VERSION ""

NS_ :

BS_:

BU_: TBOX Tester WCM MFS HUD CGW IHU

BO_ 3221225472 VECTOR__INDEPENDENT_SIG_MSG: 0 Vector__XXX
 SG_ IPM1_FLTempSwitchReq : 0|6@0+ (0.5,0) [16|30] "" Vector__XXX
 SG_ IHU_EPB_Cmd : 0|2@0+ (1,0) [0|3] "" Vector__XXX
 SG_ ABS_ESP_1_ESPSwitchStatus : 0|1@0+ (1,0) [0|1] "" Vector__XXX
 SG_ SET_Rmirror_UD_Locaton : 0|6@0+ (2,-2) [0|100] "%" Vector__XXX
 SG_ SET_Rmirror_LR_Locaton : 0|6@0+ (2,-2) [0|100] "%" Vector__XXX
 SG_ SET_Lmirror_UD_Locaton : 0|6@0+ (2,-2) [0|100] "%" Vector__XXX
 SG_ SET_Lmirror_LR_Locaton : 0|6@0+ (2,-2) [0|100] "%" Vector__XXX
 SG_ ATCM_AVM : 0|2@0+ (1,0) [0|3] "" Vector__XXX
 SG_ SET_DriverSeat_RearendUD : 0|2@0+ (1,0) [0|3] "" Vector__XXX
 SG_ SET_DriverSeat_FrontendUD : 0|2@0+ (1,0) [0|3] "" Vector__XXX
 SG_ SET_DriverSeat_BackFR : 0|2@0+ (1,0) [0|3] "" Vector__XXX
 SG_ SET_DriverSeat_FR : 0|2@0+ (1,0) [0|3] "" Vector__XXX
 SG_ RBCM_MFS_HeatSts : 0|1@0+ (1,0) [0|1] "Bit" Vector__XXX

BO_ 1360 DSM_1: 8 CGW
 SG_ SeatMemoryNO : 51|4@0+ (1,0) [0|15] ""  IHU
 SG_ DSM_2_MemorySound : 37|2@0+ (1,0) [0|3] ""  IHU
 SG_ BCM_3_Welcome_Seat_Sts : 35|2@0+ (1,0) [0|3] ""  IHU
 SG_ DSM_1_PassengerBlowSeatSts : 33|2@0+ (1,0) [0|3] ""  IHU
 SG_ SET_PassengerSeat_FrontendUD : 31|2@0+ (1,0) [0|3] ""  IHU
 SG_ SET_PassengerSeat_BackFR : 29|2@0+ (1,0) [0|3] ""  IHU
 SG_ SET_PassengerSeat_RearendUD : 27|2@0+ (1,0) [0|3] ""  IHU
 SG_ SET_PassengerSeat_FR : 25|2@0+ (1,0) [0|3] ""  IHU
 SG_ SET_DriverSeat_FrontendUD : 23|2@0+ (1,0) [0|3] ""  IHU
 SG_ SET_DriverSeat_BackFR : 21|2@0+ (1,0) [0|3] ""  IHU
 SG_ SET_DriverSeat_RearendUD : 19|2@0+ (1,0) [0|3] ""  IHU
 SG_ SET_DriverSeat_FR : 17|2@0+ (1,0) [0|3] ""  IHU
 SG_ Reserved : 15|4@0+ (1,0) [0|15] ""  IHU
 SG_ DSM_1_DeletePeronalSet_FB : 11|4@0+ (1,0) [0|15] ""  IHU
 SG_ DSM_1_PersonalSeatEn : 7|2@0+ (1,0) [0|3] ""  IHU
 SG_ DSM_1_PassengerHeatSeatSts : 5|2@0+ (1,0) [0|3] ""  IHU
 SG_ DSM_1_DriverBlowSeatSts : 3|2@0+ (1,0) [0|3] ""  IHU
 SG_ DSM_1_DriverHeatSeatSts : 1|2@0+ (1,0) [0|3] ""  IHU

BO_ 1313 TBOX_3: 3 CGW
 SG_ TBOX_3_RemotePhotograph : 3|2@0+ (1,0) [0|3] ""  IHU

BO_ 936 BCM_13: 8 CGW
 SG_ EBS_SOC : 23|8@0+ (1,0) [0|255] ""  IHU

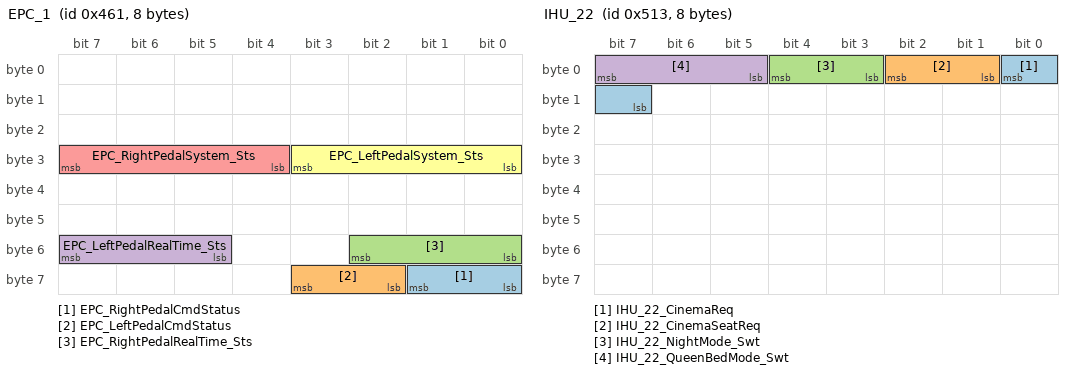
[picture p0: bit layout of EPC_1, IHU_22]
BO_ 1121 EPC_1: 8 CGW
 SG_ EPC_RightPedalCmdStatus : 57|2@0+ (1,0) [0|3] ""  IHU
 SG_ EPC_LeftPedalCmdStatus : 59|2@0+ (1,0) [0|3] ""  IHU
 SG_ EPC_RightPedalRealTime_Sts : 50|3@0+ (1,0) [0|7] ""  IHU
 SG_ EPC_LeftPedalRealTime_Sts : 55|3@0+ (1,0) [0|7] ""  IHU
 SG_ EPC_RightPedalSystem_Sts : 31|4@0+ (1,0) [0|15] ""  IHU
 SG_ EPC_LeftPedalSystem_Sts : 27|4@0+ (1,0) [0|15] ""  IHU

BO_ 916 BCM_1: 8 CGW
 SG_ Wash_Car_Status : 41|2@0+ (1,0) [0|3] ""  IHU

BO_ 1299 IHU_22: 8 IHU
 SG_ IHU_22_CinemaReq : 0|2@0+ (1,0) [0|3] ""  IHU
 SG_ IHU_22_CinemaSeatReq : 2|2@0+ (1,0) [0|3] ""  CGW
 SG_ IHU_22_NightMode_Swt : 4|2@0+ (1,0) [0|3] ""  CGW
 SG_ IHU_22_QueenBedMode_Swt : 7|3@0+ (1,0) [0|7] ""  CGW

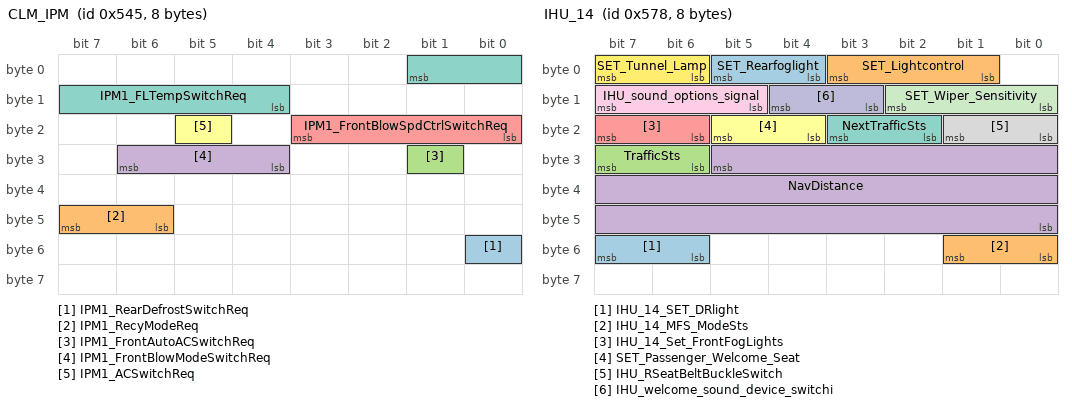
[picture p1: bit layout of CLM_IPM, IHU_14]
BO_ 1349 CLM_IPM: 8 CGW
 SG_ IPM1_RearDefrostSwitchReq : 48|1@0+ (1,0) [0|1] ""  IHU
 SG_ IPM1_RecyModeReq : 47|2@0+ (1,0) [0|3] ""  IHU
 SG_ IPM1_FrontAutoACSwitchReq : 25|1@0+ (1,0) [0|1] ""  IHU
 SG_ IPM1_FrontBlowModeSwitchReq : 30|3@0+ (1,0) [0|7] ""  IHU
 SG_ IPM1_FrontBlowSpdCtrlSwitchReq : 19|4@0+ (1,0) [0|15] ""  IHU
 SG_ IPM1_ACSwitchReq : 21|1@0+ (1,0) [0|1] ""  IHU
 SG_ IPM1_FLTempSwitchReq : 1|6@0+ (0.5,0) [16|30] ""  IHU

BO_ 1217 SCUM_1: 8 CGW
 SG_ ZeroPressureSeat_SportSts : 10|2@0+ (1,0) [0|3] ""  IHU
 SG_ ZeroPressure_SwSts : 12|2@0+ (1,0) [0|3] ""  IHU
 SG_ MRSeat_Antipinch : 13|1@0+ (1,0) [0|1] ""  IHU
 SG_ MRSeat_MemorySts : 57|2@0+ (1,0) [0|3] ""  IHU
 SG_ MLSeat_MemorySts : 59|2@0+ (1,0) [0|3] ""  IHU
 SG_ RestArea2Fb : 61|2@0+ (1,0) [0|3] ""  IHU
 SG_ MLSeat_MassageSts : 62|1@0+ (1,0) [0|1] ""  IHU
 SG_ MRSeat_LegUDSts : 49|3@0+ (1,0) [0|7] ""  IHU
 SG_ MRSeat_SideslipSts : 51|2@0+ (1,0) [0|3] ""  IHU
 SG_ MRSeat_BackSts : 53|2@0+ (1,0) [0|3] ""  IHU
 SG_ MRSeat_Sts : 55|2@0+ (1,0) [0|3] ""  IHU
 SG_ MLSeat_BackSts : 41|2@0+ (1,0) [0|3] ""  IHU
 SG_ MLSeat_Sts : 43|2@0+ (1,0) [0|3] ""  IHU
 SG_ MRSeat_MassageModeSts : 47|4@0+ (1,0) [0|15] ""  IHU
 SG_ MRSeat_MassageVibrationSts : 33|2@0+ (1,0) [0|3] ""  IHU
 SG_ MRSeat_HeatVentSts : 38|5@0+ (1,0) [0|31] ""  IHU
 SG_ MLSeat_MassageModeSts : 26|4@0+ (1,0) [0|15] ""  IHU
 SG_ MLSeat_MassageVibrationSts : 28|2@0+ (1,0) [0|3] ""  IHU
 SG_ MLSeat_HeatVentSts : 17|5@0+ (1,0) [0|31] ""  IHU
 SG_ MRSeat_ZerogravityModeSts : 19|2@0+ (1,0) [0|3] ""  IHU
 SG_ MRSeat_MassageSts : 20|1@0+ (1,0) [0|1] ""  IHU
 SG_ MRSeat_AngleSts : 22|2@0+ (1,0) [0|3] ""  IHU
 SG_ MRSeat_ZerovoltageSts : 8|2@0+ (1,0) [0|3] ""  IHU

BO_ 1400 IHU_14: 8 IHU
 SG_ IHU_14_SET_DRlight : 55|2@0+ (1,0) [0|2] ""  CGW
 SG_ IHU_14_MFS_ModeSts : 49|2@0+ (1,0) [0|2] ""  CGW
 SG_ TrafficSts : 31|2@0+ (1,0) [0|3] ""  CGW
 SG_ NavDistance : 29|22@0+ (20,0) [0|83886060] ""  CGW
 SG_ IHU_14_Set_FrontFogLights : 23|2@0+ (1,0) [0|3] ""  CGW
 SG_ SET_Passenger_Welcome_Seat : 21|2@0+ (1,0) [0|3] ""  CGW
 SG_ NextTrafficSts : 19|2@0+ (1,0) [0|3] ""  CGW
 SG_ IHU_RSeatBeltBuckleSwitch : 17|2@0+ (1,0) [0|3] ""  CGW
 SG_ IHU_sound_options_signal : 15|3@0+ (1,0) [0|5] ""  CGW
 SG_ IHU_welcome_sound_device_switchi : 12|2@0+ (1,0) [0|3] ""  CGW
 SG_ SET_Wiper_Sensitivity : 10|3@0+ (1,0) [0|7] ""  CGW
 SG_ SET_Tunnel_Lamp : 7|2@0+ (1,0) [0|2] ""  CGW
 SG_ SET_Rearfoglight : 5|2@0+ (1,0) [0|2] ""  CGW
 SG_ SET_Lightcontrol : 3|3@0+ (1,0) [0|4] ""  CGW

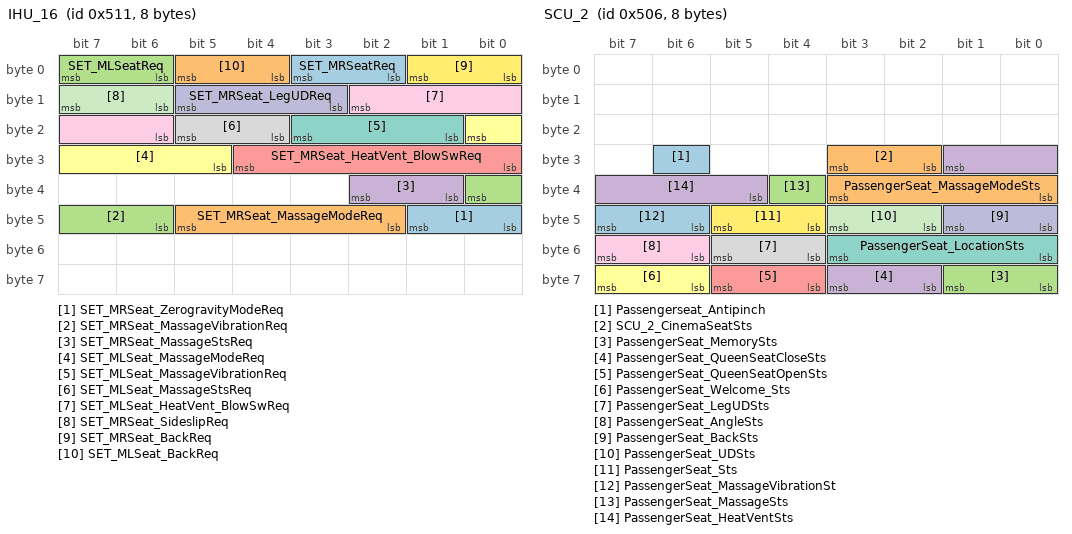
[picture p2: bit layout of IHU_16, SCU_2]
BO_ 1297 IHU_16: 8 IHU
 SG_ SET_MRSeat_ZerogravityModeReq : 41|2@0+ (1,0) [0|3] ""  CGW
 SG_ SET_MRSeat_MassageModeReq : 45|4@0+ (1,0) [0|15] ""  CGW
 SG_ SET_MRSeat_MassageVibrationReq : 32|3@0+ (1,0) [0|3] ""  CGW
 SG_ SET_MRSeat_MassageStsReq : 34|2@0+ (1,0) [0|3] ""  CGW
 SG_ SET_MRSeat_HeatVent_BlowSwReq : 28|5@0+ (1,0) [0|31] ""  CGW
 SG_ SET_MLSeat_MassageModeReq : 16|4@0+ (1,0) [0|15] ""  CGW
 SG_ SET_MLSeat_MassageVibrationReq : 19|3@0+ (1,0) [0|7] ""  CGW
 SG_ SET_MLSeat_MassageStsReq : 21|2@0+ (1,0) [0|3] ""  CGW
 SG_ SET_MLSeat_HeatVent_BlowSwReq : 10|5@0+ (1,0) [0|31] ""  CGW
 SG_ SET_MRSeat_LegUDReq : 13|3@0+ (1,0) [0|7] ""  CGW
 SG_ SET_MRSeat_SideslipReq : 15|2@0+ (1,0) [0|3] ""  CGW
 SG_ SET_MRSeat_BackReq : 1|2@0+ (1,0) [0|3] ""  CGW
 SG_ SET_MRSeatReq : 3|2@0+ (1,0) [0|3] ""  CGW
 SG_ SET_MLSeat_BackReq : 5|2@0+ (1,0) [0|3] ""  CGW
 SG_ SET_MLSeatReq : 7|2@0+ (1,0) [0|3] ""  CGW

BO_ 1286 SCU_2: 8 CGW
 SG_ Passengerseat_Antipinch : 30|1@0+ (1,0) [0|1] ""  IHU
 SG_ SCU_2_CinemaSeatSts : 27|2@0+ (1,0) [0|3] ""  IHU
 SG_ PassengerSeat_MemorySts : 57|2@0+ (1,0) [0|3] ""  IHU
 SG_ PassengerSeat_QueenSeatCloseSts : 59|2@0+ (1,0) [0|3] ""  IHU
 SG_ PassengerSeat_QueenSeatOpenSts : 61|2@0+ (1,0) [0|3] ""  IHU
 SG_ PassengerSeat_Welcome_Sts : 63|2@0+ (1,0) [0|3] ""  IHU
 SG_ PassengerSeat_LocationSts : 51|4@0+ (1,0) [0|15] ""  IHU
 SG_ PassengerSeat_LegUDSts : 53|2@0+ (1,0) [0|3] ""  IHU
 SG_ PassengerSeat_AngleSts : 55|2@0+ (1,0) [0|3] ""  IHU
 SG_ PassengerSeat_BackSts : 41|2@0+ (1,0) [0|3] ""  IHU
 SG_ PassengerSeat_UDSts : 43|2@0+ (1,0) [0|3] ""  IHU
 SG_ PassengerSeat_Sts : 45|2@0+ (1,0) [0|3] ""  IHU
 SG_ PassengerSeat_MassageVibrationSt : 47|2@0+ (1,0) [0|3] ""  IHU
 SG_ PassengerSeat_MassageModeSts : 35|4@0+ (1,0) [0|15] ""  IHU
 SG_ PassengerSeat_MassageSts : 36|1@0+ (1,0) [0|1] ""  IHU
 SG_ PassengerSeat_HeatVentSts : 25|5@0+ (1,0) [0|31] ""  IHU

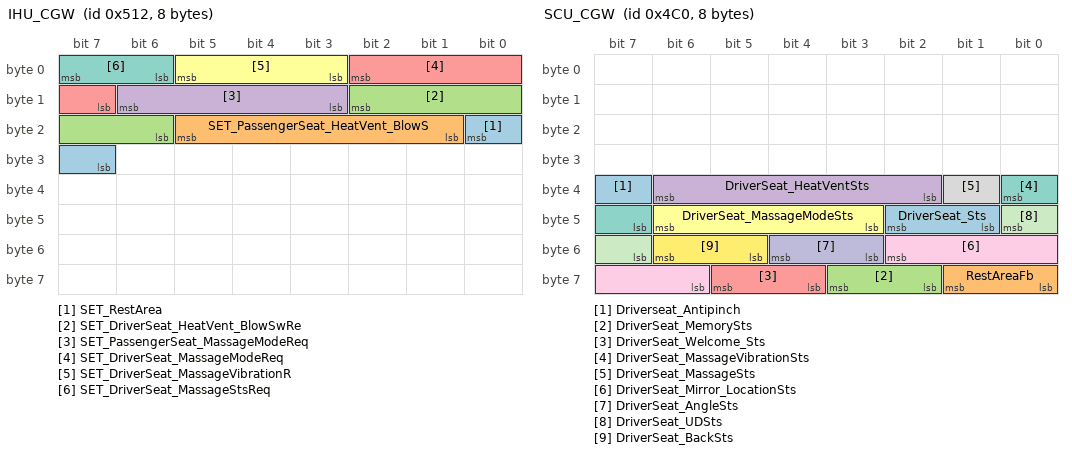
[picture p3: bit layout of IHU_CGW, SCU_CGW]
BO_ 1298 IHU_CGW: 8 IHU
 SG_ SET_RestArea : 16|2@0+ (1,0) [0|3] ""  CGW
 SG_ SET_PassengerSeat_HeatVent_BlowS : 21|5@0+ (1,0) [0|31] ""  CGW
 SG_ SET_DriverSeat_HeatVent_BlowSwRe : 10|5@0+ (1,0) [0|31] ""  CGW
 SG_ SET_PassengerSeat_MassageModeReq : 14|4@0+ (1,0) [0|15] ""  CGW
 SG_ SET_DriverSeat_MassageModeReq : 2|4@0+ (1,0) [0|15] ""  CGW
 SG_ SET_DriverSeat_MassageVibrationR : 5|3@0+ (1,0) [0|7] ""  CGW
 SG_ SET_DriverSeat_MassageStsReq : 7|2@0+ (1,0) [0|3] ""  CGW

BO_ 1216 SCU_CGW: 8 CGW
 SG_ Driverseat_Antipinch : 39|1@0+ (1,0) [0|1] ""  IHU
 SG_ RestAreaFb : 57|2@0+ (1,0) [0|3] ""  IHU
 SG_ DriverSeat_MemorySts : 59|2@0+ (1,0) [0|3] ""  IHU
 SG_ DriverSeat_HeatVentSts : 38|5@0+ (1,0) [0|31] ""  IHU
 SG_ DriverSeat_Welcome_Sts : 61|2@0+ (1,0) [0|3] ""  IHU
 SG_ DriverSeat_MassageModeSts : 46|4@0+ (1,0) [0|15] ""  IHU
 SG_ DriverSeat_MassageVibrationSts : 32|2@0+ (1,0) [0|3] ""  IHU
 SG_ DriverSeat_MassageSts : 33|1@0+ (1,0) [0|1] ""  IHU
 SG_ DriverSeat_Mirror_LocationSts : 50|5@0+ (1,0) [0|31] ""  IHU
 SG_ DriverSeat_AngleSts : 52|2@0+ (1,0) [0|3] ""  IHU
 SG_ DriverSeat_UDSts : 40|2@0+ (1,0) [0|3] ""  IHU
 SG_ DriverSeat_BackSts : 54|2@0+ (1,0) [0|2] ""  IHU
 SG_ DriverSeat_Sts : 42|2@0+ (1,0) [0|3] ""  IHU

BO_ 1444 CLM_11: 8 CGW
 SG_ Parking_air_conditioning_status : 14|2@0+ (1,0) [0|3] ""  IHU
 SG_ EvaporatortemperatureValidData : 15|1@0+ (1,0) [0|1] ""  IHU
 SG_ Evaporatortemperature : 7|8@0+ (1,-40) [-40|85] ""  IHU

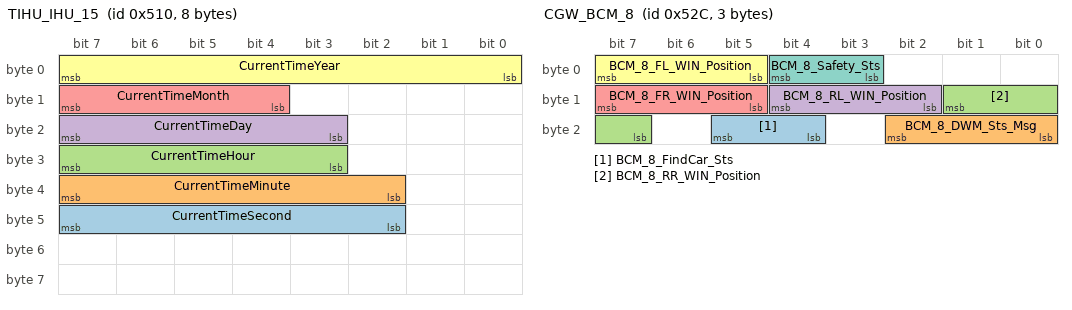
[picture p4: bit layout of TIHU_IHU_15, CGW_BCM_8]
BO_ 1296 TIHU_IHU_15: 8 IHU
 SG_ CurrentTimeSecond : 47|6@0+ (1,0) [0|59] ""  CGW
 SG_ CurrentTimeMinute : 39|6@0+ (1,0) [0|59] ""  CGW
 SG_ CurrentTimeHour : 31|5@0+ (1,0) [0|23] ""  CGW
 SG_ CurrentTimeDay : 23|5@0+ (1,0) [1|31] ""  CGW
 SG_ CurrentTimeMonth : 15|4@0+ (1,0) [1|12] ""  CGW
 SG_ CurrentTimeYear : 7|8@0+ (1,2000) [2000|2255] ""  CGW

BO_ 1480 TIHU_IHU_20: 8 IHU
 SG_ NextTrafficSts : 31|2@0+ (1,0) [0|3] ""  CGW
 SG_ TrafficSts : 17|2@0+ (1,0) [0|3] ""  CGW
 SG_ NavDistance : 7|22@0+ (20,0) [0|83886060] "m"  CGW

BO_ 1324 CGW_BCM_8: 3 CGW
 SG_ BCM_8_FindCar_Sts : 21|2@0+ (1,0) [0|3] ""  IHU
 SG_ BCM_8_DWM_Sts_Msg : 18|3@0+ (1,0) [0|7] ""  IHU
 SG_ BCM_8_RR_WIN_Position : 9|3@0+ (1,0) [0|7] ""  IHU
 SG_ BCM_8_RL_WIN_Position : 12|3@0+ (1,0) [0|7] ""  IHU
 SG_ BCM_8_FR_WIN_Position : 15|3@0+ (1,0) [0|7] ""  IHU
 SG_ BCM_8_FL_WIN_Position : 7|3@0+ (1,0) [0|7] ""  IHU
 SG_ BCM_8_Safety_Sts : 4|2@0+ (1,0) [0|3] ""  IHU

BO_ 1061 OBC_1: 8 CGW
 SG_ OBC_ChgVolt : 23|16@0+ (0.05,0) [0|1000] "V"  IHU
 SG_ OBC_ChgCurr : 7|16@0+ (0.05,0) [0|400] "A"  IHU

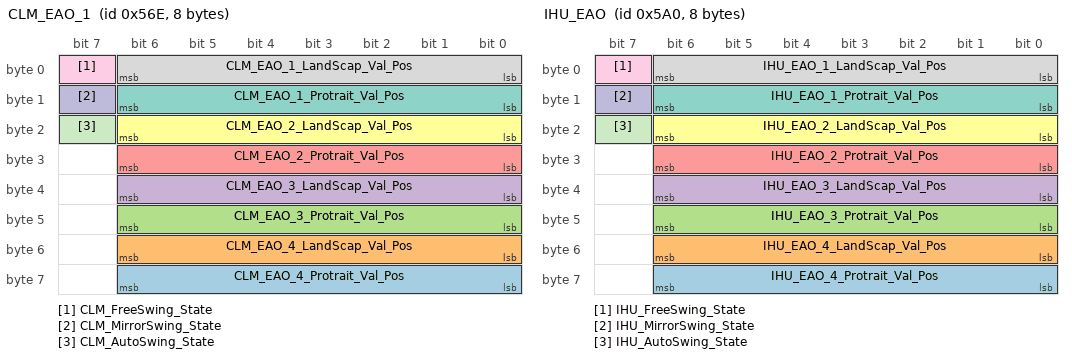
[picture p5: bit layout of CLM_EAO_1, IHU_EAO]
BO_ 1390 CLM_EAO_1: 8 CGW
 SG_ CLM_EAO_4_Protrait_Val_Pos : 62|7@0+ (1,0) [0|100] "%"  IHU
 SG_ CLM_EAO_4_LandScap_Val_Pos : 54|7@0+ (1,0) [0|100] "%"  IHU
 SG_ CLM_EAO_3_Protrait_Val_Pos : 46|7@0+ (1,0) [0|100] "%"  IHU
 SG_ CLM_EAO_3_LandScap_Val_Pos : 38|7@0+ (1,0) [0|100] "%"  IHU
 SG_ CLM_EAO_2_Protrait_Val_Pos : 30|7@0+ (1,0) [0|100] "%"  IHU
 SG_ CLM_EAO_2_LandScap_Val_Pos : 22|7@0+ (1,0) [0|100] "%"  IHU
 SG_ CLM_EAO_1_Protrait_Val_Pos : 14|7@0+ (1,0) [0|100] "%"  IHU
 SG_ CLM_EAO_1_LandScap_Val_Pos : 6|7@0+ (1,0) [0|100] "%"  IHU
 SG_ CLM_FreeSwing_State : 7|1@0+ (1,0) [0|1] "bit"  IHU
 SG_ CLM_MirrorSwing_State : 15|1@0+ (1,0) [0|1] "bit"  IHU
 SG_ CLM_AutoSwing_State : 23|1@0+ (1,0) [0|1] "bit"  IHU

BO_ 1440 IHU_EAO: 8 IHU
 SG_ IHU_EAO_4_Protrait_Val_Pos : 62|7@0+ (1,0) [0|100] ""  CGW
 SG_ IHU_EAO_4_LandScap_Val_Pos : 54|7@0+ (1,0) [0|100] ""  CGW
 SG_ IHU_EAO_3_Protrait_Val_Pos : 46|7@0+ (1,0) [0|100] ""  CGW
 SG_ IHU_EAO_3_LandScap_Val_Pos : 38|7@0+ (1,0) [0|100] ""  CGW
 SG_ IHU_EAO_2_Protrait_Val_Pos : 30|7@0+ (1,0) [0|100] ""  CGW
 SG_ IHU_EAO_2_LandScap_Val_Pos : 22|7@0+ (1,0) [0|100] ""  CGW
 SG_ IHU_EAO_1_Protrait_Val_Pos : 14|7@0+ (1,0) [0|100] ""  CGW
 SG_ IHU_EAO_1_LandScap_Val_Pos : 6|7@0+ (1,0) [0|100] ""  CGW
 SG_ IHU_FreeSwing_State : 7|1@0+ (1,0) [0|1] ""  CGW
 SG_ IHU_MirrorSwing_State : 15|1@0+ (1,0) [0|1] ""  CGW
 SG_ IHU_AutoSwing_State : 23|1@0+ (1,0) [0|1] ""  CGW

BO_ 1534 CGW_CLM_UVC: 8 CGW
 SG_ CEM_3_UVC_LuminanceBf : 47|3@0+ (1,0) [0|7] ""  IHU
 SG_ CEM_3_UVC_WorkingBf : 36|2@0+ (1,0) [0|3] ""  IHU
 SG_ CLM_CoolantFillsts : 0|1@0+ (1,0) [0|1] ""  IHU

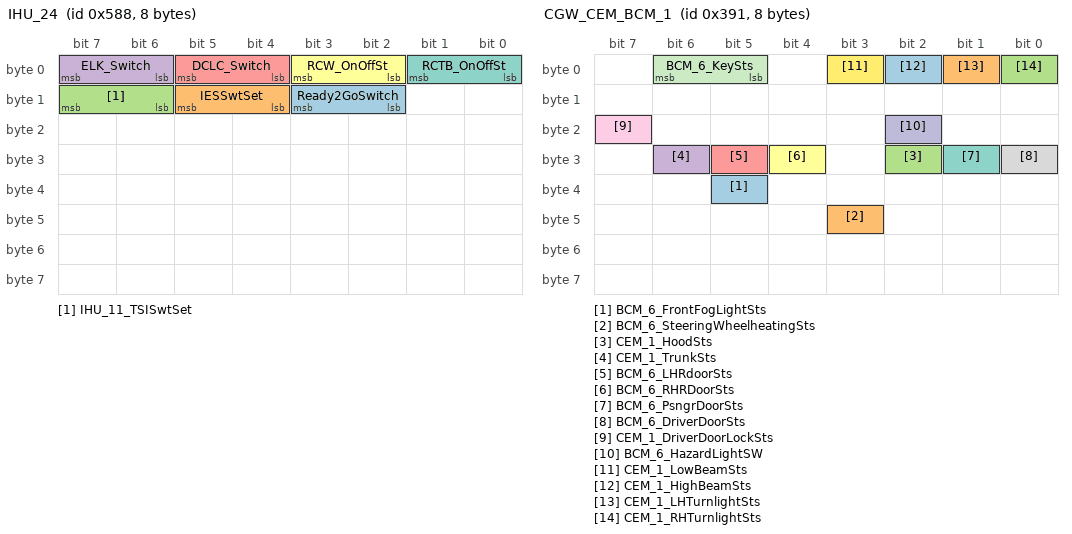
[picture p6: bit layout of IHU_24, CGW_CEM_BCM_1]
BO_ 1416 IHU_24: 8 IHU
 SG_ Ready2GoSwitch : 11|2@0+ (1,0) [0|3] ""  CGW
 SG_ IESSwtSet : 13|2@0+ (1,0) [0|3] ""  CGW
 SG_ IHU_11_TSISwtSet : 15|2@0+ (1,0) [0|3] ""  CGW
 SG_ ELK_Switch : 7|2@0+ (1,0) [0|3] ""  CGW
 SG_ DCLC_Switch : 5|2@0+ (1,0) [0|3] ""  CGW
 SG_ RCW_OnOffSt : 3|2@0+ (1,0) [0|3] ""  CGW
 SG_ RCTB_OnOffSt : 1|2@0+ (1,0) [0|3] ""  CGW

BO_ 1330 IHU_29: 8 IHU
 SG_ IHU_29_DchaSet : 57|2@0+ (1,0) [0|3] ""  CGW

BO_ 805 MFS_4: 6 CGW
 SG_ MFS4_AnswerPhone : 23|2@0+ (1,0) [0|3] ""  IHU
 SG_ MFS4_HangUpPhone : 25|2@0+ (1,0) [0|3] ""  IHU
 SG_ MFS4_AVM : 15|2@0+ (1,0) [0|3] ""  IHU
 SG_ MFS4_IHU_Confirm : 13|2@0+ (1,0) [0|3] ""  IHU
 SG_ MFS4_Heartrate : 47|8@0+ (1,0) [0|255] ""  IHU
 SG_ MFS4_Next : 37|2@0+ (1,0) [0|3] ""  IHU
 SG_ MFS4_Previous : 35|2@0+ (1,0) [0|3] ""  IHU
 SG_ MFS4_Answer_Hang_Up_Phone : 33|2@0+ (1,0) [0|3] ""  IHU
 SG_ MFS4_Voice_Activation : 21|2@0+ (1,0) [0|3] ""  IHU
 SG_ MFS4_Voice_Reduce : 31|3@0+ (1,0) [0|7] ""  IHU
 SG_ MFS4_Voice_Add : 28|3@0+ (1,0) [0|7] ""  IHU
 SG_ MFS4_Mute : 19|2@0+ (1,0) [0|3] ""  IHU
 SG_ MFS4_IHU_Right : 11|2@0+ (1,0) [0|3] ""  IHU
 SG_ MFS4_IHU_Left : 9|2@0+ (1,0) [0|3] ""  IHU
 SG_ MFS4_IHU_Down_Zoom_Out : 7|2@0+ (1,0) [0|3] ""  IHU
 SG_ MFS4_IHU_UP_Zoom_In : 5|2@0+ (1,0) [0|3] ""  IHU
 SG_ MFS4_Menu : 3|2@0+ (1,0) [0|3] ""  IHU

BO_ 896 CGW_EPS_1: 3 TBOX
 SG_ EPS_1_EPSModeSts : 15|2@0+ (1,0) [0|3] ""  IHU
 SG_ EPS_1_EPSModeSts_PHEV : 9|2@0+ (1,0) [0|3] ""  IHU
 SG_ EPS_G_RecoverableFault : 23|5@0+ (1,0) [0|31] ""  IHU
 SG_ EPS_1_AssociWithDriverModeSts : 11|1@0+ (1,0) [0|1] ""  IHU

BO_ 913 CGW_CEM_BCM_1: 8 CGW
 SG_ BCM_6_FrontFogLightSts : 37|1@0+ (1,0) [0|1] ""  IHU
 SG_ BCM_6_SteeringWheelheatingSts : 43|1@0+ (1,0) [0|1] ""  IHU
 SG_ CEM_1_HoodSts : 26|1@0+ (1,0) [0|1] ""  IHU
 SG_ CEM_1_TrunkSts : 30|1@0+ (1,0) [0|1] ""  IHU
 SG_ BCM_6_LHRdoorSts : 29|1@0+ (1,0) [0|1] ""  IHU
 SG_ BCM_6_RHRDoorSts : 28|1@0+ (1,0) [0|1] ""  IHU
 SG_ BCM_6_PsngrDoorSts : 25|1@0+ (1,0) [0|1] ""  IHU
 SG_ BCM_6_DriverDoorSts : 24|1@0+ (1,0) [0|1] ""  IHU
 SG_ CEM_1_DriverDoorLockSts : 23|1@0+ (1,0) [0|1] ""  IHU
 SG_ BCM_6_HazardLightSW : 18|1@0+ (1,0) [0|1] ""  IHU
 SG_ BCM_6_KeySts : 6|2@0+ (1,0) [0|3] ""  IHU
 SG_ CEM_1_LowBeamSts : 3|1@0+ (1,0) [0|1] ""  IHU
 SG_ CEM_1_HighBeamSts : 2|1@0+ (1,0) [0|1] ""  IHU
 SG_ CEM_1_LHTurnlightSts : 1|1@0+ (1,0) [0|1] ""  IHU
 SG_ CEM_1_RHTurnlightSts : 0|1@0+ (1,0) [0|1] ""  IHU

BO_ 554 AVM_APA_1: 8 CGW
 SG_ APA_1_CRC : 63|8@0+ (1,0) [0|255] ""  IHU
 SG_ APA_1_Reserved2 : 29|26@0+ (1,0) [0|33554431] ""  IHU
 SG_ APA_1_AliveCounter : 51|4@0+ (1,0) [0|15] ""  IHU
 SG_ AVM_APA_1_Active : 6|1@0+ (1,0) [0|1] ""  IHU

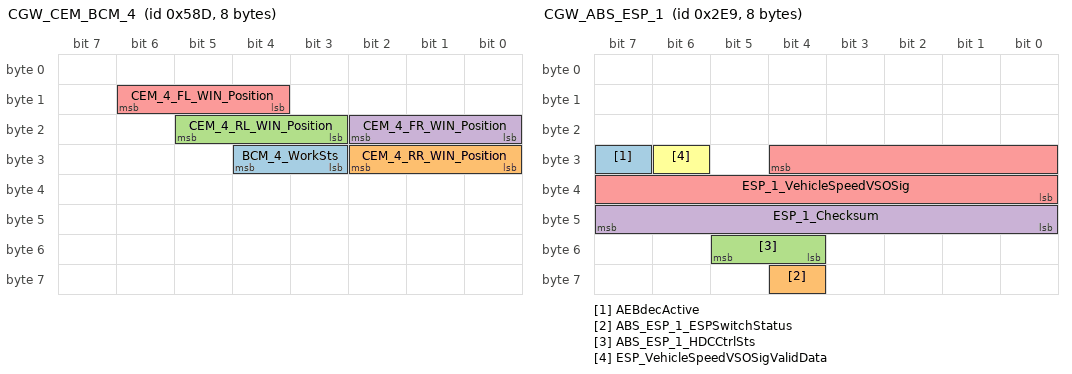
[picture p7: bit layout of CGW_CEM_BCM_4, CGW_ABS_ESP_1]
BO_ 1421 CGW_CEM_BCM_4: 8 CGW
 SG_ BCM_4_WorkSts : 28|2@0+ (1,0) [0|3] ""  IHU
 SG_ CEM_4_RR_WIN_Position : 26|3@0+ (1,0) [0|7] ""  IHU
 SG_ CEM_4_RL_WIN_Position : 21|3@0+ (1,0) [0|7] ""  IHU
 SG_ CEM_4_FR_WIN_Position : 18|3@0+ (1,0) [0|7] ""  IHU
 SG_ CEM_4_FL_WIN_Position : 14|3@0+ (1,0) [0|7] ""  IHU

BO_ 1253 CGW_ABS_ESP_5: 8 TBOX
 SG_ ESP_5_LHFPulseCounter : 44|13@0+ (1,0) [0|8191] ""  IHU
 SG_ ESP_5_RHFPulseCounter : 25|13@0+ (1,0) [0|8191] ""  IHU
 SG_ ESP_5_RHRPulseCounter : 23|13@0+ (1,0) [0|8191] ""  IHU
 SG_ ESP_5_LHRPulseCounter : 7|13@0+ (1,0) [0|8191] ""  IHU

BO_ 745 CGW_ABS_ESP_1: 8 CGW
 SG_ AEBdecActive : 31|1@0+ (1,0) [0|1] ""  IHU
 SG_ ABS_ESP_1_ESPSwitchStatus : 60|1@0+ (1,0) [0|1] ""  IHU
 SG_ ABS_ESP_1_HDCCtrlSts : 53|2@0+ (1,0) [0|3] ""  IHU
 SG_ ESP_1_Checksum : 47|8@0+ (1,0) [0|255] ""  IHU
 SG_ ESP_1_VehicleSpeedVSOSig : 28|13@0+ (0.0625,0) [0|511.9375] "km/h"  IHU
 SG_ ESP_VehicleSpeedVSOSigValidData : 30|1@0+ (1,0) [0|1] ""  IHU

BO_ 250 EMS_1: 8 CGW
 SG_ CruiseControlStatus : 38|2@0+ (1,0) [0|3] ""  IHU
 SG_ GasPedalPositionInvalidData : 39|1@0+ (1,0) [0|1] ""  IHU
 SG_ EMS_1_GasPedalPosition : 31|8@0+ (1,0) [0|255] ""  IHU

BO_ 932 CGW_ABS_ESP_18: 8 CGW
 SG_ CCO_Active : 1|2@0+ (1,0) [0|3] ""  IHU

BO_ 768 TCU_2_7DCT: 8 CGW
 SG_ TCU_2NEWDriverMode_7 : 10|3@0+ (1,0) [0|7] ""  IHU

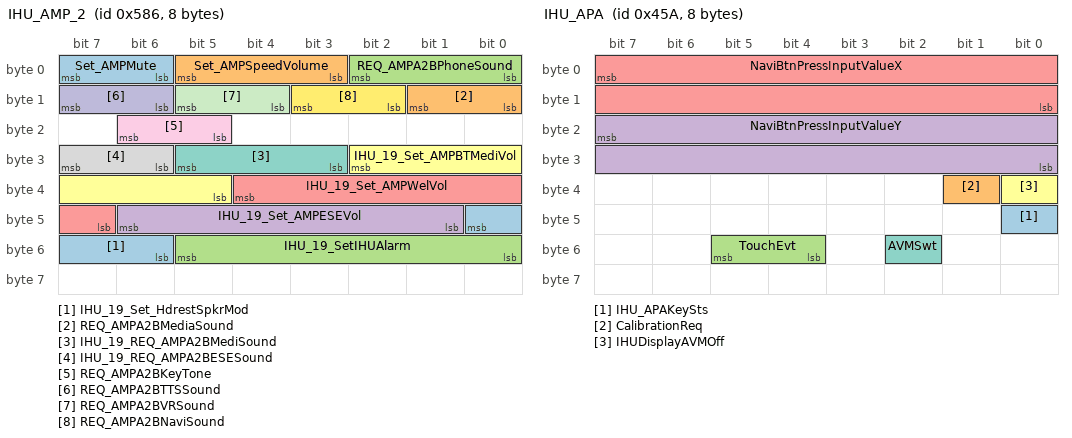
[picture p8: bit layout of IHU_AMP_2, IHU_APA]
BO_ 1414 IHU_AMP_2: 8 IHU
 SG_ IHU_19_Set_HdrestSpkrMod : 40|3@0+ (1,0) [0|7] ""  CGW
 SG_ REQ_AMPA2BMediaSound : 9|2@0+ (1,0) [0|3] ""  CGW
 SG_ IHU_19_SetIHUAlarm : 53|6@0+ (1,0) [0|63] ""  CGW
 SG_ IHU_19_Set_AMPESEVol : 46|6@0+ (1,0) [0|63] ""  CGW
 SG_ IHU_19_Set_AMPWelVol : 36|6@0+ (1,0) [0|63] ""  CGW
 SG_ IHU_19_Set_AMPBTMediVol : 26|6@0+ (1,0) [0|63] ""  CGW
 SG_ IHU_19_REQ_AMPA2BMediSound : 29|3@0+ (1,0) [0|7] ""  CGW
 SG_ IHU_19_REQ_AMPA2BESESound : 31|2@0+ (1,0) [0|3] ""  CGW
 SG_ REQ_AMPA2BKeyTone : 22|2@0+ (1,0) [0|3] ""  CGW
 SG_ REQ_AMPA2BTTSSound : 15|2@0+ (1,0) [0|3] ""  CGW
 SG_ REQ_AMPA2BVRSound : 13|2@0+ (1,0) [0|3] ""  CGW
 SG_ REQ_AMPA2BNaviSound : 11|2@0+ (1,0) [0|3] ""  CGW
 SG_ Set_AMPMute : 7|2@0+ (1,0) [0|3] ""  CGW
 SG_ Set_AMPSpeedVolume : 5|3@0+ (1,0) [0|7] ""  CGW
 SG_ REQ_AMPA2BPhoneSound : 2|3@0+ (1,0) [0|7] ""  CGW

BO_ 1413 IHU_AMP_1: 8 IHU
 SG_ Set_AMPAlarmVolume : 63|4@0+ (1,0) [0|15] ""  CGW
 SG_ Set_AMPLoudness : 59|2@0+ (1,0) [0|3] ""  CGW
 SG_ Set_AMPLiveAcoustics : 57|2@0+ (1,0) [0|3] ""  CGW
 SG_ Set_AMPSoundFieldFader : 55|4@0+ (1,0) [0|15] ""  CGW
 SG_ Set_AMPSoundFieldBalance : 51|4@0+ (1,0) [0|15] ""  CGW
 SG_ Set_AMPSoundEffectTreble : 47|4@0+ (1,0) [0|15] ""  CGW
 SG_ Set_AMPSoundEffectMidrange : 43|4@0+ (1,0) [0|15] ""  CGW
 SG_ Set_AMPSoundEffectBass : 39|4@0+ (1,0) [0|15] ""  CGW
 SG_ Set_AMPSoundEffect : 35|4@0+ (1,0) [0|15] ""  CGW
 SG_ Set_AMPRestoreDefaults : 31|2@0+ (1,0) [0|3] ""  CGW
 SG_ Set_AMPDefaultVolume : 29|6@0+ (1,0) [0|63] ""  CGW
 SG_ Set_AMPSoundFocus : 23|3@0+ (1,0) [0|7] ""  CGW
 SG_ Set_AMPPhoneVolume : 20|5@0+ (1,0) [0|31] ""  CGW
 SG_ Set_AMPMediaVolume : 15|6@0+ (1,0) [0|63] ""  CGW
 SG_ Set_AMPKeyTone : 9|2@0+ (1,0) [0|3] ""  CGW
 SG_ Set_AMPVRVolume : 7|4@0+ (1,0) [0|15] ""  CGW
 SG_ Set_AMPNaviVolume : 3|4@0+ (1,0) [0|15] ""  CGW

BO_ 923 AMP_2: 8 CGW
 SG_ STAT_A2B_MUTE_IN : 63|1@0+ (1,0) [0|1] ""  IHU
 SG_ STAT_AMPSlot7 : 62|1@0+ (1,0) [0|1] ""  IHU
 SG_ STAT_AMPSlot6 : 61|1@0+ (1,0) [0|1] ""  IHU
 SG_ STAT_AMPSlot4_5 : 60|1@0+ (1,0) [0|1] ""  IHU
 SG_ STAT_AMPSlot3 : 59|1@0+ (1,0) [0|1] ""  IHU
 SG_ STAT_AMPSlot2 : 58|1@0+ (1,0) [0|1] ""  IHU
 SG_ STAT_AMPSlot1 : 57|1@0+ (1,0) [0|1] ""  IHU
 SG_ STAT_AMPSlot0 : 56|1@0+ (1,0) [0|1] ""  IHU
 SG_ STAT_AMPA2BESESound : 53|2@0+ (1,0) [0|3] ""  IHU
 SG_ STAT_IHU19_AMPA2BMediSound : 51|3@0+ (1,0) [0|7] ""  IHU
 SG_ STAT_ICMAlarm : 48|1@0+ (1,0) [0|1] ""  IHU
 SG_ STAT_AMPA2BPhoneSound : 47|2@0+ (1,0) [0|3] ""  IHU
 SG_ STAT_AMPA2BTTSSound : 45|2@0+ (1,0) [0|3] ""  IHU
 SG_ STAT_AMPA2BNaviSound : 43|2@0+ (1,0) [0|3] ""  IHU
 SG_ STAT_AMPA2BKeyTone : 41|2@0+ (1,0) [0|3] ""  IHU
 SG_ STAT_AMPTEMP : 15|3@0+ (1,0) [0|7] ""  IHU
 SG_ EAMP_2_HdrestSpkrMod : 2|3@0+ (1,0) [0|7] ""  IHU
 SG_ STAT_AMPESEVol : 16|6@0+ (1,0) [0|63] ""  IHU
 SG_ STAT_AMPWelVol : 22|6@0+ (1,0) [0|63] ""  IHU
 SG_ STAT_AMPBTMediVol : 12|6@0+ (1,0) [0|63] ""  IHU
 SG_ STAT_AMPMute : 7|2@0+ (1,0) [0|3] ""  IHU
 SG_ STAT_AMPSpeedVolume : 5|3@0+ (1,0) [0|7] ""  IHU

BO_ 922 AMP_1: 8 CGW
 SG_ STAT_AMPAlarmVolume : 63|4@0+ (1,0) [0|15] ""  IHU
 SG_ STAT_AMPLoudness : 59|2@0+ (1,0) [0|3] ""  IHU
 SG_ STAT_AMPLiveAcoustics : 57|2@0+ (1,0) [0|3] ""  IHU
 SG_ STAT_AMPSoundFieldFader : 55|4@0+ (1,0) [0|15] ""  IHU
 SG_ STAT_AMPSoundFieldBalance : 51|4@0+ (1,0) [0|15] ""  IHU
 SG_ STAT_AMPSoundEffectTreble : 47|4@0+ (1,0) [0|15] ""  IHU
 SG_ STAT_AMPSoundEffectMidrange : 43|4@0+ (1,0) [0|15] ""  IHU
 SG_ STAT_AMPSoundEffectBass : 39|4@0+ (1,0) [0|15] ""  IHU
 SG_ STAT_AMPSoundEffect : 35|4@0+ (1,0) [0|15] ""  IHU
 SG_ STAT_AMPRestoreDefaults : 31|2@0+ (1,0) [0|3] ""  IHU
 SG_ STAT_AMPDefaultVolume : 29|6@0+ (1,0) [0|63] ""  IHU
 SG_ STAT_AMPSoundFocus : 23|3@0+ (1,0) [0|7] ""  IHU
 SG_ STAT_AMPPhoneVolume : 20|5@0+ (1,0) [0|31] ""  IHU
 SG_ STAT_AMPMediaVolume : 15|6@0+ (1,0) [0|63] ""  IHU
 SG_ STAT_AMPKeyTone : 9|2@0+ (1,0) [0|3] ""  IHU
 SG_ STAT_AMPVRVolume : 7|4@0+ (1,0) [0|15] ""  IHU
 SG_ STAT_AMPNaviVolume : 3|4@0+ (1,0) [0|15] ""  IHU

BO_ 1114 IHU_APA: 8 IHU
 SG_ IHU_APAKeySts : 40|1@0+ (1,0) [0|1] "Bit"  CGW
 SG_ CalibrationReq : 33|1@0+ (1,0) [0|1] "Bit"  CGW
 SG_ TouchEvt : 53|2@0+ (1,0) [0|3] "Bit"  CGW
 SG_ NaviBtnPressInputValueY : 23|16@0+ (1,0) [0|65535] "Bit"  CGW
 SG_ NaviBtnPressInputValueX : 7|16@0+ (1,0) [0|65535] "Bit"  CGW
 SG_ IHUDisplayAVMOff : 32|1@0+ (1,0) [0|1] "Bit"  CGW
 SG_ AVMSwt : 50|1@0+ (1,0) [0|1] "Bit"  CGW

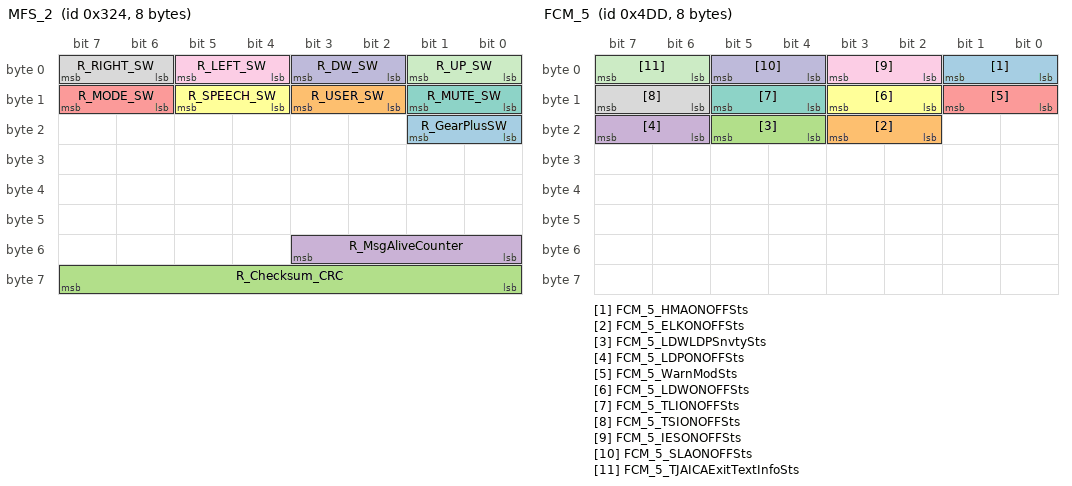
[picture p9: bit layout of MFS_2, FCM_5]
BO_ 804 MFS_2: 8 MFS
 SG_ R_GearPlusSW : 17|2@0+ (1,0) [0|3] ""  IHU
 SG_ R_USER_SW : 11|2@0+ (1,0) [0|3] ""  IHU
 SG_ R_Checksum_CRC : 63|8@0+ (1,0) [0|255] ""  IHU
 SG_ R_MsgAliveCounter : 51|4@0+ (1,0) [0|15] ""  IHU
 SG_ R_MODE_SW : 15|2@0+ (1,0) [0|3] ""  IHU
 SG_ R_SPEECH_SW : 13|2@0+ (1,0) [0|3] ""  IHU
 SG_ R_MUTE_SW : 9|2@0+ (1,0) [0|3] ""  IHU
 SG_ R_RIGHT_SW : 7|2@0+ (1,0) [0|3] ""  IHU
 SG_ R_LEFT_SW : 5|2@0+ (1,0) [0|3] ""  IHU
 SG_ R_DW_SW : 3|2@0+ (1,0) [0|3] ""  IHU
 SG_ R_UP_SW : 1|2@0+ (1,0) [0|3] ""  IHU

BO_ 1240 CGW_EMS_3_G: 8 CGW
 SG_ EMS_3_G_electric_fan_on_feedback : 31|8@0+ (1,0) [0|255] "%"  IHU

BO_ 1245 FCM_5: 8 CGW
 SG_ FCM_5_HMAONOFFSts : 1|2@0+ (1,0) [0|3] "bit"  IHU
 SG_ FCM_5_ELKONOFFSts : 19|2@0+ (1,0) [0|3] ""  IHU
 SG_ FCM_5_LDWLDPSnvtySts : 21|2@0+ (1,0) [0|3] ""  IHU
 SG_ FCM_5_LDPONOFFSts : 23|2@0+ (1,0) [0|3] ""  IHU
 SG_ FCM_5_WarnModSts : 9|2@0+ (1,0) [0|3] ""  IHU
 SG_ FCM_5_LDWONOFFSts : 11|2@0+ (1,0) [0|3] ""  IHU
 SG_ FCM_5_TLIONOFFSts : 13|2@0+ (1,0) [0|3] ""  IHU
 SG_ FCM_5_TSIONOFFSts : 15|2@0+ (1,0) [0|3] ""  IHU
 SG_ FCM_5_IESONOFFSts : 3|2@0+ (1,0) [0|3] ""  IHU
 SG_ FCM_5_SLAONOFFSts : 5|2@0+ (1,0) [0|3] ""  IHU
 SG_ FCM_5_TJAICAExitTextInfoSts : 7|2@0+ (1,0) [0|3] ""  IHU

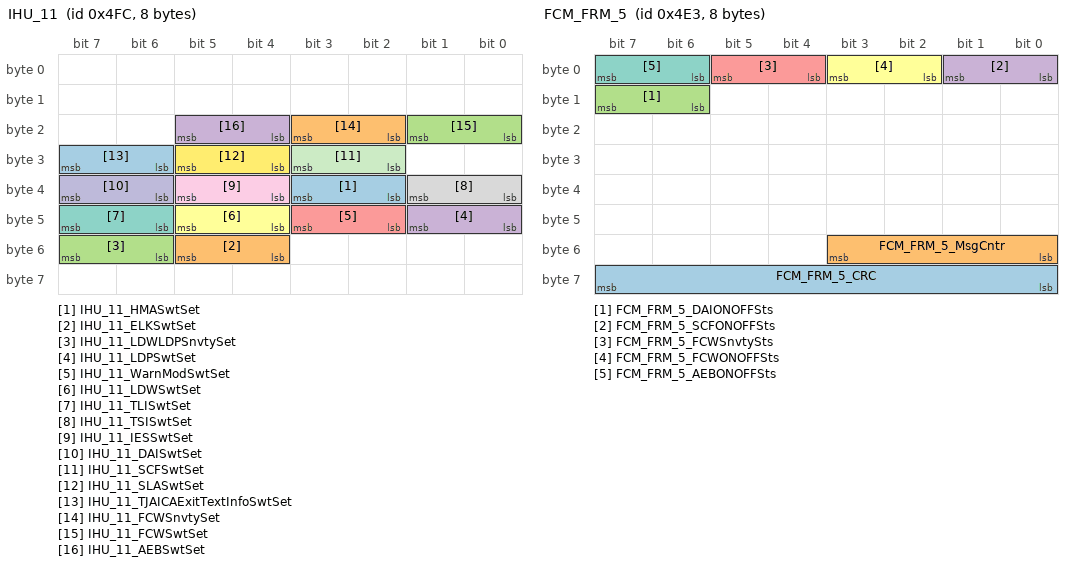
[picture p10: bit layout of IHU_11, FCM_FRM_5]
BO_ 1276 IHU_11: 8 IHU
 SG_ IHU_11_HMASwtSet : 35|2@0+ (1,0) [0|3] "bit"  CGW
 SG_ IHU_11_ELKSwtSet : 53|2@0+ (1,0) [0|3] ""  CGW
 SG_ IHU_11_LDWLDPSnvtySet : 55|2@0+ (1,0) [0|3] ""  CGW
 SG_ IHU_11_LDPSwtSet : 41|2@0+ (1,0) [0|3] ""  CGW
 SG_ IHU_11_WarnModSwtSet : 43|2@0+ (1,0) [0|3] ""  CGW
 SG_ IHU_11_LDWSwtSet : 45|2@0+ (1,0) [0|3] ""  CGW
 SG_ IHU_11_TLISwtSet : 47|2@0+ (1,0) [0|3] ""  CGW
 SG_ IHU_11_TSISwtSet : 33|2@0+ (1,0) [0|3] ""  CGW
 SG_ IHU_11_IESSwtSet : 37|2@0+ (1,0) [0|3] ""  CGW
 SG_ IHU_11_DAISwtSet : 39|2@0+ (1,0) [0|3] ""  CGW
 SG_ IHU_11_SCFSwtSet : 27|2@0+ (1,0) [0|3] ""  CGW
 SG_ IHU_11_SLASwtSet : 29|2@0+ (1,0) [0|3] ""  CGW
 SG_ IHU_11_TJAICAExitTextInfoSwtSet : 31|2@0+ (1,0) [0|3] ""  CGW
 SG_ IHU_11_FCWSnvtySet : 19|2@0+ (1,0) [0|3] ""  CGW
 SG_ IHU_11_FCWSwtSet : 17|2@0+ (1,0) [0|3] ""  CGW
 SG_ IHU_11_AEBSwtSet : 21|2@0+ (1,0) [0|3] ""  CGW

BO_ 1251 FCM_FRM_5: 8 CGW
 SG_ FCM_FRM_5_CRC : 63|8@0+ (1,0) [0|255] ""  IHU
 SG_ FCM_FRM_5_MsgCntr : 51|4@0+ (1,0) [0|15] ""  IHU
 SG_ FCM_FRM_5_DAIONOFFSts : 15|2@0+ (1,0) [0|3] ""  IHU
 SG_ FCM_FRM_5_SCFONOFFSts : 1|2@0+ (1,0) [0|3] ""  IHU
 SG_ FCM_FRM_5_FCWSnvtySts : 5|2@0+ (1,0) [0|3] ""  IHU
 SG_ FCM_FRM_5_FCWONOFFSts : 3|2@0+ (1,0) [0|3] ""  IHU
 SG_ FCM_FRM_5_AEBONOFFSts : 7|2@0+ (1,0) [0|3] ""  IHU

BO_ 1262 RLC_1: 8 CGW
 SG_ LightShowSts : 22|5@0+ (1,0) [0|31] ""  IHU

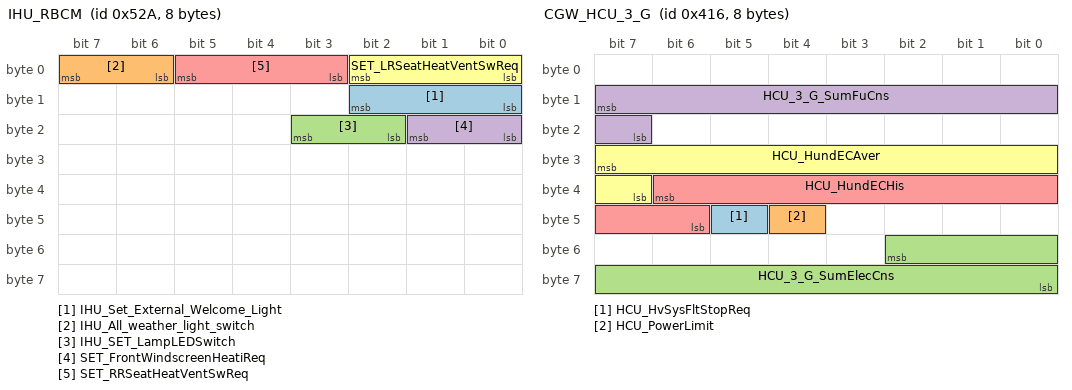
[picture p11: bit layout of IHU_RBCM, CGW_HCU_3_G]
BO_ 1322 IHU_RBCM: 8 IHU
 SG_ IHU_Set_External_Welcome_Light : 10|3@0+ (1,0) [0|7] ""  CGW
 SG_ IHU_All_weather_light_switch : 7|2@0+ (1,0) [0|3] "Bit"  CGW
 SG_ IHU_SET_LampLEDSwitch : 19|2@0+ (1,0) [0|3] "Bit"  CGW
 SG_ SET_FrontWindscreenHeatiReq : 17|2@0+ (1,0) [0|3] "Bit"  CGW
 SG_ SET_RRSeatHeatVentSwReq : 5|3@0+ (1,0) [0|7] "Bit"  CGW
 SG_ SET_LRSeatHeatVentSwReq : 2|3@0+ (1,0) [0|7] "Bit"  CGW

BO_ 295 YAS_1: 8 CGW
 SG_ YAS_1_LateraAccaleleration : 23|16@0+ (0.001,-2) [-2|2] "G"  IHU

BO_ 1111 AVAS_1: 8 CGW
 SG_ AVAS_FunctionSts : 4|1@0+ (1,0) [0|1] ""  IHU

BO_ 1067 OBC_3: 8 CGW
 SG_ OBC_discharge_connect_state : 19|1@0+ (1,0) [0|1] ""  IHU
 SG_ OBC_DischgSts : 42|3@0+ (1,0) [0|7] ""  IHU
 SG_ OBC_CC_ConnectSts : 34|2@0+ (1,0) [0|3] ""  IHU

BO_ 1057 HCU_EMS_2_G: 8 CGW
 SG_ LimitSpeedSts : 10|3@0+ (1,0) [0|7] ""  IHU
 SG_ CruiseLimitSpeedValue : 7|13@0+ (0.0625,0) [0|511.875] "Km/h"  IHU

BO_ 1046 CGW_HCU_3_G: 8 CGW
 SG_ HCU_HvSysFltStopReq : 45|1@0+ (1,0) [0|1] ""  IHU
 SG_ HCU_PowerLimit : 44|1@0+ (1,0) [0|1] ""  IHU
 SG_ HCU_3_G_SumElecCns : 50|11@0+ (0.1,-100) [-100|100] "Kw.h/km"  IHU
 SG_ HCU_3_G_SumFuCns : 15|9@0+ (0.1,0) [0|51] "L/km"  IHU
 SG_ HCU_HundECHis : 38|9@0+ (0.1,0) [0|51] "Kwh"  IHU
 SG_ HCU_HundECAver : 31|9@0+ (0.1,0) [0|51] "Kwh"  IHU

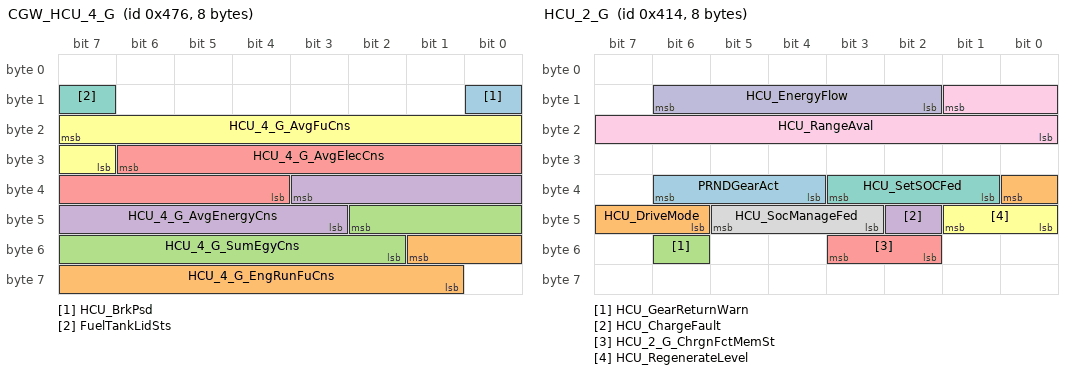
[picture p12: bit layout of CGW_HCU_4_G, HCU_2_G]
BO_ 1142 CGW_HCU_4_G: 8 CGW
 SG_ HCU_BrkPsd : 8|1@0+ (1,0) [0|1] "Bit"  IHU
 SG_ HCU_4_G_EngRunFuCns : 49|9@0+ (0.1,0) [0|50] "L/km"  IHU
 SG_ HCU_4_G_SumEgyCns : 42|9@0+ (0.1,0) [0|50] "L/km"  IHU
 SG_ HCU_4_G_AvgEnergyCns : 35|9@0+ (0.1,0) [0|50] "L/km"  IHU
 SG_ HCU_4_G_AvgElecCns : 30|11@0+ (0.1,-100) [-100|100] "kW.h/km"  IHU
 SG_ HCU_4_G_AvgFuCns : 23|9@0+ (0.1,0) [0|50] "L/km"  IHU
 SG_ FuelTankLidSts : 15|1@0+ (1,0) [0|1] ""  IHU

BO_ 1044 HCU_2_G: 8 CGW
 SG_ PRNDGearAct : 38|3@0+ (1,0) [0|7] ""  IHU
 SG_ HCU_DriveMode : 32|3@0+ (1,0) [0|7] ""  IHU
 SG_ HCU_GearReturnWarn : 54|1@0+ (1,0) [0|1] ""  IHU
 SG_ HCU_ChargeFault : 42|1@0+ (1,0) [0|1] ""  IHU
 SG_ HCU_2_G_ChrgnFctMemSt : 51|2@0+ (1,0) [0|3] ""  IHU
 SG_ HCU_RegenerateLevel : 41|2@0+ (1,0) [0|3] ""  IHU
 SG_ HCU_SetSOCFed : 35|3@0+ (1,0) [0|7] ""  IHU
 SG_ HCU_SocManageFed : 45|3@0+ (1,0) [0|7] ""  IHU
 SG_ HCU_RangeAval : 9|10@0+ (1,0) [0|1022] "km"  IHU
 SG_ HCU_EnergyFlow : 14|5@0+ (1,0) [0|31] ""  IHU

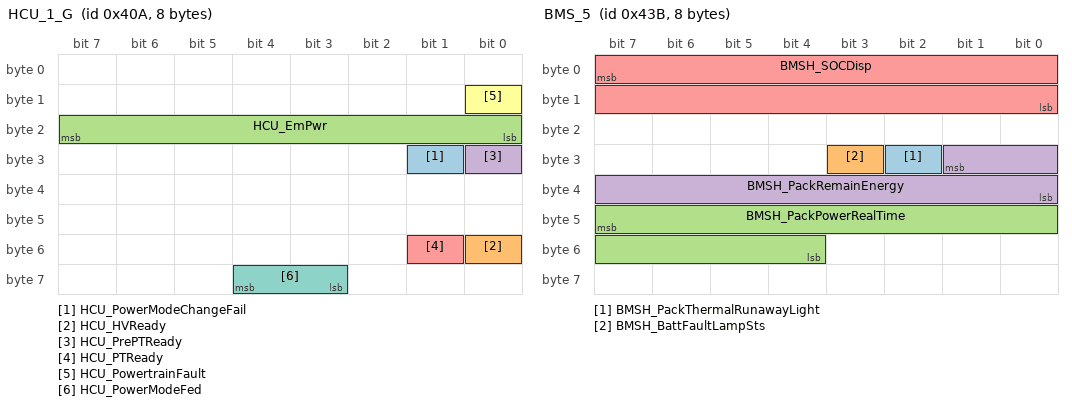
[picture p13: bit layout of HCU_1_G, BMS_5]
BO_ 1034 HCU_1_G: 8 CGW
 SG_ HCU_PowerModeChangeFail : 25|1@0+ (1,0) [0|1] ""  IHU
 SG_ HCU_HVReady : 48|1@0+ (1,0) [0|1] ""  IHU
 SG_ HCU_EmPwr : 23|8@0+ (1,-128) [-100|100] "%"  IHU
 SG_ HCU_PrePTReady : 24|1@0+ (1,0) [0|1] ""  IHU
 SG_ HCU_PTReady : 49|1@0+ (1,0) [0|1] ""  IHU
 SG_ HCU_PowertrainFault : 8|1@0+ (1,0) [0|1] ""  IHU
 SG_ HCU_PowerModeFed : 60|2@0+ (1,0) [0|3] ""  IHU

BO_ 1183 CGW_BMS_24: 8 CGW
 SG_ BMSH_InsulationSts : 55|2@0+ (1,0) [0|3] ""  IHU
 SG_ BMSH_PackChargingThermalSt : 60|3@0+ (1,0) [0|7] ""  IHU
 SG_ BMSH_BattVolt : 39|16@0+ (0.05,0) [0|1000] "V"  IHU
 SG_ BMSH_BatteryCurrent : 23|16@0+ (0.05,-1600) [-600|600] "A"  IHU

BO_ 1472 BMS_20: 8 CGW
 SG_ BMSH_SingleDisChargeEnergy : 23|16@0+ (0.01,0) [0|655] "Kwh"  IHU
 SG_ BMSH_SingleChargeEnergy : 7|16@0+ (0.01,0) [0|655] "Kwh"  IHU

BO_ 1449 BMS_11: 8 CGW
 SG_ BMSH_CellVoltMin_Num : 31|8@0+ (1,0) [0|255] ""  IHU
 SG_ BMSH_CellVoltMax_Num : 23|8@0+ (1,0) [0|255] ""  IHU
 SG_ BMSH_CellVoltMin : 55|16@0+ (1,0) [0|5000] "mV"  IHU
 SG_ BMSH_CellVoltMax : 39|16@0+ (1,0) [0|5000] "mV"  IHU

BO_ 1448 BMS_10: 8 CGW
 SG_ BMSH_TempSensor_TempMinNum : 39|8@0+ (1,0) [0|255] ""  IHU
 SG_ BMSH_TempSensor_TempMaxNum : 23|8@0+ (1,0) [0|255] ""  IHU
 SG_ BMSH_TempSensor_MinTemp : 47|8@0+ (1,-40) [-40|123] "oC"  IHU
 SG_ BMSH_TempSensor_MaxTemp : 31|8@0+ (1,-40) [-40|123] "oC"  IHU

BO_ 1436 BMS_9: 8 CGW
 SG_ BMSH_InsulationResis : 55|16@0+ (10,0) [0|65530] "10k"  IHU

BO_ 1103 BMS_8: 8 CGW
 SG_ BMS_8_CC2Sts : 33|1@0+ (1,0) [0|1] ""  IHU
 SG_ BMSH_SOH : 47|8@0+ (1,0) [0|100] "%"  IHU
 SG_ BMS_8_PackDCChargingSt : 37|4@0+ (1,0) [0|15] "Bit"  IHU
 SG_ BMSH_LeftChargeTime : 31|10@0+ (1,0) [0|1022] "Minute"  IHU

BO_ 1083 BMS_5: 8 CGW
 SG_ BMSH_PackThermalRunawayLight : 26|1@0+ (1,0) [0|1] ""  IHU
 SG_ BMSH_BattFaultLampSts : 27|1@0+ (1,0) [0|1] ""  IHU
 SG_ BMSH_PackPowerRealTime : 47|12@0+ (1,-2000) [-400|400] "Kw"  IHU
 SG_ BMSH_PackRemainEnergy : 25|10@0+ (0.1,0) [0|100] "KwH"  IHU
 SG_ BMSH_SOCDisp : 7|16@0+ (0.01,0) [0|100] "%"  IHU

BO_ 2047 TEST_MSG_FOR_FACTORY: 8 CGW
 SG_ Start_Aging : 7|8@0+ (1,0) [0|1] ""  IHU

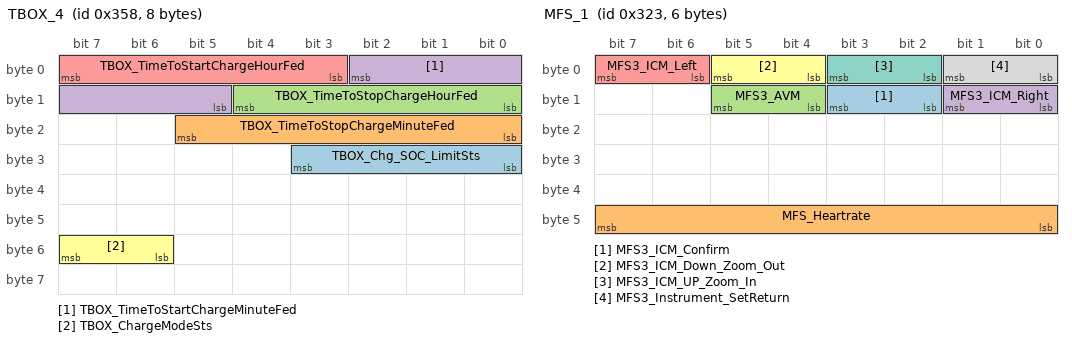
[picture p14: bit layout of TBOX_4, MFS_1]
BO_ 856 TBOX_4: 8 CGW
 SG_ TBOX_Chg_SOC_LimitSts : 27|4@0+ (1,0) [0|15] ""  IHU
 SG_ TBOX_TimeToStopChargeMinuteFed : 21|6@0+ (1,0) [0|59] "Minute"  IHU
 SG_ TBOX_TimeToStopChargeHourFed : 12|5@0+ (1,0) [0|23] "h"  IHU
 SG_ TBOX_TimeToStartChargeMinuteFed : 2|6@0+ (1,0) [0|59] "minute"  IHU
 SG_ TBOX_TimeToStartChargeHourFed : 7|5@0+ (1,0) [0|23] "h"  IHU
 SG_ TBOX_ChargeModeSts : 55|2@0+ (1,0) [0|3] ""  IHU

BO_ 1025 CGW_WSD_1: 4 CGW
 SG_ Welcome_OutsoundSts : 3|2@0+ (1,0) [0|3] "Bit"  IHU
 SG_ Person_RemindSts : 1|1@0+ (1,0) [0|1] ""  IHU
 SG_ Welcome_Outsound_SwitchSts : 0|1@0+ (1,0) [0|1] "Bit"  IHU

BO_ 803 MFS_1: 6 MFS
 SG_ MFS3_ICM_Confirm : 11|2@0+ (1,0) [0|3] "bit"  IHU
 SG_ MFS_Heartrate : 47|8@0+ (1,0) [0|255] ""  IHU
 SG_ MFS3_AVM : 13|2@0+ (1,0) [0|3] "bit"  IHU
 SG_ MFS3_ICM_Right : 9|2@0+ (1,0) [0|3] "bit"  IHU
 SG_ MFS3_ICM_Left : 7|2@0+ (1,0) [0|3] "bit"  IHU
 SG_ MFS3_ICM_Down_Zoom_Out : 5|2@0+ (1,0) [0|3] "bit"  IHU
 SG_ MFS3_ICM_UP_Zoom_In : 3|2@0+ (1,0) [0|3] "bit"  IHU
 SG_ MFS3_Instrument_SetReturn : 1|2@0+ (1,0) [0|3] "bit"  IHU

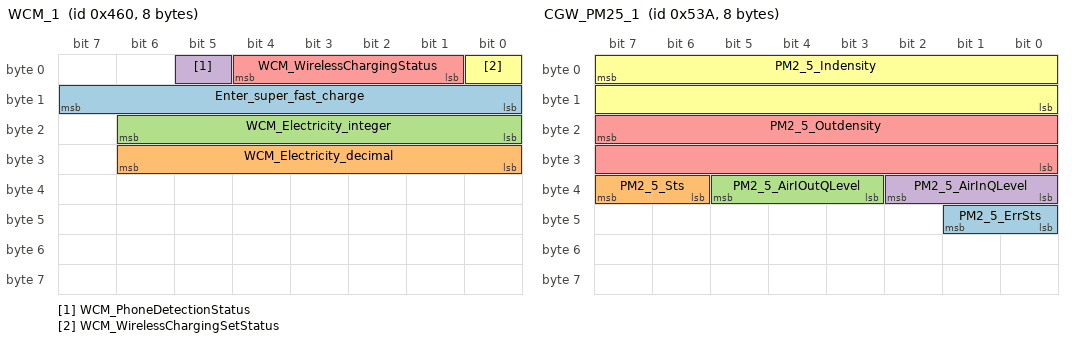
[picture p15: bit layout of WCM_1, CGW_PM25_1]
BO_ 1120 WCM_1: 8 WCM
 SG_ Enter_super_fast_charge : 15|8@0+ (1,0) [0|255] "Bit"  IHU
 SG_ WCM_Electricity_decimal : 30|7@0+ (1,0) [0|100] "%"  IHU
 SG_ WCM_Electricity_integer : 22|7@0+ (1,0) [0|100] "%"  IHU
 SG_ WCM_PhoneDetectionStatus : 5|1@0+ (1,0) [0|1] "Bit"  IHU
 SG_ WCM_WirelessChargingStatus : 4|4@0+ (1,0) [0|15] "Bit"  IHU
 SG_ WCM_WirelessChargingSetStatus : 0|1@0+ (1,0) [0|1] "Bit"  IHU

BO_ 1338 CGW_PM25_1: 8 CGW
 SG_ PM2_5_ErrSts : 41|2@0+ (1,0) [0|3] "Bit"  IHU
 SG_ PM2_5_Sts : 39|2@0+ (1,0) [0|3] "Bit"  IHU
 SG_ PM2_5_AirIOutQLevel : 37|3@0+ (1,0) [0|7] "Bit"  IHU
 SG_ PM2_5_AirInQLevel : 34|3@0+ (1,0) [0|7] "Bit"  IHU
 SG_ PM2_5_Outdensity : 23|16@0+ (1,0) [0|999] "Ug/m^3"  IHU
 SG_ PM2_5_Indensity : 7|16@0+ (1,0) [0|999] "Ug/m^3"  IHU

BO_ 787 CGW_ABS_ESP_3: 8 CGW
 SG_ IPB_RHFWheelSpeedRPM : 23|16@0+ (0.0625,0) [0|4095.9375] "Rpm"  IHU
 SG_ IPB_LHFWheelSpeedRPM : 7|16@0+ (0.0625,0) [0|4095.9375] "Rpm"  IHU
 SG_ ABS_ESP_3_AVHSts : 53|2@0+ (1,0) [0|3] "Bit"  IHU

BO_ 1136 CGW_YAS_2: 8 CGW
 SG_ YAS_2_LongitudinalAcceleration : 23|16@0+ (0.001,-2) [-2|2] "G"  IHU

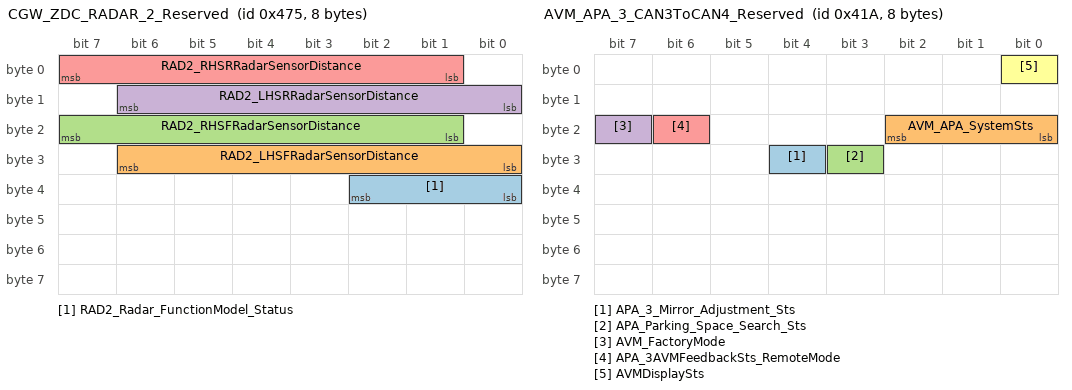
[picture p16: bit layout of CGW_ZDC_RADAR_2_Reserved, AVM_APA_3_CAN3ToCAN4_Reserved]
BO_ 1141 CGW_ZDC_RADAR_2_Reserved: 8 CGW
 SG_ RAD2_Radar_FunctionModel_Status : 34|3@0+ (1,0) [0|7] "bit"  IHU
 SG_ RAD2_LHSFRadarSensorDistance : 30|7@0+ (5,30) [30|180] "Cm"  IHU
 SG_ RAD2_RHSFRadarSensorDistance : 23|7@0+ (5,30) [30|180] "Cm"  IHU
 SG_ RAD2_LHSRRadarSensorDistance : 14|7@0+ (5,30) [30|180] "Cm"  IHU
 SG_ RAD2_RHSRRadarSensorDistance : 7|7@0+ (5,30) [30|180] "Cm"  IHU

BO_ 1050 AVM_APA_3_CAN3ToCAN4_Reserved: 8 CGW
 SG_ APA_3_Mirror_Adjustment_Sts : 28|1@0+ (1,0) [0|1] ""  IHU
 SG_ AVM_APA_SystemSts : 18|3@0+ (1,0) [0|7] "Bit"  IHU
 SG_ APA_Parking_Space_Search_Sts : 27|1@0+ (1,0) [0|1] "Bit"  IHU
 SG_ AVM_FactoryMode : 23|1@0+ (1,0) [0|1] "Bit"  IHU
 SG_ APA_3AVMFeedbackSts_RemoteMode : 22|1@0+ (1,0) [0|1] "Bit"  IHU
 SG_ AVMDisplaySts : 0|1@0+ (1,0) [0|1] "Bit"  IHU

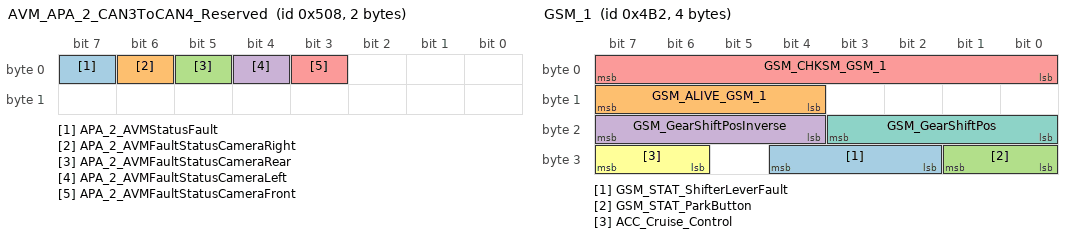
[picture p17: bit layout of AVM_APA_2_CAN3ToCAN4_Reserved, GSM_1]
BO_ 1288 AVM_APA_2_CAN3ToCAN4_Reserved: 2 CGW
 SG_ APA_2_AVMStatusFault : 7|1@0+ (1,0) [0|1] "Bit"  IHU
 SG_ APA_2_AVMFaultStatusCameraRight : 6|1@0+ (1,0) [0|1] "Bit"  IHU
 SG_ APA_2_AVMFaultStatusCameraRear : 5|1@0+ (1,0) [0|1] "Bit"  IHU
 SG_ APA_2_AVMFaultStatusCameraLeft : 4|1@0+ (1,0) [0|1] "Bit"  IHU
 SG_ APA_2_AVMFaultStatusCameraFront : 3|1@0+ (1,0) [0|1] "Bit"  IHU

BO_ 773 CGW_FRM_3: 8 CGW
 SG_ FRM_3_CRC : 63|8@0+ (1,0) [0|255] "Bit"  IHU
 SG_ FRM_3_MessageCounter : 51|4@0+ (1,0) [0|15] "Bit"  IHU
 SG_ FRM_3_DistanceWarning_On_Off_Sts : 52|1@0+ (1,0) [0|1] "Bit"  IHU
 SG_ FRM_3_AEB_ON_OFF_Sts : 53|1@0+ (1,0) [0|1] "Bit"  IHU
 SG_ FRM_3_FCW_OPTION_Sts : 55|2@0+ (1,0) [0|3] "Bit"  IHU
 SG_ FRM_3_FCW_ON_OFF_Sts : 40|1@0+ (1,0) [0|1] "Bit"  IHU
 SG_ FRM_3_TimeGapLastSet_DVD : 41|1@0+ (1,0) [0|1] "Bit"  IHU
 SG_ FRM_3_FCW_PreWarning : 42|1@0+ (1,0) [0|1] "Bit"  IHU
 SG_ FRM_3_DistanceWarning : 43|1@0+ (1,0) [0|1] "Bit"  IHU
 SG_ FRM_3_AEBMode : 46|3@0+ (1,0) [0|7] "Bit"  IHU
 SG_ FRM_3_FCWMode : 33|3@0+ (1,0) [0|7] "Bit"  IHU
 SG_ FRM_3_Obiect_Dx : 29|8@0+ (0.5,0) [0|127] "M"  IHU
 SG_ FRM_3_ACCMode : 37|4@0+ (1,0) [0|15] "Bit"  IHU
 SG_ FRM_3_TimeGapSet_ICM : 17|2@0+ (1,0) [0|3] "Bit"  IHU
 SG_ FRM_3_TimeGapSet_DVD : 31|2@0+ (1,0) [0|3] "Bit"  IHU
 SG_ FRM_3_TakeOverReq : 18|1@0+ (1,0) [0|1] "Bit"  IHU
 SG_ FRM_3_Textinfo : 23|5@0+ (1,0) [0|31] "Bit"  IHU
 SG_ FRM_3_FrontObject_Type : 11|3@0+ (1,0) [0|7] "Bit"  IHU
 SG_ FRM_3_ObjValid : 8|1@0+ (1,0) [0|1] "Bit"  IHU
 SG_ FRM_3_DxTarObj : 14|3@0+ (1,0) [0|7] "Bit"  IHU
 SG_ FRM_3_VSetDis : 7|9@0+ (0.5,0) [0|255.5] "KPH"  IHU

BO_ 1241 CGW_EMS_4_G: 8 CGW
 SG_ FuelTankLidSystemFailureSts : 18|1@0+ (1,0) [0|1] ""  IHU
 SG_ FuelTankPressureConditionReached : 20|2@0+ (1,0) [0|3] ""  IHU

BO_ 632 CGW_EMS_4: 8 CGW
 SG_ EMS_4_IntakeAirPressure : 63|8@0+ (1,0) [0|254] "Kpa"  IHU
 SG_ EMS_4_EngineSts : 14|1@0+ (1,0) [0|1] "Bit"  IHU

BO_ 1202 GSM_1: 4 CGW
 SG_ GSM_STAT_ShifterLeverFault : 28|3@0+ (1,0) [0|7] ""  IHU
 SG_ GSM_ALIVE_GSM_1 : 15|4@0+ (1,0) [0|15] ""  IHU
 SG_ GSM_STAT_ParkButton : 25|2@0+ (1,0) [0|3] ""  IHU
 SG_ GSM_GearShiftPosInverse : 23|4@0+ (1,0) [0|15] ""  IHU
 SG_ GSM_CHKSM_GSM_1 : 7|8@0+ (1,0) [0|255] ""  IHU
 SG_ ACC_Cruise_Control : 31|2@0+ (1,0) [0|3] "Bit"  IHU
 SG_ GSM_GearShiftPos : 19|4@0+ (1,0) [0|15] "Bit"  IHU

BO_ 1507 CGW_DHM_1: 8 CGW
 SG_ DHM_1_Doorkonb_time_freeback : 35|2@0+ (1,0) [0|3] "bit"  IHU

BO_ 1518 CGW_CEM_DHM_Control: 8 CGW
 SG_ CEM_DHM_handlelockswitchfeedback : 4|1@0+ (1,0) [0|1] "bit"  IHU
 SG_ CEM_DHM_handleunlockswitchfeedba : 3|1@0+ (1,0) [0|1] "bit"  IHU

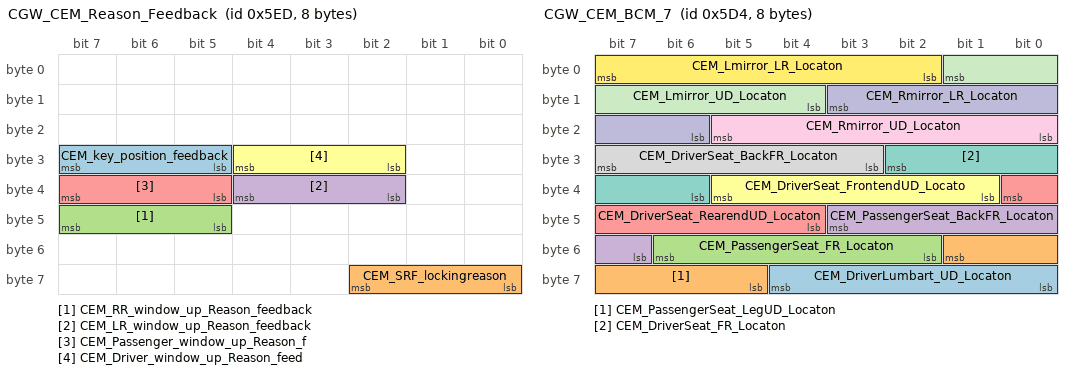
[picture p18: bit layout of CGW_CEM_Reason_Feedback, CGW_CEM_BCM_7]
BO_ 1517 CGW_CEM_Reason_Feedback: 8 CGW
 SG_ CEM_key_position_feedback : 31|3@0+ (1,0) [0|7] ""  IHU
 SG_ CEM_SRF_lockingreason : 58|3@0+ (1,0) [0|7] "Bit"  IHU
 SG_ CEM_RR_window_up_Reason_feedback : 47|3@0+ (1,0) [0|7] "Bit"  IHU
 SG_ CEM_LR_window_up_Reason_feedback : 36|3@0+ (1,0) [0|7] "Bit"  IHU
 SG_ CEM_Passenger_window_up_Reason_f : 39|3@0+ (1,0) [0|7] "Bit"  IHU
 SG_ CEM_Driver_window_up_Reason_feed : 28|3@0+ (1,0) [0|7] "Bit"  IHU

BO_ 1504 CGW_CEM_SRF: 8 CGW
 SG_ CEM_SRFclosingConditions : 15|4@0+ (1,0) [0|15] ""  IHU
 SG_ CEM_Abat_VentCMDSts : 7|4@0+ (1,0) [0|15] "Bit"  IHU
 SG_ CEM_PSRFCMDSts : 3|4@0+ (1,0) [0|15] "Bit"  IHU

BO_ 1168 CGW_CEM_ALM_1: 8 CGW
 SG_ ALM_1_SET_LampLEDSwitch : 26|1@0+ (1,0) [0|1] "Bit"  IHU
 SG_ ALM_1_NavigationSwitch : 25|1@0+ (1,0) [0|1] "Bit"  IHU
 SG_ CEM_ALM_1_SceneMode_ControlSwitc : 29|2@0+ (1,0) [0|3] "Bit"  IHU
 SG_ CEM_ALM_1_DeletePeronalSet_FB : 63|4@0+ (1,0) [0|15] "Bit"  IHU
 SG_ CEM_ALM_1_PersonalBeamEn : 59|2@0+ (1,0) [0|3] "Bit"  IHU
 SG_ CEM_ALM_1_PersonalSeatEn : 57|2@0+ (1,0) [0|3] "Bit"  IHU
 SG_ CEM_ALM_1_Seat_Set_Status : 55|4@0+ (1,0) [0|15] "Bit"  IHU
 SG_ CEM_ALM_1_Seat_Set_Pop_Up : 51|2@0+ (1,0) [0|3] "Bit"  IHU
 SG_ CEM_ALM_1_Wash_Car_Status : 49|2@0+ (1,0) [0|3] "Bit"  IHU
 SG_ CEM_ALM_1_PersonalSetSts : 38|1@0+ (1,0) [0|1] "Bit"  IHU
 SG_ CEM_ALM_1_STAT_WelcomeWaterLamp : 37|2@0+ (1,0) [0|3] "Bit"  IHU
 SG_ CEM_ALM_1_STAT_AssociatedWithDri : 35|2@0+ (1,0) [0|3] "Bit"  IHU
 SG_ CEM_ALM_1_STAT_Music : 33|2@0+ (1,0) [0|3] "Bit"  IHU
 SG_ CEM_ALM_1_STAT_Apiluminance : 19|4@0+ (1,0) [0|15] "Bit"  IHU
 SG_ CEM_ALM_1_STAT_Static_Colour : 23|4@0+ (1,0) [0|15] "Bit"  IHU
 SG_ CEM_ALM_1_STAT_StaticEffect : 12|3@0+ (1,0) [0|7] "Bit"  IHU
 SG_ CEM_ALM_1_STAT_ControlSwitch : 9|2@0+ (1,0) [0|3] "Bit"  IHU
 SG_ CEM_ALM_1_STAT_DMSMonitoring : 31|2@0+ (1,0) [0|3] "Bit"  IHU
 SG_ CEM_ALM_1_STAT_PM2_5Monitoring : 14|2@0+ (1,0) [0|3] "Bit"  IHU
 SG_ CEM_ALM_1_STAT_DriveApiluminance : 0|2@0+ (1,0) [0|3] "Bit"  IHU
 SG_ CEM_ALM_1_STAT_64Colour : 7|7@0+ (1,0) [0|64] "Bit"  IHU

BO_ 1492 CGW_CEM_BCM_7: 8 CGW
 SG_ CEM_DriverLumbart_UD_Locaton : 60|5@0+ (5,0) [0|100] "%"  IHU
 SG_ CEM_PassengerSeat_LegUD_Locaton : 49|5@0+ (5,0) [0|100] "%"  IHU
 SG_ CEM_PassengerSeat_FR_Locaton : 54|5@0+ (5,0) [0|100] "%"  IHU
 SG_ CEM_PassengerSeat_BackFR_Locaton : 43|5@0+ (5,0) [0|100] "%"  IHU
 SG_ CEM_DriverSeat_RearendUD_Locaton : 32|5@0+ (5,0) [0|100] "%"  IHU
 SG_ CEM_DriverSeat_FrontendUD_Locato : 37|5@0+ (5,0) [0|100] "%"  IHU
 SG_ CEM_DriverSeat_FR_Locaton : 26|5@0+ (5,0) [0|100] "%"  IHU
 SG_ CEM_DriverSeat_BackFR_Locaton : 31|5@0+ (5,0) [0|100] "%"  IHU
 SG_ CEM_Rmirror_UD_Locaton : 21|6@0+ (2,-2) [0|100] "%"  IHU
 SG_ CEM_Rmirror_LR_Locaton : 11|6@0+ (2,-2) [0|100] "%"  IHU
 SG_ CEM_Lmirror_UD_Locaton : 1|6@0+ (2,-2) [0|100] "%"  IHU
 SG_ CEM_Lmirror_LR_Locaton : 7|6@0+ (2,-2) [0|100] "%"  IHU

BO_ 1476 CGW_CEM_BCM_6: 8 CGW
 SG_ BCM_AutoWipingInhibit : 7|2@0+ (1,0) [0|3] ""  IHU
 SG_ CEM_Psngrseat_Location : 55|4@0+ (1,0) [0|15] "bit"  IHU
 SG_ CEM_PassengerSeat_LegUDSts : 31|2@0+ (1,0) [0|3] "bit"  IHU
 SG_ CEM_PassengerSeat_BackFRSts : 39|2@0+ (1,0) [0|3] "bit"  IHU
 SG_ CEM_PassengerSeat_FRSts : 29|2@0+ (1,0) [0|3] "bit"  IHU
 SG_ CEM_massagemodeSts : 60|3@0+ (1,0) [0|4] "Bit"  IHU
 SG_ CEM_passageVibrationSts : 57|2@0+ (1,0) [0|3] "Bit"  IHU
 SG_ CEM_Passenger_massageSts : 51|1@0+ (1,0) [0|1] "Bit"  IHU
 SG_ CEM_DriverLumbart_FR_Locaton : 50|5@0+ (5,0) [0|100] "%"  IHU
 SG_ CEM_Mirror_Driverseat_Location : 47|5@0+ (1,0) [0|21] "Bit"  IHU
 SG_ CEM_UnderVoltageSts : 61|1@0+ (1,0) [0|1] "bit"  IHU
 SG_ CEM_RearWiper_SwitchSts : 42|1@0+ (1,0) [0|1] "bit"  IHU
 SG_ BCM_Wiper_MaintenanceSts : 41|1@0+ (1,0) [0|1] "bit"  IHU
 SG_ CEM_Mirror_Fold_SwitchSts : 40|1@0+ (1,0) [0|1] "bit"  IHU
 SG_ CEM_IPM__FRSeatHeatVentSwSts : 37|3@0+ (1,0) [0|7] "bit"  IHU
 SG_ CEM_IPM_FLSeatHeatVentSwSts : 34|3@0+ (1,0) [0|7] "bit"  IHU
 SG_ CEM_DriverLumbart_UDSts : 27|2@0+ (1,0) [0|3] "bit"  IHU
 SG_ CEM_DriverLumbart_FRSts : 25|2@0+ (1,0) [0|3] "bit"  IHU
 SG_ CEM_DriverSeat_RearendUDSts : 23|2@0+ (1,0) [0|3] "bit"  IHU
 SG_ CEM_DriverSeat_FrontendUDSts : 21|2@0+ (1,0) [0|3] "bit"  IHU
 SG_ CEM_DriverSeat_FRSts : 19|2@0+ (1,0) [0|3] "bit"  IHU
 SG_ CEM_DriverSeat_BackFRSts : 17|2@0+ (1,0) [0|3] "bit"  IHU
 SG_ CEM_MirrorFlip_CFGSts : 15|2@0+ (1,0) [0|3] "bit"  IHU
 SG_ CEM_RightMirrorCtrlSts : 13|3@0+ (1,0) [0|7] "bit"  IHU
 SG_ CEM_LeftMirrorCtrlSts : 10|3@0+ (1,0) [0|7] "bit"  IHU
 SG_ CEM_RHRdoor_buttonsts : 5|1@0+ (1,0) [0|1] "bit"  IHU
 SG_ CEM_LHRdoor_buttonsts : 4|1@0+ (1,0) [0|1] "bit"  IHU
 SG_ CEM_PsngrDoor_buttonsts : 3|1@0+ (1,0) [0|1] "bit"  IHU
 SG_ CEM_Smart_HighBeamSts : 2|1@0+ (1,0) [0|1] "bit"  IHU
 SG_ CEM_HighBeam_AdjustSts : 1|2@0+ (1,0) [0|3] "bit"  IHU

BO_ 1535 CGW_CEM_BCM_3: 8 CGW
 SG_ BCM_3_EngineForbidStatus : 8|1@0+ (1,0) [0|1] ""  IHU
 SG_ BCM_3_TelematicsPowerMode : 7|2@0+ (1,0) [0|3] ""  IHU
 SG_ BCM_3_BM_AuthenticationStatus : 3|2@0+ (1,0) [0|3] ""  IHU
 SG_ IBCM_2_AuthenticationStatus : 1|2@0+ (1,0) [0|3] ""  IHU
 SG_ BCM_2_Windows_Inhibit_SW : 32|1@0+ (1,0) [0|1] ""  IHU
 SG_ BCM_2_GalleryModeSts : 26|2@0+ (1,0) [0|3] ""  IHU
 SG_ BCM_2_CurrentTelematicsMode : 5|2@0+ (1,0) [0|3] ""  IHU
 SG_ CEM_3_passenger_Welcome_Seat_Sts : 57|2@0+ (1,0) [0|3] "Bit"  IHU
 SG_ CEM_DHM_Doorkonbmode_feedback : 53|2@0+ (1,0) [0|2] "Bit"  IHU
 SG_ CEM_DHM_Driver_unlockmode_feedba : 51|2@0+ (1,0) [0|2] "bit"  IHU
 SG_ CEM_UVC_LuminanceBf : 47|3@0+ (1,0) [0|7] "Bit"  IHU
 SG_ CEM_UVC_WorkingBf : 36|2@0+ (1,0) [0|3] "Bit"  IHU
 SG_ CEM_3_Welcome_Seat_Sts : 34|2@0+ (1,0) [0|3] "Bit"  IHU
 SG_ CEM_IPM_3_ACMAXReq_Sts : 38|2@0+ (1,0) [0|3] "Bit"  IHU
 SG_ CEM_3_PM25DisplayToggle_Sts : 49|2@0+ (1,0) [0|3] "Bit"  IHU
 SG_ CEM_3_DWM_Sts_Msg : 17|2@0+ (1,0) [0|3] "Bit"  IHU
 SG_ CEM_3_EngineControlSts : 9|1@0+ (1,0) [0|1] "Bit"  IHU

BO_ 914 CGW_CEM_BCM_2: 8 CGW
 SG_ BCM_All_weather_light_sts : 61|1@0+ (1,0) [0|1] ""  IHU
 SG_ UnlockingBreathStatus : 52|2@0+ (1,0) [0|3] ""  IHU
 SG_ AidTurningIlluminationSts : 49|1@0+ (1,0) [0|1] ""  IHU
 SG_ BCM_4_AlarmMode : 59|4@0+ (1,0) [0|15] "Bit"  IHU
 SG_ CEM_2_RemoteTrunkOnlySts : 62|1@0+ (1,0) [0|1] "Bit"  IHU
 SG_ BCM_4_AutoLockSts : 63|1@0+ (1,0) [0|1] "Bit"  IHU
 SG_ CEM_2RearDefrosts : 60|1@0+ (1,0) [0|1] "Bit"  IHU
 SG_ CEM_2_HazardLampForUrgencyBrakeS : 48|1@0+ (1,0) [0|1] "Bit"  IHU
 SG_ CEM_2_Mirror_FlipSts : 50|1@0+ (1,0) [0|1] "Bit"  IHU
 SG_ BCM_4_RemoteLockFeedbackSts : 54|2@0+ (1,0) [0|3] "Bit"  IHU
 SG_ BCM_4_AutoUnlockSts : 55|1@0+ (1,0) [0|1] "Bit"  IHU
 SG_ CEM_2_WiperSts : 47|2@0+ (1,0) [0|3] "Bit"  IHU
 SG_ CEM_2_RainDetected : 45|1@0+ (1,0) [0|1] "Bit"  IHU
 SG_ CEM_2_WiperSensitivitySWSts : 44|3@0+ (1,0) [0|7] "Bit"  IHU
 SG_ CEM_2_RainSensorFailSts : 41|1@0+ (1,0) [0|1] "Bit"  IHU
 SG_ BCM_4_RARDfstCmd : 40|1@0+ (1,0) [0|1] "Bit"  IHU
 SG_ CEM_2_WiperSelectionSts : 39|2@0+ (1,0) [0|3] "Bit"  IHU
 SG_ BCM_4_FrontFogLightSts : 37|1@0+ (1,0) [0|1] "Bit"  IHU
 SG_ CEM_2_Laser_High_Beam_Assist_Sta : 36|1@0+ (1,0) [0|1] "Bit"  IHU
 SG_ CEM_2_ReverseGearSwitch : 35|1@0+ (1,0) [0|1] "Bit"  IHU
 SG_ BCM_4_RearFogLightSts : 34|1@0+ (1,0) [0|1] "Bit"  IHU
 SG_ CEM_2_External_WelcomelightSts : 33|2@0+ (1,0) [0|3] "Bit"  IHU
 SG_ BCM_4_Mirror_Fold_Sts : 31|1@0+ (1,0) [0|1] "Bit"  IHU
 SG_ BCM_4_TrunkSts : 30|1@0+ (1,0) [0|1] "Bit"  IHU
 SG_ BCM_4_LHRdoorSts : 29|1@0+ (1,0) [0|1] "Bit"  IHU
 SG_ BCM_4_RHRDoorSts : 28|1@0+ (1,0) [0|1] "Bit"  IHU
 SG_ CEM_2_SunRoofSts : 27|1@0+ (1,0) [0|1] "Bit"  IHU
 SG_ BCM_4_BonnetSts : 26|1@0+ (1,0) [0|1] "Bit"  IHU
 SG_ BCM_4_PsngrDoorSts : 25|1@0+ (1,0) [0|1] "Bit"  IHU
 SG_ BCM_4_DriverDoorSts : 24|1@0+ (1,0) [0|1] "Bit"  IHU
 SG_ BCM_4_FollowMeTimeSts : 23|4@0+ (1,0) [0|15] "Bit"  IHU
 SG_ BCM_4_BlankingnumberSts : 19|2@0+ (1,0) [0|3] "Bit"  IHU
 SG_ CEM_2_DirectionIndLeft : 17|1@0+ (1,0) [0|1] "Bit"  IHU
 SG_ CEM_2_DirectionIndRight : 16|1@0+ (1,0) [0|1] "Bit"  IHU
 SG_ BCM_4_DRLSts : 15|1@0+ (1,0) [0|1] "Bit"  IHU
 SG_ BCM_4_LowBeamSts : 14|1@0+ (1,0) [0|1] "Bit"  IHU
 SG_ CEM_2_Laser_LightSts : 13|1@0+ (1,0) [0|1] "Bit"  IHU
 SG_ BCM_4_HighBeamSts : 12|1@0+ (1,0) [0|1] "Bit"  IHU
 SG_ BCM_4_ParkTailLightSts : 11|1@0+ (1,0) [0|1] "Bit"  IHU
 SG_ BCM_4_BrakePedalSts : 10|1@0+ (1,0) [0|1] "Bit"  IHU
 SG_ BCM_4_LHTurnlightSts : 9|1@0+ (1,0) [0|1] "Bit"  IHU
 SG_ BCM_4_RHTurnlightSts : 8|1@0+ (1,0) [0|1] "Bit"  IHU
 SG_ CEM_2_BlankchanginglaneSts : 7|1@0+ (1,0) [0|1] "Bit"  IHU
 SG_ BCM_4_KeySts : 6|2@0+ (1,0) [0|3] "Bit"  IHU
 SG_ CEM_2_FollowMeHomeSts : 4|1@0+ (1,0) [0|1] "Bit"  IHU
 SG_ CEM_2_KeyRemindWarning : 3|1@0+ (1,0) [0|1] "Bit"  IHU
 SG_ BCM_4_ParkLightOnWarning : 2|1@0+ (1,0) [0|1] "Bit"  IHU
 SG_ BCM_4_FollowMeHomeTimeSts : 1|2@0+ (1,0) [0|3] "Bit"  IHU

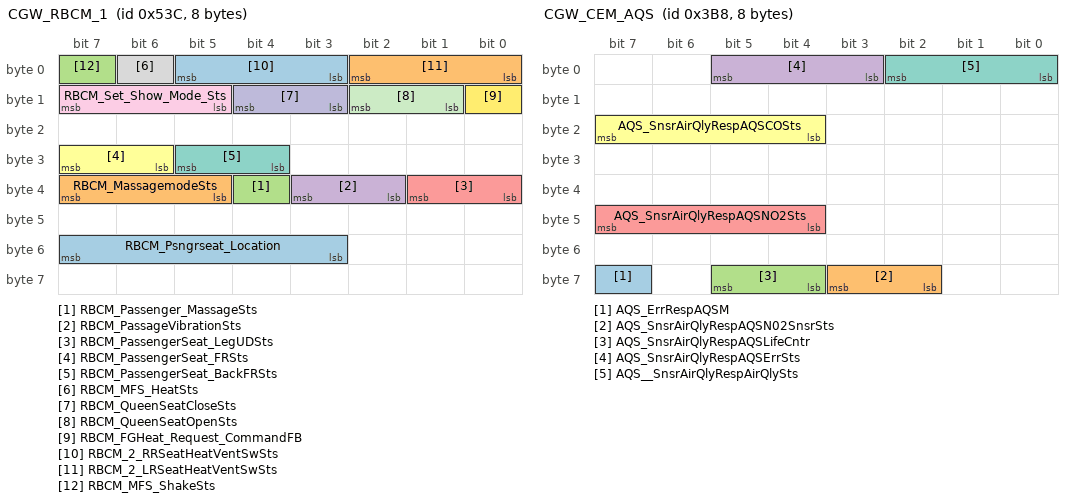
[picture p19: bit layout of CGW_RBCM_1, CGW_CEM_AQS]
BO_ 1340 CGW_RBCM_1: 8 CGW
 SG_ RBCM_Psngrseat_Location : 55|5@0+ (1,0) [0|21] ""  IHU
 SG_ RBCM_MassagemodeSts : 39|3@0+ (1,0) [0|7] ""  IHU
 SG_ RBCM_Passenger_MassageSts : 36|1@0+ (1,0) [0|1] ""  IHU
 SG_ RBCM_PassageVibrationSts : 35|2@0+ (1,0) [0|3] ""  IHU
 SG_ RBCM_PassengerSeat_LegUDSts : 33|2@0+ (1,0) [0|3] ""  IHU
 SG_ RBCM_PassengerSeat_FRSts : 31|2@0+ (1,0) [0|3] ""  IHU
 SG_ RBCM_PassengerSeat_BackFRSts : 29|2@0+ (1,0) [0|3] ""  IHU
 SG_ RBCM_MFS_HeatSts : 6|1@0+ (1,0) [0|1] ""  IHU
 SG_ RBCM_Set_Show_Mode_Sts : 15|3@0+ (1,0) [0|7] ""  IHU
 SG_ RBCM_QueenSeatCloseSts : 12|2@0+ (1,0) [0|3] ""  IHU
 SG_ RBCM_QueenSeatOpenSts : 10|2@0+ (1,0) [0|3] ""  IHU
 SG_ RBCM_FGHeat_Request_CommandFB : 8|1@0+ (1,0) [0|1] "Bit"  IHU
 SG_ RBCM_2_RRSeatHeatVentSwSts : 5|3@0+ (1,0) [0|7] "Bit"  IHU
 SG_ RBCM_2_LRSeatHeatVentSwSts : 2|3@0+ (1,0) [0|7] "Bit"  IHU
 SG_ RBCM_MFS_ShakeSts : 7|1@0+ (1,0) [0|1] "Bit"  IHU

BO_ 1306 CGW_CEM_IPM: 8 CGW
 SG_ CLM_2_Blower_DelaySts : 49|1@0+ (1,0) [0|1] ""  IHU
 SG_ CLM_2_BT_Reduce_Wind_SpeedSts : 48|1@0+ (1,0) [0|1] "bit"  IHU
 SG_ TMM_IHU_OffRoadSts : 46|1@0+ (1,0) [0|1] "Bit"  IHU
 SG_ CEM_IPM_AC_DisplaySts : 45|1@0+ (1,0) [0|1] "Bit"  IHU
 SG_ CLM_2_Custom_Air_Conditioning : 54|2@0+ (1,0) [0|2] "Bit"  IHU
 SG_ CLM_2_Automatic_Ventilation : 51|1@0+ (1,0) [0|1] "Bit"  IHU
 SG_ CLM_2_First_BlowingSts : 50|1@0+ (1,0) [0|1] "Bit"  IHU
 SG_ CEM_IPM_FRSeatHeatVentSwSts : 61|3@0+ (1,0) [0|7] "Bit"  IHU
 SG_ CEM_IPM_FLSeatHeatVentSwSts : 58|3@0+ (1,0) [0|7] "Bit"  IHU
 SG_ CEM_IPM_TempknobRollingCounter : 35|5@0+ (1,0) [0|31] "Bit"  IHU
 SG_ CLM_2_AnionPurify : 63|1@0+ (1,0) [0|1] "Bit"  IHU
 SG_ CEM_IPM_PM25_Detect : 55|1@0+ (1,0) [0|1] "Bit"  IHU
 SG_ CLM_2_SyncSts : 44|1@0+ (1,0) [0|1] "Bit"  IHU
 SG_ CLM_2_FrontAutoACSts : 43|1@0+ (1,0) [0|1] "Bit"  IHU
 SG_ CEM_IPM_RearBlowModeSts : 42|2@0+ (1,0) [0|3] "Bit"  IHU
 SG_ CEM_IPM_RearAutoACSts : 40|1@0+ (1,0) [0|1] "Bit"  IHU
 SG_ CEM_IPM_RearBlowSpdCtrlSts : 39|4@0+ (1,0) [0|15] "Bit"  IHU
 SG_ CEM_IPM_RearTempsts : 29|6@0+ (0.5,0) [16|30] "℃"  IHU
 SG_ CLM_2_RearOFFsts : 31|1@0+ (1,0) [0|1] "Bit"  IHU
 SG_ CEM_IPM_RearDefrosts : 30|1@0+ (1,0) [0|1] "Bit"  IHU
 SG_ CLM_2_FrontOFFSts : 17|1@0+ (1,0) [0|1] "Bit"  IHU
 SG_ CLM_2_ACStatus : 21|1@0+ (1,0) [0|1] "Bit"  IHU
 SG_ CLM_2_RecyMode : 23|2@0+ (1,0) [0|3] "Bit"  IHU
 SG_ CLM_2_FrontBlowModeSts : 20|3@0+ (1,0) [0|7] "Bit"  IHU
 SG_ CLM_2_FrontBlowSpdCtrlsts : 11|4@0+ (1,0) [0|15] "Bit"  IHU
 SG_ CLM_2_FRTempsts : 7|6@0+ (0.5,0) [16|30] "℃"  IHU
 SG_ CLM_2_FLTempsts : 1|6@0+ (0.5,0) [16|30] "℃"  IHU

BO_ 952 CGW_CEM_AQS: 8 CGW
 SG_ AQS_ErrRespAQSM : 63|1@0+ (1,0) [0|1] "" Vector__XXX
 SG_ AQS_SnsrAirQlyRespAQSN02SnsrSts : 59|2@0+ (1,0) [0|3] "" Vector__XXX
 SG_ AQS_SnsrAirQlyRespAQSLifeCntr : 61|2@0+ (1,0) [0|3] ""  IHU
 SG_ AQS_SnsrAirQlyRespAQSErrSts : 5|3@0+ (1,0) [0|7] ""  IHU
 SG_ AQS_SnsrAirQlyRespAQSNO2Sts : 47|4@0+ (1,0) [0|15] ""  IHU
 SG_ AQS_SnsrAirQlyRespAQSCOSts : 23|4@0+ (1,0) [0|15] ""  IHU
 SG_ AQS__SnsrAirQlyRespAirQlySts : 2|3@0+ (1,0) [0|7] ""  IHU

BO_ 1381 CEM_RLHS: 8 CGW
 SG_ WSM_Blk : 50|1@0+ (1,0) [0|1] ""  IHU
 SG_ S_RAIN : 5|1@0+ (1,0) [0|1] "Bit"  IHU
 SG_ S_AUTOPANEL : 2|1@0+ (1,0) [0|1] "Bit"  IHU

CM_ BO_ 3221225472 "This is a message for not used signals, created by Vector CANdb++ DBC OLE DB Provider.";
CM_ SG_ 3221225472 SET_Rmirror_UD_Locaton "右后视镜上下调节指定位置
Feedback:0x5D4：CEM_Rmirror_UD_Locaton";
CM_ SG_ 3221225472 SET_Rmirror_LR_Locaton "右后视镜左右调节指定位置
Feedback:0x5D4：CEM_Rmirror_LR_Locaton";
CM_ SG_ 3221225472 SET_Lmirror_UD_Locaton "左后视镜上下调节指定位置
Feedback:0x5D4：CEM_Lmirror_UD_Locaton";
CM_ SG_ 3221225472 SET_Lmirror_LR_Locaton "左后视镜左右调节指定位置
Feedback:0x5D4：CEM_Lmirror_LR_Locaton";
CM_ SG_ 3221225472 RBCM_MFS_HeatSts "方向盘加热";
CM_ SG_ 1440 IHU_EAO_4_Protrait_Val_Pos "%";
CM_ SG_ 1440 IHU_EAO_4_LandScap_Val_Pos "%";
CM_ SG_ 1440 IHU_EAO_3_Protrait_Val_Pos "%";
CM_ SG_ 1440 IHU_EAO_3_LandScap_Val_Pos "%";
CM_ SG_ 1440 IHU_EAO_2_Protrait_Val_Pos "%";
CM_ SG_ 1440 IHU_EAO_2_LandScap_Val_Pos "%";
CM_ SG_ 1440 IHU_EAO_1_Protrait_Val_Pos "%";
CM_ SG_ 1440 IHU_EAO_1_LandScap_Val_Pos "%";
CM_ SG_ 1440 IHU_FreeSwing_State "Bit";
CM_ SG_ 1440 IHU_MirrorSwing_State "Bit";
CM_ SG_ 1440 IHU_AutoSwing_State "Bit";
CM_ SG_ 1262 LightShowSts "灯光秀过程/状态
增加灯光秀状态反馈的逻辑：对于灯光秀反馈的ID：0x4EE是周期信号，在灯光秀没有启动之前一直反馈的是默认值(0x0)。
当灯光秀启动之后就会反馈灯光秀开启状态(0x1)，当灯光秀结束之后就会反馈灯光秀结束的状态，灯光秀结束（包含灯光秀正常结束和打断的结束）之后会持续反馈2s灯光秀结束状态(0x2)，
中途开启了任何灯光秀就会重新反馈开启的状态，在2s之内没有在收到灯光秀开启指令之后进行反馈默认值。";
CM_ BO_ 1322 "JX65国际二阶段用";
CM_ SG_ 1322 IHU_All_weather_light_switch "全天候灯激活开关";
CM_ SG_ 1322 IHU_SET_LampLEDSwitch "氛围灯照明开关";
CM_ SG_ 1322 SET_FrontWindscreenHeatiReq "前风挡电加热请求";
CM_ SG_ 1322 SET_RRSeatHeatVentSwReq "右后座位温度设置";
CM_ SG_ 1322 SET_LRSeatHeatVentSwReq "左后座位温度设置";
CM_ BO_ 295 "横向加速度";
CM_ SG_ 295 YAS_1_LateraAccaleleration "横向加速度";
CM_ SG_ 1111 AVAS_FunctionSts "行人提示设置反馈";
CM_ SG_ 1057 LimitSpeedSts "主动限速功能状态
Off:关闭主动限速功能
Standby:打开主动限速功能但未激活
Overspeed:限速功能激活后当前车速超过限速值
Limit:限速功能激活
Cancel:暂时退出主动限速状态
Kickdown:油门踩到底";
CM_ SG_ 1057 CruiseLimitSpeedValue "巡航设定值/限速值";
CM_ SG_ 1046 HCU_3_G_SumFuCns "SumFuelConsumption
自清零后累计百公里油耗 L/100km";
CM_ SG_ 1046 HCU_HundECHis "历史平均电量消耗";
CM_ SG_ 1046 HCU_HundECAver "当前平均电量消耗";
CM_ SG_ 1142 HCU_4_G_SumEgyCns "Sum Energy Consumption
自清零后累计百公里能耗 L/100km";
CM_ SG_ 1142 HCU_4_G_AvgEnergyCns "Avg Energy Consumption
近50km平均百公里能耗 L/100km";
CM_ SG_ 1142 HCU_4_G_AvgElecCns "Avg Electric Consumption
近50km平均百公里电耗 kW.h/100km";
CM_ SG_ 1142 HCU_4_G_AvgFuCns "Avg Fuel Consumption
近50km平均百公里油耗 L/100km";
CM_ SG_ 1142 FuelTankLidSts "加油小门开关状态";
CM_ SG_ 1044 HCU_RegenerateLevel "能量回收等级反馈";
CM_ SG_ 1044 HCU_SetSOCFed "SOC设置反馈";
CM_ SG_ 1044 HCU_SocManageFed "电量模式反馈";
CM_ SG_ 1044 HCU_RangeAval "纯电续航里程";
CM_ SG_ 1044 HCU_EnergyFlow "能量流";
CM_ SG_ 1034 HCU_PowertrainFault "动力系统故障";
CM_ SG_ 1034 HCU_PowerModeFed "动力模式反馈";
CM_ SG_ 1183 BMSH_PackChargingThermalSt "充电及加热状态
慢充充电状态及加热状态提示，0X5接受不处理，收到0x2,0x均为充电中；0x1为电池加热中；0x4为充电完成;0x6为均温充电中；0x7为电池冷却中";
CM_ SG_ 1183 BMSH_BattVolt "电池包系统电压";
CM_ SG_ 1183 BMSH_BatteryCurrent "高压电池包系统高压电流，针对电池包而言，负值表示给电池包充电:正值表示给电池包放电。";
CM_ SG_ 1472 BMSH_SingleDisChargeEnergy "单次放电能量";
CM_ SG_ 1472 BMSH_SingleChargeEnergy "单次充电能量";
CM_ SG_ 1449 BMSH_CellVoltMin "高压电池系统内最低单体电压";
CM_ SG_ 1449 BMSH_CellVoltMax "高压电池系统内最高单体电压";
CM_ SG_ 1448 BMSH_TempSensor_MinTemp "电池最低温度";
CM_ SG_ 1448 BMSH_TempSensor_MaxTemp "电池最高温度";
CM_ SG_ 1436 BMSH_InsulationResis "高压电池包检测的绝缘电阻值0xFFFE:Abnormal";
CM_ SG_ 1103 BMS_8_CC2Sts "仪表可用于显示充电连接";
CM_ SG_ 1103 BMSH_SOH "电池健康指数";
CM_ SG_ 1103 BMSH_LeftChargeTime "剩余充电时间";
CM_ SG_ 1083 BMSH_PackPowerRealTime "动力电池包实时功率";
CM_ SG_ 1083 BMSH_PackRemainEnergy "电池系统剩余电量";
CM_ SG_ 1083 BMSH_SOCDisp "电池电量显示";
CM_ SG_ 856 TBOX_TimeToStopChargeMinuteFed "充电时间反馈";
CM_ SG_ 856 TBOX_TimeToStopChargeHourFed "充电时间反馈";
CM_ SG_ 856 TBOX_TimeToStartChargeMinuteFed "充电时间反馈";
CM_ SG_ 856 TBOX_TimeToStartChargeHourFed "充电时间反馈";
CM_ SG_ 856 TBOX_ChargeModeSts "充电模式状态反馈";
CM_ BO_ 1025 "外部音效控制模块";
CM_ SG_ 1025 Welcome_OutsoundSts "车外迎宾音效选项状态";
CM_ SG_ 1025 Person_RemindSts "行人提醒开关";
CM_ SG_ 1025 Welcome_Outsound_SwitchSts "车外迎宾音效开关状态";
CM_ SG_ 803 MFS3_AVM "左侧方控自定义按键";
CM_ SG_ 803 MFS3_ICM_Right "左侧方控OK按键";
CM_ SG_ 803 MFS3_ICM_Left "左侧方控右按键";
CM_ SG_ 803 MFS3_ICM_Down_Zoom_Out "左侧方控左按键";
CM_ SG_ 803 MFS3_ICM_UP_Zoom_In "左侧方控向下按键";
CM_ SG_ 803 MFS3_Instrument_SetReturn "左侧方控向上按键";
CM_ SG_ 1120 Enter_super_fast_charge "进入超级快充信号反馈
0x00：未进入超级快充
0x01：进入华为超级快充
0x02：进入小米超级快充
0x03：进入OPPO超级快充
0x04~0xff：预留";
CM_ SG_ 1120 WCM_Electricity_decimal "无线充电电量反馈_小数部分";
CM_ SG_ 1120 WCM_Electricity_integer "无线充电电量反馈_整数部分";
CM_ SG_ 1120 WCM_PhoneDetectionStatus "手机遗忘提醒信号";
CM_ SG_ 1120 WCM_WirelessChargingStatus "无线充电工作状态反馈信号
0x01：待机
0x02：充电中
0x03：输入过压保护
0x04：输入欠压保护
0x05：FOD
0x06：过温保护
0x07：充电完成（需要手机支持该功能）
0x08：其它故障（一般为接收端故障）
0x09：PEPS停止充电
0x0A~0x0F：Reserved";
CM_ SG_ 1120 WCM_WirelessChargingSetStatus "无线充电模块设置反馈信号";
CM_ SG_ 1338 PM2_5_ErrSts "PM25错误状态";
CM_ SG_ 1338 PM2_5_Sts "PM25传感器状态";
CM_ SG_ 1338 PM2_5_AirIOutQLevel "室外空气质量等级";
CM_ SG_ 1338 PM2_5_AirInQLevel "室内空气质量等级";
CM_ SG_ 1338 PM2_5_Outdensity "室外空气PM2_5浓度";
CM_ SG_ 1338 PM2_5_Indensity "室内空气PM2_5浓度";
CM_ SG_ 787 ABS_ESP_3_AVHSts "AVH状态";
CM_ SG_ 1136 YAS_2_LongitudinalAcceleration "纵向加速度";
CM_ SG_ 1141 RAD2_Radar_FunctionModel_Status "雷达故障状态";
CM_ SG_ 1141 RAD2_LHSFRadarSensorDistance "左前侧探头信息";
CM_ SG_ 1141 RAD2_RHSFRadarSensorDistance "右前侧探头信息";
CM_ SG_ 1141 RAD2_LHSRRadarSensorDistance "左后侧探头信息";
CM_ SG_ 1141 RAD2_RHSRRadarSensorDistance "右后侧探头信息";
CM_ SG_ 1050 AVM_APA_SystemSts "APA功能内容状态
0x0:供应商内部没有开启APA功能时，此信号发0x0
0x1:standby模式
0x2:寻车过程中
0x3:泊车过程中
0x4:当车辆停止在目标的泊车位置时，此信号发0x4
0x5:APA故障
0x6:APA中断";
CM_ SG_ 1050 APA_Parking_Space_Search_Sts "车位搜索状态，用于中控声音提示";
CM_ SG_ 1050 AVM_FactoryMode "AVM工作模式";
CM_ SG_ 1050 APA_3AVMFeedbackSts_RemoteMode "远程状态下_AVM工作状态";
CM_ SG_ 1050 AVMDisplaySts "AVM显示开关状态";
CM_ SG_ 1288 APA_2_AVMStatusFault "AVM系统故障_正常";
CM_ SG_ 1288 APA_2_AVMFaultStatusCameraRight "右摄像头故障_正常";
CM_ SG_ 1288 APA_2_AVMFaultStatusCameraRear "后摄像头故障_正常";
CM_ SG_ 1288 APA_2_AVMFaultStatusCameraLeft "左摄像头故障_正常";
CM_ SG_ 1288 APA_2_AVMFaultStatusCameraFront "前摄像头故障_正常";
CM_ SG_ 773 FRM_3_CRC "CRC (SAE J1850 CRC-8)";
CM_ SG_ 773 FRM_3_MessageCounter "报文计数";
CM_ SG_ 773 FRM_3_DistanceWarning_On_Off_Sts "距离报警开关";
CM_ SG_ 773 FRM_3_AEB_ON_OFF_Sts "紧急制动开关";
CM_ SG_ 773 FRM_3_FCW_OPTION_Sts "前碰撞预警距离设置";
CM_ SG_ 773 FRM_3_FCW_ON_OFF_Sts "前碰撞预警开关";
CM_ SG_ 773 FRM_3_TimeGapLastSet_DVD "时距设置请求开关";
CM_ SG_ 773 FRM_3_FCW_PreWarning "FCW预警";
CM_ SG_ 773 FRM_3_DistanceWarning "FDW报警";
CM_ SG_ 773 FRM_3_AEBMode "AEB模式";
CM_ SG_ 773 FRM_3_FCWMode "FCW模式";
CM_ SG_ 773 FRM_3_Obiect_Dx "目标车辆在X向的位置";
CM_ SG_ 773 FRM_3_ACCMode "ACC模式";
CM_ SG_ 773 FRM_3_TimeGapSet_ICM "时距设置";
CM_ SG_ 773 FRM_3_TimeGapSet_DVD "时距设置";
CM_ SG_ 773 FRM_3_TakeOverReq "脱手检测";
CM_ SG_ 773 FRM_3_Textinfo "文字提示";
CM_ SG_ 773 FRM_3_FrontObject_Type "触发报警时刻的目标车辆类型";
CM_ SG_ 773 FRM_3_ObjValid "发现目标车辆";
CM_ SG_ 773 FRM_3_DxTarObj "与其他车距距离";
CM_ SG_ 773 FRM_3_VSetDis "期望车速";
CM_ SG_ 1241 FuelTankLidSystemFailureSts "加油小门系统故障信号";
CM_ SG_ 1241 FuelTankPressureConditionReached "油箱压力状态信号";
CM_ SG_ 632 EMS_4_IntakeAirPressure "进气压力";
CM_ SG_ 632 EMS_4_EngineSts "发动机状态";
CM_ SG_ 1202 GSM_CHKSM_GSM_1 "((Byte0+Byte1+Byte2)AND 0xFF) XOR 0xFF";
CM_ SG_ 1202 ACC_Cruise_Control "ACC巡航控制";
CM_ SG_ 1202 GSM_GearShiftPos "挡位";
CM_ SG_ 1507 DHM_1_Doorkonb_time_freeback "门把手收回时间反馈";
CM_ SG_ 1518 CEM_DHM_handlelockswitchfeedback "隐藏式门把手闭锁反馈";
CM_ SG_ 1518 CEM_DHM_handleunlockswitchfeedba "隐藏式门把手解锁反馈";
CM_ SG_ 1517 CEM_SRF_lockingreason "天窗关闭原因反馈";
CM_ SG_ 1517 CEM_RR_window_up_Reason_feedback "右后乘客侧车窗上升原因反馈";
CM_ SG_ 1517 CEM_LR_window_up_Reason_feedback "左后乘客侧车窗上升原因反馈";
CM_ SG_ 1517 CEM_Passenger_window_up_Reason_f "副驾车窗上升原因反馈";
CM_ SG_ 1517 CEM_Driver_window_up_Reason_feed "主驾车窗上升原因反馈";
CM_ SG_ 1504 CEM_SRFclosingConditions "天窗关闭条件";
CM_ SG_ 1504 CEM_Abat_VentCMDSts "遮阳帘开启百分制反馈";
CM_ SG_ 1504 CEM_PSRFCMDSts "天窗开启百分制反馈";
CM_ SG_ 1168 CEM_ALM_1_SceneMode_ControlSwitc "关联智能场景氛围灯控制开关";
CM_ SG_ 1168 CEM_ALM_1_DeletePeronalSet_FB "删除自定义设置反馈";
CM_ SG_ 1168 CEM_ALM_1_PersonalBeamEn "灯光自定义设置使能信号";
CM_ SG_ 1168 CEM_ALM_1_PersonalSeatEn "座椅自定义设置使能信号";
CM_ SG_ 1168 CEM_ALM_1_Seat_Set_Status "座椅设置状态";
CM_ SG_ 1168 CEM_ALM_1_Seat_Set_Pop_Up "座椅设置弹出";
CM_ SG_ 1168 CEM_ALM_1_Wash_Car_Status "洗车模式状态";
CM_ SG_ 1168 CEM_ALM_1_PersonalSetSts "自定义设置状态";
CM_ SG_ 1168 CEM_ALM_1_STAT_WelcomeWaterLamp "迎宾流水灯开关";
CM_ SG_ 1168 CEM_ALM_1_STAT_AssociatedWithDri "关联驾驶模式开关";
CM_ SG_ 1168 CEM_ALM_1_STAT_Music "是否允许音乐律动";
CM_ SG_ 1168 CEM_ALM_1_STAT_Apiluminance "氛围灯亮度";
CM_ SG_ 1168 CEM_ALM_1_STAT_Static_Colour "静态颜色";
CM_ SG_ 1168 CEM_ALM_1_STAT_StaticEffect "静态效果";
CM_ SG_ 1168 CEM_ALM_1_STAT_ControlSwitch "氛围灯开关状态";
CM_ SG_ 1168 CEM_ALM_1_STAT_DMSMonitoring "DMS监测开关状态";
CM_ SG_ 1168 CEM_ALM_1_STAT_PM2_5Monitoring "PM2.5监测状态";
CM_ SG_ 1168 CEM_ALM_1_STAT_DriveApiluminance "行驶中氛围灯亮度状态";
CM_ SG_ 1168 CEM_ALM_1_STAT_64Colour "多元颜色设置状态";
CM_ SG_ 1492 CEM_DriverLumbart_UD_Locaton "主驾腰托上下调节位置反馈";
CM_ SG_ 1492 CEM_PassengerSeat_LegUD_Locaton "副驾腿托上下调节位置反馈";
CM_ SG_ 1492 CEM_PassengerSeat_FR_Locaton "副驾座椅前后调节位置反馈";
CM_ SG_ 1492 CEM_PassengerSeat_BackFR_Locaton "副驾靠背前后调节位置反馈";
CM_ SG_ 1492 CEM_DriverSeat_RearendUD_Locaton "主驾座椅后端上下调节位置反馈";
CM_ SG_ 1492 CEM_DriverSeat_FrontendUD_Locato "主驾座椅前端上下调节位置反馈";
CM_ SG_ 1492 CEM_DriverSeat_FR_Locaton "主驾座椅前后调节位置反馈";
CM_ SG_ 1492 CEM_DriverSeat_BackFR_Locaton "主驾靠背前后调节位置反馈";
CM_ SG_ 1492 CEM_Rmirror_UD_Locaton "右后视镜上下调节位置反馈";
CM_ SG_ 1492 CEM_Rmirror_LR_Locaton "右后视镜左右调节位置反馈";
CM_ SG_ 1492 CEM_Lmirror_UD_Locaton "左后视镜上下调节位置反馈";
CM_ SG_ 1492 CEM_Lmirror_LR_Locaton "左后视镜左右调节位置反馈";
CM_ SG_ 1476 CEM_Psngrseat_Location "副驾座椅记忆反馈";
CM_ SG_ 1476 CEM_PassengerSeat_LegUDSts "副驾座椅腿托上下调节反馈";
CM_ SG_ 1476 CEM_PassengerSeat_BackFRSts "副驾座椅靠背前后调节反馈";
CM_ SG_ 1476 CEM_PassengerSeat_FRSts "副驾座椅前后调节反馈";
CM_ SG_ 1476 CEM_massagemodeSts "副驾按摩模式设置反馈";
CM_ SG_ 1476 CEM_passageVibrationSts "副驾按摩强度设置反馈";
CM_ SG_ 1476 CEM_Passenger_massageSts "副驾按摩开关反馈";
CM_ SG_ 1476 CEM_DriverLumbart_FR_Locaton "主驾腰托前后调节位置反馈";
CM_ SG_ 1476 CEM_Mirror_Driverseat_Location "外后视镜及主驾座椅记忆反馈";
CM_ SG_ 1476 CEM_UnderVoltageSts "亏电提醒开关反馈";
CM_ SG_ 1476 CEM_RearWiper_SwitchSts "自动雨刮使能开关反馈";
CM_ SG_ 1476 BCM_Wiper_MaintenanceSts "雨刮维修模式状态";
CM_ SG_ 1476 CEM_Mirror_Fold_SwitchSts "当前后视镜折叠状态";
CM_ SG_ 1476 CEM_IPM__FRSeatHeatVentSwSts "副驾座椅通风加热状态
（PHEV项目使用）";
CM_ SG_ 1476 CEM_IPM_FLSeatHeatVentSwSts "主驾座椅通风加热状态
(PHEV项目使用）";
CM_ SG_ 1476 CEM_DriverLumbart_UDSts "主驾腰托上下调节反馈";
CM_ SG_ 1476 CEM_DriverLumbart_FRSts "主驾腰托前后调节反馈";
CM_ SG_ 1476 CEM_DriverSeat_RearendUDSts "主驾座椅后端上下调节反馈";
CM_ SG_ 1476 CEM_DriverSeat_FrontendUDSts "主驾座椅前端上下调节反馈";
CM_ SG_ 1476 CEM_DriverSeat_FRSts "主驾座椅前后调节反馈";
CM_ SG_ 1476 CEM_DriverSeat_BackFRSts "主机座椅靠背前后调节反馈";
CM_ SG_ 1476 CEM_MirrorFlip_CFGSts "外后视镜倒车翻转设置反馈";
CM_ SG_ 1476 CEM_RightMirrorCtrlSts "右后视镜镜片被控制状态";
CM_ SG_ 1476 CEM_LeftMirrorCtrlSts "左后视镜镜片被控制状态";
CM_ SG_ 1476 CEM_RHRdoor_buttonsts "右后侧自定义开关";
CM_ SG_ 1476 CEM_LHRdoor_buttonsts "左后侧自定义开关";
CM_ SG_ 1476 CEM_PsngrDoor_buttonsts "副驾侧自定义开关";
CM_ SG_ 1476 CEM_Smart_HighBeamSts "智能大灯使能开关状态";
CM_ SG_ 1476 CEM_HighBeam_AdjustSts "大灯高度调节状态";
CM_ SG_ 1535 CEM_3_passenger_Welcome_Seat_Sts "座椅迎宾礼让反馈状态";
CM_ SG_ 1535 CEM_DHM_Doorkonbmode_feedback "门把手是否自动弹出模式反馈";
CM_ SG_ 1535 CEM_DHM_Driver_unlockmode_feedba "驾驶员解锁模式反馈";
CM_ SG_ 1535 CEM_UVC_LuminanceBf "UVC亮度反馈";
CM_ SG_ 1535 CEM_UVC_WorkingBf "UVC控制反馈";
CM_ SG_ 1535 CEM_3_Welcome_Seat_Sts "座椅迎宾礼让反馈状态";
CM_ SG_ 1535 CEM_IPM_3_ACMAXReq_Sts "AC MAX请求信号";
CM_ SG_ 1535 CEM_3_PM25DisplayToggle_Sts "PM2.5内外显示切换状态反馈";
CM_ SG_ 1535 CEM_3_DWM_Sts_Msg "天窗状况反馈";
CM_ SG_ 1535 CEM_3_EngineControlSts "语音启动发动机状态反馈";
CM_ SG_ 914 BCM_4_AlarmMode "设防状态信号";
CM_ SG_ 914 CEM_2_RemoteTrunkOnlySts "仅钥匙开启后背门反馈";
CM_ SG_ 914 BCM_4_AutoLockSts "自动上锁模式状态";
CM_ SG_ 914 CEM_2RearDefrosts "后除霜
（PHEV项目使用）";
CM_ SG_ 914 CEM_2_HazardLampForUrgencyBrakeS "紧急制动报警灯点亮提醒模式状态";
CM_ SG_ 914 CEM_2_Mirror_FlipSts "外后视镜倒车翻转";
CM_ SG_ 914 BCM_4_RemoteLockFeedbackSts "设防提示状态";
CM_ SG_ 914 BCM_4_AutoUnlockSts "自动解锁模式状态";
CM_ SG_ 914 CEM_2_WiperSts "雨刮器状态";
CM_ SG_ 914 CEM_2_RainDetected "雨量状态";
CM_ SG_ 914 CEM_2_WiperSensitivitySWSts "雨刮灵敏度开关状态反馈";
CM_ SG_ 914 CEM_2_RainSensorFailSts "雨量传感器故障状态";
CM_ SG_ 914 BCM_4_RARDfstCmd "后除霜信息";
CM_ SG_ 914 CEM_2_WiperSelectionSts "雨刮器选择状态";
CM_ SG_ 914 BCM_4_FrontFogLightSts "前雾灯状态";
CM_ SG_ 914 CEM_2_ReverseGearSwitch "倒挡开关状态";
CM_ SG_ 914 BCM_4_RearFogLightSts "后雾灯";
CM_ SG_ 914 CEM_2_External_WelcomelightSts "外部灯光迎宾";
CM_ SG_ 914 BCM_4_Mirror_Fold_Sts "后视镜折叠状态";
CM_ SG_ 914 BCM_4_TrunkSts "后背门状态";
CM_ SG_ 914 BCM_4_LHRdoorSts "左后门状态";
CM_ SG_ 914 BCM_4_RHRDoorSts "右后门状态";
CM_ SG_ 914 CEM_2_SunRoofSts "天窗状态";
CM_ SG_ 914 BCM_4_BonnetSts "引擎盖状态";
CM_ SG_ 914 BCM_4_PsngrDoorSts "副驾门状态";
CM_ SG_ 914 BCM_4_DriverDoorSts "主驾门状态";
CM_ SG_ 914 BCM_4_FollowMeTimeSts "伴我回家时间状态";
CM_ SG_ 914 BCM_4_BlankingnumberSts "变道灯次数状态";
CM_ SG_ 914 CEM_2_DirectionIndLeft "左侧方向指示灯";
CM_ SG_ 914 CEM_2_DirectionIndRight "右侧方向指示灯";
CM_ SG_ 914 BCM_4_DRLSts "逻辑灯状态";
CM_ SG_ 914 BCM_4_LowBeamSts "近光状态";
CM_ SG_ 914 CEM_2_Laser_LightSts "照地灯状态";
CM_ SG_ 914 BCM_4_HighBeamSts "远光状态";
CM_ SG_ 914 BCM_4_ParkTailLightSts "制动灯状态";
CM_ SG_ 914 BCM_4_BrakePedalSts "刹车踏板信号";
CM_ SG_ 914 BCM_4_LHTurnlightSts "左后转向灯状态";
CM_ SG_ 914 BCM_4_RHTurnlightSts "右后转向灯状态";
CM_ SG_ 914 CEM_2_BlankchanginglaneSts "变道闪光开关状态";
CM_ SG_ 914 BCM_4_KeySts "钥匙状态";
CM_ SG_ 914 CEM_2_FollowMeHomeSts "伴我回家开关状态";
CM_ SG_ 914 CEM_2_KeyRemindWarning "钥匙遗忘提醒";
CM_ SG_ 914 BCM_4_ParkLightOnWarning "制动灯亮报警";
CM_ SG_ 914 BCM_4_FollowMeHomeTimeSts "伴我回家时间状态";
CM_ SG_ 1340 RBCM_FGHeat_Request_CommandFB "(前风档喷雾加热反馈)（JX65国际二阶段用）";
CM_ SG_ 1340 RBCM_2_RRSeatHeatVentSwSts "右后座椅加热状态（JX65国际二阶段用）";
CM_ SG_ 1340 RBCM_2_LRSeatHeatVentSwSts "左后座椅加热状态（JX65国际二阶段用）";
CM_ SG_ 1340 RBCM_MFS_ShakeSts "方向盘震动";
CM_ SG_ 1306 CEM_IPM_AC_DisplaySts "AC显示状态反馈";
CM_ SG_ 1306 CLM_2_Custom_Air_Conditioning "自定义空调";
CM_ SG_ 1306 CLM_2_Automatic_Ventilation "空调自动通风";
CM_ SG_ 1306 CLM_2_First_BlowingSts "空调启动时第一口风状态；";
CM_ SG_ 1306 CEM_IPM_FRSeatHeatVentSwSts "副驾驶座椅通风加热状态
(主项目使用）";
CM_ SG_ 1306 CEM_IPM_FLSeatHeatVentSwSts "主驾驶座椅通风加热状态
（主项目使用）";
CM_ SG_ 1306 CEM_IPM_TempknobRollingCounter "温度档位_电动需求";
CM_ SG_ 1306 CLM_2_AnionPurify "负离子开启请求";
CM_ SG_ 1306 CEM_IPM_PM25_Detect "PM2_5检测功能";
CM_ SG_ 1306 CLM_2_SyncSts "同步功能";
CM_ SG_ 1306 CLM_2_FrontAutoACSts "前排自动功能";
CM_ SG_ 1306 CEM_IPM_RearBlowModeSts "后排吹风模式设置";
CM_ SG_ 1306 CEM_IPM_RearAutoACSts "空调工作状态
Active关闭空调
Not_Active打开空调";
CM_ SG_ 1306 CEM_IPM_RearBlowSpdCtrlSts "后排风速设置";
CM_ SG_ 1306 CEM_IPM_RearTempsts "后排温度设置功能";
CM_ SG_ 1306 CLM_2_RearOFFsts "后排关闭功能";
CM_ SG_ 1306 CEM_IPM_RearDefrosts "后除霜
（主项目使用）";
CM_ SG_ 1306 CLM_2_FrontOFFSts "空调关闭";
CM_ SG_ 1306 CLM_2_ACStatus "AC_状态";
CM_ SG_ 1306 CLM_2_RecyMode "内外循环";
CM_ SG_ 1306 CLM_2_FrontBlowModeSts "前排吹风模式设置";
CM_ SG_ 1306 CLM_2_FrontBlowSpdCtrlsts "前排风速设置";
CM_ SG_ 1306 CLM_2_FRTempsts "前排右侧温度设置";
CM_ SG_ 1306 CLM_2_FLTempsts "前排左侧温度设置";
CM_ SG_ 1381 S_RAIN "Rain_detected
检测到有无雨量";
CM_ SG_ 1381 S_AUTOPANEL "Auto_Panel_Dim_Request
自动亮灯:小灯";
BA_DEF_  "NmAsrCanMsgCycleTime" INT 1000 1000;
BA_DEF_  "NmAsrRepeatMessageTime" INT 3000 3000;
BA_DEF_  "NmAsrWaitBusSleepTime" INT 1500 1500;
BA_DEF_  "NmAsrTimeoutTime" INT 2500 2500;
BA_DEF_  "NmAsrBaseAddress" HEX 0 2047;
BA_DEF_  "NmAsrMessageCount" INT 128 128;
BA_DEF_  "NmType" STRING ;
BA_DEF_  "ILTxTimeout" INT 0 65535;
BA_DEF_  "Manufacturer" STRING ;
BA_DEF_ SG_  "GenSigTimeoutValue" INT 0 2147483647;
BA_DEF_ SG_  "GenSigStartValue" INT 0 2147483647;
BA_DEF_ SG_  "GenSigInactiveValue" INT 0 2147483647;
BA_DEF_ BO_  "TpTxIndex" INT 0 255;
BA_DEF_ BO_  "DiagUudtResponse" ENUM  "False","True";
BA_DEF_ BO_  "DiagResponse" ENUM  "No","Yes";
BA_DEF_ BO_  "DiagRequest" ENUM  "No","Yes";
BA_DEF_ BO_  "DiagState" ENUM  "No","Yes";
BA_DEF_ BO_  "NmAsrMessage" ENUM  "No","Yes";
BA_DEF_ BO_  "GenMsgFastOnStart" INT 0 65535;
BA_DEF_ BO_  "GenMsgCycleTimeFast" INT 0 65535;
BA_DEF_ BO_  "GenMsgNrOfRepetition" INT 0 65535;
BA_DEF_ BO_  "GenMsgStartDelayTime" INT 0 65535;
BA_DEF_ BO_  "GenMsgCycleTime" INT 0 65535;
BA_DEF_ BO_  "GenMsgDelayTime" INT 0 65535;
BA_DEF_ SG_  "GenSigSendType" ENUM  "Cyclic","OnWrite","OnWriteWithRepetition","OnChange","OnChangeWithRepetition","IfActive","IfActiveWithRepetition","NoSigSendType","OnChangeAndIfActive","OnChangeAndIfActiveWithRepetition";
BA_DEF_ BO_  "GenMsgSendType" ENUM  "Cyclic","NotUsed","NotUsed","NotUsed","NotUsed","NotUsed","NotUsed","IfActive","NoMsgSendType";
BA_DEF_ BO_  "GenMsgILSupport" ENUM  "No","Yes";
BA_DEF_ BU_  "NmStationAddress" HEX 0 255;
BA_DEF_ BU_  "NmAsrCanMsgReducedTime" INT 500 818;
BA_DEF_ BU_  "NmAsrCanMsgCycleOffset" INT 0 635;
BA_DEF_ BU_  "NmAsrNodeIdentifier" HEX 0 255;
BA_DEF_ BU_  "NmAsrNode" ENUM  "No","Yes";
BA_DEF_ BU_  "ILUsed" ENUM  "No","Yes";
BA_DEF_ SG_  "SystemSignalLongSymbol" STRING ;
BA_DEF_REL_ BU_SG_REL_  "GenSigTimeoutTime" INT 0 65535;
BA_DEF_DEF_  "NmAsrCanMsgCycleTime" 1000;
BA_DEF_DEF_  "NmAsrRepeatMessageTime" 3000;
BA_DEF_DEF_  "NmAsrWaitBusSleepTime" 1500;
BA_DEF_DEF_  "NmAsrTimeoutTime" 2500;
BA_DEF_DEF_  "NmAsrBaseAddress" 1536;
BA_DEF_DEF_  "NmAsrMessageCount" 128;
BA_DEF_DEF_  "NmType" "NmAsr";
BA_DEF_DEF_  "ILTxTimeout" 0;
BA_DEF_DEF_  "Manufacturer" "Vector";
BA_DEF_DEF_  "GenSigTimeoutValue" 0;
BA_DEF_DEF_  "GenSigStartValue" 0;
BA_DEF_DEF_  "GenSigInactiveValue" 0;
BA_DEF_DEF_  "TpTxIndex" 0;
BA_DEF_DEF_  "DiagUudtResponse" "False";
BA_DEF_DEF_  "DiagResponse" "No";
BA_DEF_DEF_  "DiagRequest" "No";
BA_DEF_DEF_  "DiagState" "No";
BA_DEF_DEF_  "NmAsrMessage" "No";
BA_DEF_DEF_  "GenMsgFastOnStart" 0;
BA_DEF_DEF_  "GenMsgCycleTimeFast" 0;
BA_DEF_DEF_  "GenMsgNrOfRepetition" 3;
BA_DEF_DEF_  "GenMsgStartDelayTime" 0;
BA_DEF_DEF_  "GenMsgCycleTime" 0;
BA_DEF_DEF_  "GenMsgDelayTime" 0;
BA_DEF_DEF_  "GenSigSendType" "Cyclic";
BA_DEF_DEF_  "GenMsgSendType" "Cyclic";
BA_DEF_DEF_  "GenMsgILSupport" "No";
BA_DEF_DEF_  "NmStationAddress" 255;
BA_DEF_DEF_  "NmAsrCanMsgReducedTime" 575;
BA_DEF_DEF_  "NmAsrCanMsgCycleOffset" 0;
BA_DEF_DEF_  "NmAsrNodeIdentifier" 255;
BA_DEF_DEF_  "NmAsrNode" "No";
BA_DEF_DEF_  "ILUsed" "No";
BA_DEF_DEF_REL_ "GenSigTimeoutTime" 0;
BA_DEF_DEF_  "SystemSignalLongSymbol" "";
BA_ "NmAsrNodeIdentifier" BU_ Tester 0;
BA_ "NmAsrNodeIdentifier" BU_ WCM 0;
BA_ "NmAsrNodeIdentifier" BU_ MFS 0;
BA_ "NmStationAddress" BU_ HUD 21;
BA_ "NmAsrNodeIdentifier" BU_ HUD 21;
BA_ "NmAsrNode" BU_ HUD 1;
BA_ "ILUsed" BU_ HUD 1;
BA_ "NmStationAddress" BU_ CGW 0;
BA_ "NmAsrNodeIdentifier" BU_ CGW 0;
BA_ "NmAsrNode" BU_ CGW 1;
BA_ "ILUsed" BU_ CGW 1;
BA_ "NmStationAddress" BU_ IHU 0;
BA_ "NmAsrNodeIdentifier" BU_ IHU 24;
BA_ "GenMsgNrOfRepetition" BO_ 1360 0;
BA_ "GenMsgCycleTime" BO_ 1360 100;
BA_ "GenMsgILSupport" BO_ 1360 1;
BA_ "GenMsgCycleTimeFast" BO_ 1313 100;
BA_ "GenMsgNrOfRepetition" BO_ 1313 2;
BA_ "GenMsgSendType" BO_ 1313 8;
BA_ "GenMsgILSupport" BO_ 1313 1;
BA_ "GenMsgNrOfRepetition" BO_ 936 0;
BA_ "GenMsgCycleTime" BO_ 936 100;
BA_ "GenMsgILSupport" BO_ 936 1;
BA_ "GenMsgNrOfRepetition" BO_ 1121 0;
BA_ "GenMsgCycleTime" BO_ 1121 100;
BA_ "GenMsgILSupport" BO_ 1121 1;
BA_ "GenMsgILSupport" BO_ 916 1;
BA_ "GenMsgCycleTime" BO_ 916 100;
BA_ "GenMsgNrOfRepetition" BO_ 916 0;
BA_ "GenMsgILSupport" BO_ 1299 1;
BA_ "GenMsgCycleTime" BO_ 1299 500;
BA_ "GenMsgNrOfRepetition" BO_ 1299 2;
BA_ "GenMsgILSupport" BO_ 1349 1;
BA_ "GenMsgCycleTime" BO_ 1349 100;
BA_ "GenMsgNrOfRepetition" BO_ 1349 2;
BA_ "GenMsgILSupport" BO_ 1217 1;
BA_ "GenMsgCycleTime" BO_ 1217 500;
BA_ "GenMsgNrOfRepetition" BO_ 1217 0;
BA_ "GenMsgILSupport" BO_ 1400 1;
BA_ "GenMsgCycleTime" BO_ 1400 500;
BA_ "GenMsgNrOfRepetition" BO_ 1400 2;
BA_ "GenMsgCycleTimeFast" BO_ 1400 100;
BA_ "GenMsgILSupport" BO_ 1297 1;
BA_ "GenMsgCycleTime" BO_ 1297 1000;
BA_ "GenMsgNrOfRepetition" BO_ 1297 2;
BA_ "GenMsgCycleTimeFast" BO_ 1297 100;
BA_ "GenMsgILSupport" BO_ 1286 1;
BA_ "GenMsgCycleTime" BO_ 1286 500;
BA_ "GenMsgNrOfRepetition" BO_ 1286 0;
BA_ "GenMsgNrOfRepetition" BO_ 1298 2;
BA_ "GenMsgILSupport" BO_ 1298 1;
BA_ "GenMsgCycleTime" BO_ 1298 1000;
BA_ "GenMsgCycleTimeFast" BO_ 1298 100;
BA_ "GenMsgILSupport" BO_ 1216 1;
BA_ "GenMsgCycleTime" BO_ 1216 500;
BA_ "GenMsgNrOfRepetition" BO_ 1216 0;
BA_ "GenMsgNrOfRepetition" BO_ 1444 0;
BA_ "GenMsgCycleTime" BO_ 1444 100;
BA_ "GenMsgILSupport" BO_ 1444 1;
BA_ "GenMsgILSupport" BO_ 1296 1;
BA_ "GenMsgCycleTime" BO_ 1296 500;
BA_ "GenMsgNrOfRepetition" BO_ 1296 0;
BA_ "GenMsgNrOfRepetition" BO_ 1480 0;
BA_ "GenMsgCycleTime" BO_ 1480 10000;
BA_ "GenMsgILSupport" BO_ 1480 1;
BA_ "GenMsgILSupport" BO_ 1324 1;
BA_ "GenMsgCycleTime" BO_ 1324 500;
BA_ "GenMsgNrOfRepetition" BO_ 1324 0;
BA_ "GenMsgILSupport" BO_ 1061 1;
BA_ "GenMsgCycleTime" BO_ 1061 100;
BA_ "GenMsgNrOfRepetition" BO_ 1061 0;
BA_ "GenMsgILSupport" BO_ 1390 1;
BA_ "GenMsgCycleTime" BO_ 1390 100;
BA_ "GenMsgNrOfRepetition" BO_ 1390 0;
BA_ "GenMsgILSupport" BO_ 1440 1;
BA_ "GenMsgCycleTime" BO_ 1440 100;
BA_ "GenMsgNrOfRepetition" BO_ 1440 0;
BA_ "GenMsgCycleTime" BO_ 1534 500;
BA_ "GenMsgILSupport" BO_ 1534 1;
BA_ "GenMsgNrOfRepetition" BO_ 1534 0;
BA_ "GenMsgCycleTimeFast" BO_ 1416 100;
BA_ "GenMsgNrOfRepetition" BO_ 1416 2;
BA_ "GenMsgSendType" BO_ 1416 8;
BA_ "GenMsgILSupport" BO_ 1416 1;
BA_ "GenMsgILSupport" BO_ 1330 1;
BA_ "GenMsgSendType" BO_ 1330 8;
BA_ "GenMsgNrOfRepetition" BO_ 1330 2;
BA_ "GenMsgCycleTimeFast" BO_ 1330 100;
BA_ "GenMsgILSupport" BO_ 805 1;
BA_ "GenMsgCycleTime" BO_ 805 20;
BA_ "GenMsgNrOfRepetition" BO_ 805 0;
BA_ "GenMsgILSupport" BO_ 896 1;
BA_ "GenMsgCycleTime" BO_ 896 100;
BA_ "GenMsgNrOfRepetition" BO_ 896 0;
BA_ "GenMsgILSupport" BO_ 913 1;
BA_ "GenMsgCycleTime" BO_ 913 20;
BA_ "GenMsgCycleTimeFast" BO_ 913 20;
BA_ "GenMsgILSupport" BO_ 554 1;
BA_ "GenMsgCycleTime" BO_ 554 20;
BA_ "GenMsgNrOfRepetition" BO_ 554 0;
BA_ "GenMsgILSupport" BO_ 1421 1;
BA_ "GenMsgCycleTime" BO_ 1421 500;
BA_ "GenMsgNrOfRepetition" BO_ 1421 0;
BA_ "GenMsgILSupport" BO_ 1253 1;
BA_ "GenMsgCycleTime" BO_ 1253 100;
BA_ "GenMsgNrOfRepetition" BO_ 1253 0;
BA_ "GenMsgILSupport" BO_ 745 1;
BA_ "GenMsgCycleTime" BO_ 745 10;
BA_ "GenMsgNrOfRepetition" BO_ 745 0;
BA_ "GenMsgILSupport" BO_ 250 1;
BA_ "GenMsgCycleTime" BO_ 250 10;
BA_ "GenMsgNrOfRepetition" BO_ 250 0;
BA_ "GenMsgCycleTime" BO_ 932 100;
BA_ "GenMsgILSupport" BO_ 932 1;
BA_ "GenMsgNrOfRepetition" BO_ 932 0;
BA_ "GenMsgCycleTime" BO_ 768 10;
BA_ "GenMsgILSupport" BO_ 768 1;
BA_ "GenMsgNrOfRepetition" BO_ 768 0;
BA_ "GenMsgILSupport" BO_ 1414 1;
BA_ "GenMsgSendType" BO_ 1414 8;
BA_ "GenMsgCycleTimeFast" BO_ 1414 100;
BA_ "GenMsgNrOfRepetition" BO_ 1414 2;
BA_ "GenMsgILSupport" BO_ 1413 1;
BA_ "GenMsgSendType" BO_ 1413 8;
BA_ "GenMsgCycleTimeFast" BO_ 1413 100;
BA_ "GenMsgNrOfRepetition" BO_ 1413 2;
BA_ "GenMsgILSupport" BO_ 923 1;
BA_ "GenMsgCycleTime" BO_ 923 100;
BA_ "GenMsgNrOfRepetition" BO_ 923 0;
BA_ "GenMsgILSupport" BO_ 922 1;
BA_ "GenMsgCycleTime" BO_ 922 100;
BA_ "GenMsgNrOfRepetition" BO_ 922 0;
BA_ "GenMsgILSupport" BO_ 1114 1;
BA_ "GenMsgSendType" BO_ 1114 8;
BA_ "GenMsgCycleTimeFast" BO_ 1114 20;
BA_ "GenMsgNrOfRepetition" BO_ 1114 2;
BA_ "GenMsgILSupport" BO_ 804 1;
BA_ "GenMsgCycleTime" BO_ 804 20;
BA_ "GenMsgNrOfRepetition" BO_ 804 0;
BA_ "GenMsgNrOfRepetition" BO_ 1240 0;
BA_ "GenMsgCycleTime" BO_ 1240 100;
BA_ "GenMsgILSupport" BO_ 1240 1;
BA_ "GenMsgNrOfRepetition" BO_ 1245 0;
BA_ "GenMsgCycleTime" BO_ 1245 100;
BA_ "GenMsgILSupport" BO_ 1245 1;
BA_ "GenMsgILSupport" BO_ 1276 1;
BA_ "GenMsgCycleTimeFast" BO_ 1276 100;
BA_ "GenMsgSendType" BO_ 1276 8;
BA_ "GenMsgNrOfRepetition" BO_ 1276 2;
BA_ "GenMsgNrOfRepetition" BO_ 1251 0;
BA_ "GenMsgCycleTime" BO_ 1251 100;
BA_ "GenMsgILSupport" BO_ 1251 1;
BA_ "GenMsgILSupport" BO_ 1262 1;
BA_ "GenMsgCycleTime" BO_ 1262 500;
BA_ "GenMsgNrOfRepetition" BO_ 1262 0;
BA_ "GenMsgILSupport" BO_ 1322 1;
BA_ "GenMsgCycleTime" BO_ 1322 1000;
BA_ "GenMsgCycleTimeFast" BO_ 1322 100;
BA_ "GenMsgNrOfRepetition" BO_ 1322 2;
BA_ "GenMsgNrOfRepetition" BO_ 295 0;
BA_ "GenMsgCycleTime" BO_ 295 20;
BA_ "GenMsgILSupport" BO_ 295 1;
BA_ "GenMsgILSupport" BO_ 1111 1;
BA_ "GenMsgNrOfRepetition" BO_ 1111 0;
BA_ "GenMsgCycleTime" BO_ 1111 100;
BA_ "GenMsgILSupport" BO_ 1067 1;
BA_ "GenMsgNrOfRepetition" BO_ 1067 0;
BA_ "GenMsgCycleTime" BO_ 1067 100;
BA_ "GenMsgILSupport" BO_ 1057 1;
BA_ "GenMsgNrOfRepetition" BO_ 1057 0;
BA_ "GenMsgCycleTime" BO_ 1057 100;
BA_ "GenMsgILSupport" BO_ 1046 1;
BA_ "GenMsgNrOfRepetition" BO_ 1046 0;
BA_ "GenMsgCycleTime" BO_ 1046 100;
BA_ "GenMsgILSupport" BO_ 1142 1;
BA_ "GenMsgNrOfRepetition" BO_ 1142 0;
BA_ "GenMsgCycleTime" BO_ 1142 100;
BA_ "GenMsgILSupport" BO_ 1044 1;
BA_ "GenMsgNrOfRepetition" BO_ 1044 0;
BA_ "GenMsgCycleTime" BO_ 1044 100;
BA_ "GenMsgILSupport" BO_ 1034 1;
BA_ "GenMsgNrOfRepetition" BO_ 1034 0;
BA_ "GenMsgCycleTime" BO_ 1034 100;
BA_ "GenMsgILSupport" BO_ 1183 1;
BA_ "GenMsgNrOfRepetition" BO_ 1183 0;
BA_ "GenMsgCycleTime" BO_ 1183 100;
BA_ "GenMsgILSupport" BO_ 1472 1;
BA_ "GenMsgNrOfRepetition" BO_ 1472 0;
BA_ "GenMsgCycleTime" BO_ 1472 1000;
BA_ "GenMsgILSupport" BO_ 1449 1;
BA_ "GenMsgNrOfRepetition" BO_ 1449 0;
BA_ "GenMsgCycleTime" BO_ 1449 1000;
BA_ "GenMsgILSupport" BO_ 1448 1;
BA_ "GenMsgNrOfRepetition" BO_ 1448 0;
BA_ "GenMsgCycleTime" BO_ 1448 1000;
BA_ "GenMsgILSupport" BO_ 1436 1;
BA_ "GenMsgNrOfRepetition" BO_ 1436 0;
BA_ "GenMsgCycleTime" BO_ 1436 1000;
BA_ "GenMsgILSupport" BO_ 1103 1;
BA_ "GenMsgNrOfRepetition" BO_ 1103 0;
BA_ "GenMsgCycleTime" BO_ 1103 100;
BA_ "GenMsgILSupport" BO_ 1083 1;
BA_ "GenMsgNrOfRepetition" BO_ 1083 0;
BA_ "GenMsgCycleTime" BO_ 1083 100;
BA_ "GenMsgILSupport" BO_ 2047 1;
BA_ "GenMsgSendType" BO_ 2047 8;
BA_ "GenMsgCycleTimeFast" BO_ 2047 100;
BA_ "GenMsgILSupport" BO_ 856 1;
BA_ "GenMsgNrOfRepetition" BO_ 856 0;
BA_ "GenMsgCycleTime" BO_ 856 50;
BA_ "GenMsgILSupport" BO_ 1025 1;
BA_ "GenMsgNrOfRepetition" BO_ 1025 0;
BA_ "GenMsgCycleTime" BO_ 1025 500;
BA_ "GenMsgILSupport" BO_ 803 1;
BA_ "GenMsgNrOfRepetition" BO_ 803 0;
BA_ "GenMsgCycleTime" BO_ 803 20;
BA_ "GenMsgILSupport" BO_ 1120 1;
BA_ "GenMsgNrOfRepetition" BO_ 1120 0;
BA_ "GenMsgCycleTime" BO_ 1120 500;
BA_ "GenMsgILSupport" BO_ 1338 1;
BA_ "GenMsgNrOfRepetition" BO_ 1338 0;
BA_ "GenMsgCycleTime" BO_ 1338 1000;
BA_ "GenMsgILSupport" BO_ 787 1;
BA_ "GenMsgNrOfRepetition" BO_ 787 0;
BA_ "GenMsgCycleTime" BO_ 787 20;
BA_ "GenMsgILSupport" BO_ 1136 1;
BA_ "GenMsgNrOfRepetition" BO_ 1136 0;
BA_ "GenMsgCycleTime" BO_ 1136 20;
BA_ "GenMsgILSupport" BO_ 1141 1;
BA_ "GenMsgNrOfRepetition" BO_ 1141 0;
BA_ "GenMsgCycleTime" BO_ 1141 100;
BA_ "GenMsgILSupport" BO_ 1050 1;
BA_ "GenMsgNrOfRepetition" BO_ 1050 0;
BA_ "GenMsgCycleTime" BO_ 1050 100;
BA_ "GenMsgILSupport" BO_ 1288 1;
BA_ "GenMsgNrOfRepetition" BO_ 1288 0;
BA_ "GenMsgCycleTime" BO_ 1288 500;
BA_ "GenMsgILSupport" BO_ 773 1;
BA_ "GenMsgNrOfRepetition" BO_ 773 0;
BA_ "GenMsgCycleTime" BO_ 773 50;
BA_ "GenMsgILSupport" BO_ 1241 1;
BA_ "GenMsgNrOfRepetition" BO_ 1241 0;
BA_ "GenMsgCycleTime" BO_ 1241 100;
BA_ "GenMsgILSupport" BO_ 632 1;
BA_ "GenMsgNrOfRepetition" BO_ 632 0;
BA_ "GenMsgCycleTime" BO_ 632 50;
BA_ "GenMsgILSupport" BO_ 1202 1;
BA_ "GenMsgNrOfRepetition" BO_ 1202 0;
BA_ "GenMsgCycleTime" BO_ 1202 20;
BA_ "GenMsgILSupport" BO_ 1507 1;
BA_ "GenMsgCycleTime" BO_ 1507 1000;
BA_ "GenMsgCycleTimeFast" BO_ 1507 20;
BA_ "GenMsgILSupport" BO_ 1518 1;
BA_ "GenMsgSendType" BO_ 1518 8;
BA_ "GenMsgCycleTimeFast" BO_ 1518 100;
BA_ "GenMsgILSupport" BO_ 1517 1;
BA_ "GenMsgCycleTimeFast" BO_ 1517 100;
BA_ "GenMsgCycleTime" BO_ 1517 1000;
BA_ "GenMsgILSupport" BO_ 1504 1;
BA_ "GenMsgCycleTime" BO_ 1504 1000;
BA_ "GenMsgCycleTimeFast" BO_ 1504 20;
BA_ "GenMsgILSupport" BO_ 1168 1;
BA_ "GenMsgNrOfRepetition" BO_ 1168 0;
BA_ "GenMsgCycleTime" BO_ 1168 100;
BA_ "GenMsgILSupport" BO_ 1492 1;
BA_ "GenMsgNrOfRepetition" BO_ 1492 0;
BA_ "GenMsgCycleTime" BO_ 1492 100;
BA_ "GenMsgILSupport" BO_ 1476 1;
BA_ "GenMsgCycleTimeFast" BO_ 1476 50;
BA_ "GenMsgCycleTime" BO_ 1476 1000;
BA_ "GenMsgILSupport" BO_ 1535 1;
BA_ "GenMsgCycleTimeFast" BO_ 1535 500;
BA_ "GenMsgCycleTime" BO_ 1535 500;
BA_ "GenMsgILSupport" BO_ 914 1;
BA_ "GenMsgNrOfRepetition" BO_ 914 0;
BA_ "GenMsgCycleTime" BO_ 914 20;
BA_ "GenMsgILSupport" BO_ 1340 1;
BA_ "GenMsgNrOfRepetition" BO_ 1340 0;
BA_ "GenMsgCycleTime" BO_ 1340 1000;
BA_ "GenMsgILSupport" BO_ 1306 1;
BA_ "GenMsgNrOfRepetition" BO_ 1306 0;
BA_ "GenMsgCycleTime" BO_ 1306 100;
BA_ "GenMsgILSupport" BO_ 952 1;
BA_ "GenMsgNrOfRepetition" BO_ 952 0;
BA_ "GenMsgCycleTime" BO_ 952 100;
BA_ "GenMsgILSupport" BO_ 1381 1;
BA_ "GenMsgNrOfRepetition" BO_ 1381 0;
BA_ "GenMsgCycleTime" BO_ 1381 500;
BA_ "GenSigSendType" SG_ 3221225472 SET_Rmirror_UD_Locaton 4;
BA_ "GenSigSendType" SG_ 3221225472 SET_Rmirror_LR_Locaton 4;
BA_ "GenSigSendType" SG_ 3221225472 SET_Lmirror_UD_Locaton 4;
BA_ "GenSigSendType" SG_ 3221225472 SET_Lmirror_LR_Locaton 4;
BA_ "GenSigSendType" SG_ 3221225472 ATCM_AVM 2;
BA_ "GenSigSendType" SG_ 1313 TBOX_3_RemotePhotograph 2;
BA_ "GenSigStartValue" SG_ 1349 IPM1_FLTempSwitchReq 32;
BA_ "GenSigSendType" SG_ 1400 IHU_14_SET_DRlight 2;
BA_ "GenSigSendType" SG_ 1400 IHU_14_MFS_ModeSts 2;
BA_ "GenSigSendType" SG_ 1400 TrafficSts 2;
BA_ "GenSigStartValue" SG_ 1400 TrafficSts 3;
BA_ "GenSigSendType" SG_ 1400 NavDistance 2;
BA_ "GenSigSendType" SG_ 1400 IHU_14_Set_FrontFogLights 2;
BA_ "GenSigSendType" SG_ 1400 SET_Passenger_Welcome_Seat 2;
BA_ "GenSigStartValue" SG_ 1400 NextTrafficSts 3;
BA_ "GenSigSendType" SG_ 1400 NextTrafficSts 2;
BA_ "GenSigSendType" SG_ 1400 IHU_RSeatBeltBuckleSwitch 2;
BA_ "GenSigSendType" SG_ 1400 IHU_sound_options_signal 2;
BA_ "GenSigSendType" SG_ 1400 IHU_welcome_sound_device_switchi 2;
BA_ "SystemSignalLongSymbol" SG_ 1400 IHU_welcome_sound_device_switchi "IHU_welcome_sound_device_switching_signal";
BA_ "GenSigSendType" SG_ 1400 SET_Wiper_Sensitivity 2;
BA_ "GenSigStartValue" SG_ 1400 SET_Wiper_Sensitivity 1;
BA_ "GenSigSendType" SG_ 1400 SET_Tunnel_Lamp 2;
BA_ "GenSigSendType" SG_ 1400 SET_Rearfoglight 2;
BA_ "GenSigSendType" SG_ 1400 SET_Lightcontrol 2;
BA_ "GenSigSendType" SG_ 1297 SET_MRSeat_ZerogravityModeReq 2;
BA_ "GenSigSendType" SG_ 1297 SET_MRSeat_MassageModeReq 2;
BA_ "GenSigSendType" SG_ 1297 SET_MRSeat_MassageVibrationReq 2;
BA_ "GenSigSendType" SG_ 1297 SET_MRSeat_MassageStsReq 2;
BA_ "GenSigSendType" SG_ 1297 SET_MRSeat_HeatVent_BlowSwReq 2;
BA_ "GenSigSendType" SG_ 1297 SET_MLSeat_MassageModeReq 2;
BA_ "GenSigSendType" SG_ 1297 SET_MLSeat_MassageVibrationReq 2;
BA_ "GenSigSendType" SG_ 1297 SET_MLSeat_MassageStsReq 2;
BA_ "GenSigSendType" SG_ 1297 SET_MLSeat_HeatVent_BlowSwReq 2;
BA_ "GenSigSendType" SG_ 1297 SET_MRSeat_LegUDReq 2;
BA_ "GenSigSendType" SG_ 1297 SET_MRSeat_SideslipReq 2;
BA_ "GenSigSendType" SG_ 1297 SET_MRSeat_BackReq 2;
BA_ "GenSigSendType" SG_ 1297 SET_MRSeatReq 2;
BA_ "GenSigSendType" SG_ 1297 SET_MLSeat_BackReq 2;
BA_ "GenSigSendType" SG_ 1297 SET_MLSeatReq 2;
BA_ "SystemSignalLongSymbol" SG_ 1286 PassengerSeat_MassageVibrationSt "PassengerSeat_MassageVibrationSts";
BA_ "GenSigSendType" SG_ 1298 SET_RestArea 2;
BA_ "GenSigSendType" SG_ 1298 SET_PassengerSeat_HeatVent_BlowS 2;
BA_ "SystemSignalLongSymbol" SG_ 1298 SET_PassengerSeat_HeatVent_BlowS "SET_PassengerSeat_HeatVent_BlowSwReq";
BA_ "GenSigSendType" SG_ 1298 SET_DriverSeat_HeatVent_BlowSwRe 2;
BA_ "SystemSignalLongSymbol" SG_ 1298 SET_DriverSeat_HeatVent_BlowSwRe "SET_DriverSeat_HeatVent_BlowSwReq";
BA_ "GenSigSendType" SG_ 1298 SET_PassengerSeat_MassageModeReq 2;
BA_ "GenSigSendType" SG_ 1298 SET_DriverSeat_MassageModeReq 2;
BA_ "GenSigSendType" SG_ 1298 SET_DriverSeat_MassageVibrationR 2;
BA_ "SystemSignalLongSymbol" SG_ 1298 SET_DriverSeat_MassageVibrationR "SET_DriverSeat_MassageVibrationReq";
BA_ "GenSigSendType" SG_ 1298 SET_DriverSeat_MassageStsReq 2;
BA_ "GenSigStartValue" SG_ 1444 Evaporatortemperature 40;
BA_ "GenSigStartValue" SG_ 1296 CurrentTimeDay 1;
BA_ "GenSigStartValue" SG_ 1296 CurrentTimeMonth 1;
BA_ "GenSigStartValue" SG_ 1480 NextTrafficSts 3;
BA_ "GenSigStartValue" SG_ 1480 TrafficSts 3;
BA_ "GenSigStartValue" SG_ 1390 CLM_FreeSwing_State 1;
BA_ "GenSigStartValue" SG_ 1440 IHU_EAO_4_Protrait_Val_Pos 50;
BA_ "GenSigStartValue" SG_ 1440 IHU_EAO_4_LandScap_Val_Pos 70;
BA_ "GenSigStartValue" SG_ 1440 IHU_EAO_3_Protrait_Val_Pos 50;
BA_ "GenSigStartValue" SG_ 1440 IHU_EAO_3_LandScap_Val_Pos 70;
BA_ "GenSigStartValue" SG_ 1440 IHU_EAO_2_Protrait_Val_Pos 50;
BA_ "GenSigStartValue" SG_ 1440 IHU_EAO_2_LandScap_Val_Pos 70;
BA_ "GenSigStartValue" SG_ 1440 IHU_EAO_1_Protrait_Val_Pos 50;
BA_ "GenSigStartValue" SG_ 1440 IHU_EAO_1_LandScap_Val_Pos 70;
BA_ "GenSigStartValue" SG_ 1440 IHU_FreeSwing_State 1;
BA_ "GenSigSendType" SG_ 1416 Ready2GoSwitch 2;
BA_ "GenSigSendType" SG_ 1416 IESSwtSet 2;
BA_ "GenSigSendType" SG_ 1416 IHU_11_TSISwtSet 2;
BA_ "GenSigSendType" SG_ 1416 ELK_Switch 2;
BA_ "GenSigSendType" SG_ 1416 DCLC_Switch 2;
BA_ "GenSigSendType" SG_ 1416 RCW_OnOffSt 2;
BA_ "GenSigSendType" SG_ 1416 RCTB_OnOffSt 2;
BA_ "GenSigSendType" SG_ 1330 IHU_29_DchaSet 2;
BA_ "GenSigStartValue" SG_ 896 EPS_1_EPSModeSts 2;
BA_ "GenSigStartValue" SG_ 896 EPS_1_EPSModeSts_PHEV 2;
BA_ "GenSigStartValue" SG_ 896 EPS_1_AssociWithDriverModeSts 1;
BA_ "GenSigSendType" SG_ 1414 IHU_19_Set_HdrestSpkrMod 2;
BA_ "GenSigSendType" SG_ 1414 REQ_AMPA2BMediaSound 2;
BA_ "GenSigSendType" SG_ 1414 IHU_19_SetIHUAlarm 2;
BA_ "GenSigSendType" SG_ 1414 IHU_19_Set_AMPESEVol 2;
BA_ "GenSigSendType" SG_ 1414 IHU_19_Set_AMPWelVol 2;
BA_ "GenSigSendType" SG_ 1414 IHU_19_Set_AMPBTMediVol 2;
BA_ "GenSigSendType" SG_ 1414 IHU_19_REQ_AMPA2BMediSound 2;
BA_ "GenSigSendType" SG_ 1414 IHU_19_REQ_AMPA2BESESound 2;
BA_ "GenSigSendType" SG_ 1414 REQ_AMPA2BKeyTone 2;
BA_ "GenSigSendType" SG_ 1414 REQ_AMPA2BTTSSound 2;
BA_ "GenSigSendType" SG_ 1414 REQ_AMPA2BVRSound 2;
BA_ "GenSigSendType" SG_ 1414 REQ_AMPA2BNaviSound 2;
BA_ "GenSigSendType" SG_ 1414 Set_AMPMute 2;
BA_ "GenSigSendType" SG_ 1414 Set_AMPSpeedVolume 2;
BA_ "GenSigSendType" SG_ 1414 REQ_AMPA2BPhoneSound 2;
BA_ "GenSigSendType" SG_ 1413 Set_AMPAlarmVolume 2;
BA_ "GenSigSendType" SG_ 1413 Set_AMPLoudness 2;
BA_ "GenSigSendType" SG_ 1413 Set_AMPLiveAcoustics 2;
BA_ "GenSigSendType" SG_ 1413 Set_AMPSoundFieldFader 2;
BA_ "GenSigSendType" SG_ 1413 Set_AMPSoundFieldBalance 2;
BA_ "GenSigSendType" SG_ 1413 Set_AMPSoundEffectTreble 2;
BA_ "GenSigSendType" SG_ 1413 Set_AMPSoundEffectMidrange 2;
BA_ "GenSigSendType" SG_ 1413 Set_AMPSoundEffectBass 2;
BA_ "GenSigSendType" SG_ 1413 Set_AMPSoundEffect 2;
BA_ "GenSigSendType" SG_ 1413 Set_AMPRestoreDefaults 2;
BA_ "GenSigSendType" SG_ 1413 Set_AMPDefaultVolume 2;
BA_ "GenSigSendType" SG_ 1413 Set_AMPSoundFocus 2;
BA_ "GenSigSendType" SG_ 1413 Set_AMPPhoneVolume 2;
BA_ "GenSigSendType" SG_ 1413 Set_AMPMediaVolume 2;
BA_ "GenSigSendType" SG_ 1413 Set_AMPKeyTone 2;
BA_ "GenSigSendType" SG_ 1413 Set_AMPVRVolume 2;
BA_ "GenSigSendType" SG_ 1413 Set_AMPNaviVolume 2;
BA_ "GenSigSendType" SG_ 1114 IHU_APAKeySts 2;
BA_ "GenSigSendType" SG_ 1114 CalibrationReq 2;
BA_ "GenSigSendType" SG_ 1114 TouchEvt 2;
BA_ "GenSigStartValue" SG_ 1114 NaviBtnPressInputValueY 65535;
BA_ "GenSigSendType" SG_ 1114 NaviBtnPressInputValueY 2;
BA_ "GenSigStartValue" SG_ 1114 NaviBtnPressInputValueX 65535;
BA_ "GenSigSendType" SG_ 1114 NaviBtnPressInputValueX 2;
BA_ "GenSigSendType" SG_ 1114 IHUDisplayAVMOff 2;
BA_ "GenSigSendType" SG_ 1114 AVMSwt 2;
BA_ "GenSigSendType" SG_ 1276 IHU_11_HMASwtSet 2;
BA_ "GenSigSendType" SG_ 1276 IHU_11_ELKSwtSet 2;
BA_ "GenSigSendType" SG_ 1276 IHU_11_LDWLDPSnvtySet 2;
BA_ "GenSigSendType" SG_ 1276 IHU_11_LDPSwtSet 2;
BA_ "GenSigSendType" SG_ 1276 IHU_11_WarnModSwtSet 2;
BA_ "GenSigSendType" SG_ 1276 IHU_11_LDWSwtSet 2;
BA_ "GenSigSendType" SG_ 1276 IHU_11_TLISwtSet 2;
BA_ "GenSigSendType" SG_ 1276 IHU_11_TSISwtSet 2;
BA_ "GenSigSendType" SG_ 1276 IHU_11_IESSwtSet 2;
BA_ "GenSigSendType" SG_ 1276 IHU_11_DAISwtSet 2;
BA_ "GenSigSendType" SG_ 1276 IHU_11_SCFSwtSet 2;
BA_ "GenSigSendType" SG_ 1276 IHU_11_SLASwtSet 2;
BA_ "GenSigSendType" SG_ 1276 IHU_11_TJAICAExitTextInfoSwtSet 2;
BA_ "GenSigSendType" SG_ 1276 IHU_11_FCWSnvtySet 2;
BA_ "GenSigSendType" SG_ 1276 IHU_11_FCWSwtSet 2;
BA_ "GenSigSendType" SG_ 1276 IHU_11_AEBSwtSet 2;
BA_ "GenSigSendType" SG_ 1322 IHU_Set_External_Welcome_Light 4;
BA_ "GenSigSendType" SG_ 1322 IHU_All_weather_light_switch 4;
BA_ "GenSigSendType" SG_ 1322 IHU_SET_LampLEDSwitch 4;
BA_ "GenSigStartValue" SG_ 1322 IHU_SET_LampLEDSwitch 2;
BA_ "GenSigSendType" SG_ 1322 SET_FrontWindscreenHeatiReq 4;
BA_ "GenSigSendType" SG_ 1322 SET_RRSeatHeatVentSwReq 4;
BA_ "GenSigSendType" SG_ 1322 SET_LRSeatHeatVentSwReq 4;
BA_ "GenSigStartValue" SG_ 295 YAS_1_LateraAccaleleration 2000;
BA_ "GenSigStartValue" SG_ 1057 CruiseLimitSpeedValue 1;
BA_ "GenSigStartValue" SG_ 1034 HCU_EmPwr 128;
BA_ "GenSigStartValue" SG_ 1183 BMSH_BatteryCurrent 32000;
BA_ "GenSigStartValue" SG_ 1448 BMSH_TempSensor_MinTemp 40;
BA_ "GenSigStartValue" SG_ 1448 BMSH_TempSensor_MaxTemp 40;
BA_ "GenSigStartValue" SG_ 1103 BMSH_LeftChargeTime 1022;
BA_ "GenSigStartValue" SG_ 1083 BMSH_PackPowerRealTime 2000;
BA_ "GenSigSendType" SG_ 2047 Start_Aging 1;
BA_ "GenSigStartValue" SG_ 856 TBOX_TimeToStopChargeMinuteFed 62;
BA_ "GenSigStartValue" SG_ 856 TBOX_TimeToStopChargeHourFed 30;
BA_ "GenSigStartValue" SG_ 856 TBOX_TimeToStartChargeMinuteFed 62;
BA_ "GenSigStartValue" SG_ 856 TBOX_TimeToStartChargeHourFed 30;
BA_ "GenSigStartValue" SG_ 1338 PM2_5_Outdensity 65535;
BA_ "GenSigStartValue" SG_ 1338 PM2_5_Indensity 65535;
BA_ "GenSigStartValue" SG_ 1136 YAS_2_LongitudinalAcceleration 2000;
BA_ "GenSigStartValue" SG_ 1141 RAD2_LHSFRadarSensorDistance 126;
BA_ "GenSigStartValue" SG_ 1141 RAD2_RHSFRadarSensorDistance 126;
BA_ "GenSigStartValue" SG_ 1141 RAD2_LHSRRadarSensorDistance 126;
BA_ "GenSigStartValue" SG_ 1141 RAD2_RHSRRadarSensorDistance 126;
BA_ "GenSigSendType" SG_ 1507 DHM_1_Doorkonb_time_freeback 4;
BA_ "GenSigSendType" SG_ 1518 CEM_DHM_handlelockswitchfeedback 2;
BA_ "GenSigSendType" SG_ 1518 CEM_DHM_handleunlockswitchfeedba 2;
BA_ "SystemSignalLongSymbol" SG_ 1518 CEM_DHM_handleunlockswitchfeedba "CEM_DHM_handleunlockswitchfeedback";
BA_ "GenSigSendType" SG_ 1517 CEM_SRF_lockingreason 4;
BA_ "GenSigSendType" SG_ 1517 CEM_RR_window_up_Reason_feedback 4;
BA_ "GenSigSendType" SG_ 1517 CEM_LR_window_up_Reason_feedback 4;
BA_ "GenSigSendType" SG_ 1517 CEM_Passenger_window_up_Reason_f 4;
BA_ "SystemSignalLongSymbol" SG_ 1517 CEM_Passenger_window_up_Reason_f "CEM_Passenger_window_up_Reason_feedback";
BA_ "GenSigSendType" SG_ 1517 CEM_Driver_window_up_Reason_feed 4;
BA_ "SystemSignalLongSymbol" SG_ 1517 CEM_Driver_window_up_Reason_feed "CEM_Driver_window_up_Reason_feedback";
BA_ "GenSigSendType" SG_ 1504 CEM_SRFclosingConditions 4;
BA_ "GenSigSendType" SG_ 1504 CEM_Abat_VentCMDSts 4;
BA_ "GenSigSendType" SG_ 1504 CEM_PSRFCMDSts 4;
BA_ "SystemSignalLongSymbol" SG_ 1168 CEM_ALM_1_SceneMode_ControlSwitc "CEM_ALM_1_SceneMode_ControlSwitch";
BA_ "GenSigStartValue" SG_ 1168 CEM_ALM_1_STAT_WelcomeWaterLamp 1;
BA_ "SystemSignalLongSymbol" SG_ 1168 CEM_ALM_1_STAT_AssociatedWithDri "CEM_ALM_1_STAT_AssociatedWithDriverMode";
BA_ "GenSigStartValue" SG_ 1168 CEM_ALM_1_STAT_StaticEffect 7;
BA_ "SystemSignalLongSymbol" SG_ 1492 CEM_DriverSeat_FrontendUD_Locato "CEM_DriverSeat_FrontendUD_Locaton";
BA_ "GenSigStartValue" SG_ 1492 CEM_Rmirror_UD_Locaton 1;
BA_ "GenSigStartValue" SG_ 1492 CEM_Rmirror_LR_Locaton 1;
BA_ "GenSigStartValue" SG_ 1492 CEM_Lmirror_UD_Locaton 1;
BA_ "GenSigStartValue" SG_ 1492 CEM_Lmirror_LR_Locaton 1;
BA_ "GenSigSendType" SG_ 1476 BCM_AutoWipingInhibit 4;
BA_ "GenSigSendType" SG_ 1476 CEM_Psngrseat_Location 4;
BA_ "GenSigSendType" SG_ 1476 CEM_PassengerSeat_LegUDSts 4;
BA_ "GenSigSendType" SG_ 1476 CEM_PassengerSeat_BackFRSts 4;
BA_ "GenSigSendType" SG_ 1476 CEM_PassengerSeat_FRSts 4;
BA_ "GenSigSendType" SG_ 1476 CEM_massagemodeSts 4;
BA_ "GenSigSendType" SG_ 1476 CEM_passageVibrationSts 4;
BA_ "GenSigSendType" SG_ 1476 CEM_Passenger_massageSts 4;
BA_ "GenSigSendType" SG_ 1476 CEM_DriverLumbart_FR_Locaton 4;
BA_ "GenSigSendType" SG_ 1476 CEM_Mirror_Driverseat_Location 4;
BA_ "GenSigSendType" SG_ 1476 CEM_UnderVoltageSts 4;
BA_ "GenSigSendType" SG_ 1476 CEM_RearWiper_SwitchSts 4;
BA_ "GenSigSendType" SG_ 1476 BCM_Wiper_MaintenanceSts 4;
BA_ "GenSigSendType" SG_ 1476 CEM_Mirror_Fold_SwitchSts 4;
BA_ "GenSigSendType" SG_ 1476 CEM_IPM__FRSeatHeatVentSwSts 4;
BA_ "GenSigSendType" SG_ 1476 CEM_IPM_FLSeatHeatVentSwSts 4;
BA_ "GenSigSendType" SG_ 1476 CEM_DriverLumbart_UDSts 4;
BA_ "GenSigSendType" SG_ 1476 CEM_DriverLumbart_FRSts 4;
BA_ "GenSigSendType" SG_ 1476 CEM_DriverSeat_RearendUDSts 4;
BA_ "GenSigSendType" SG_ 1476 CEM_DriverSeat_FrontendUDSts 4;
BA_ "GenSigSendType" SG_ 1476 CEM_DriverSeat_FRSts 4;
BA_ "GenSigSendType" SG_ 1476 CEM_DriverSeat_BackFRSts 4;
BA_ "GenSigSendType" SG_ 1476 CEM_MirrorFlip_CFGSts 4;
BA_ "GenSigSendType" SG_ 1476 CEM_RightMirrorCtrlSts 4;
BA_ "GenSigSendType" SG_ 1476 CEM_LeftMirrorCtrlSts 4;
BA_ "GenSigSendType" SG_ 1476 CEM_RHRdoor_buttonsts 4;
BA_ "GenSigSendType" SG_ 1476 CEM_LHRdoor_buttonsts 4;
BA_ "GenSigSendType" SG_ 1476 CEM_PsngrDoor_buttonsts 4;
BA_ "GenSigSendType" SG_ 1476 CEM_Smart_HighBeamSts 4;
BA_ "GenSigSendType" SG_ 1476 CEM_HighBeam_AdjustSts 4;
BA_ "SystemSignalLongSymbol" SG_ 1535 CEM_DHM_Driver_unlockmode_feedba "CEM_DHM_Driver_unlockmode_feedback";
BA_ "SystemSignalLongSymbol" SG_ 914 CEM_2_HazardLampForUrgencyBrakeS "CEM_2_HazardLampForUrgencyBrakeSts";
BA_ "SystemSignalLongSymbol" SG_ 914 CEM_2_Laser_High_Beam_Assist_Sta "CEM_2_Laser_High_Beam_Assist_Status";
BA_ "GenSigStartValue" SG_ 914 BCM_4_FollowMeHomeTimeSts 1;
BA_REL_ "GenSigTimeoutTime" BU_SG_REL_ IHU SG_ 1262 LightShowSts 4000;
BA_REL_ "GenSigTimeoutTime" BU_SG_REL_ IHU SG_ 295 YAS_1_LateraAccaleleration 400;
BA_REL_ "GenSigTimeoutTime" BU_SG_REL_ IHU SG_ 1111 AVAS_FunctionSts 2000;
BA_REL_ "GenSigTimeoutTime" BU_SG_REL_ IHU SG_ 1057 LimitSpeedSts 2000;
BA_REL_ "GenSigTimeoutTime" BU_SG_REL_ IHU SG_ 1057 CruiseLimitSpeedValue 2000;
BA_REL_ "GenSigTimeoutTime" BU_SG_REL_ IHU SG_ 1046 HCU_3_G_SumElecCns 2000;
BA_REL_ "GenSigTimeoutTime" BU_SG_REL_ IHU SG_ 1046 HCU_3_G_SumFuCns 2000;
BA_REL_ "GenSigTimeoutTime" BU_SG_REL_ IHU SG_ 1046 HCU_HundECHis 2000;
BA_REL_ "GenSigTimeoutTime" BU_SG_REL_ IHU SG_ 1046 HCU_HundECAver 2000;
BA_REL_ "GenSigTimeoutTime" BU_SG_REL_ IHU SG_ 1142 HCU_4_G_SumEgyCns 2000;
BA_REL_ "GenSigTimeoutTime" BU_SG_REL_ IHU SG_ 1142 HCU_4_G_AvgEnergyCns 2000;
BA_REL_ "GenSigTimeoutTime" BU_SG_REL_ IHU SG_ 1142 HCU_4_G_AvgElecCns 2000;
BA_REL_ "GenSigTimeoutTime" BU_SG_REL_ IHU SG_ 1142 HCU_4_G_AvgFuCns 2000;
BA_REL_ "GenSigTimeoutTime" BU_SG_REL_ IHU SG_ 1142 FuelTankLidSts 2000;
BA_REL_ "GenSigTimeoutTime" BU_SG_REL_ IHU SG_ 1044 HCU_2_G_ChrgnFctMemSt 2000;
BA_REL_ "GenSigTimeoutTime" BU_SG_REL_ IHU SG_ 1044 HCU_RegenerateLevel 2000;
BA_REL_ "GenSigTimeoutTime" BU_SG_REL_ IHU SG_ 1044 HCU_SetSOCFed 2000;
BA_REL_ "GenSigTimeoutTime" BU_SG_REL_ IHU SG_ 1044 HCU_SocManageFed 2000;
BA_REL_ "GenSigTimeoutTime" BU_SG_REL_ IHU SG_ 1044 HCU_RangeAval 2000;
BA_REL_ "GenSigTimeoutTime" BU_SG_REL_ IHU SG_ 1044 HCU_EnergyFlow 2000;
BA_REL_ "GenSigTimeoutTime" BU_SG_REL_ IHU SG_ 1034 HCU_PTReady 2000;
BA_REL_ "GenSigTimeoutTime" BU_SG_REL_ IHU SG_ 1034 HCU_PowertrainFault 2000;
BA_REL_ "GenSigTimeoutTime" BU_SG_REL_ IHU SG_ 1034 HCU_PowerModeFed 2000;
BA_REL_ "GenSigTimeoutTime" BU_SG_REL_ IHU SG_ 1183 BMSH_PackChargingThermalSt 2000;
BA_REL_ "GenSigTimeoutTime" BU_SG_REL_ IHU SG_ 1183 BMSH_BattVolt 2000;
BA_REL_ "GenSigTimeoutTime" BU_SG_REL_ IHU SG_ 1183 BMSH_BatteryCurrent 2000;
BA_REL_ "GenSigTimeoutTime" BU_SG_REL_ IHU SG_ 1472 BMSH_SingleDisChargeEnergy 4000;
BA_REL_ "GenSigTimeoutTime" BU_SG_REL_ IHU SG_ 1472 BMSH_SingleChargeEnergy 4000;
BA_REL_ "GenSigTimeoutTime" BU_SG_REL_ IHU SG_ 1449 BMSH_CellVoltMin 4000;
BA_REL_ "GenSigTimeoutTime" BU_SG_REL_ IHU SG_ 1449 BMSH_CellVoltMax 4000;
BA_REL_ "GenSigTimeoutTime" BU_SG_REL_ IHU SG_ 1448 BMSH_TempSensor_MinTemp 4000;
BA_REL_ "GenSigTimeoutTime" BU_SG_REL_ IHU SG_ 1448 BMSH_TempSensor_MaxTemp 4000;
BA_REL_ "GenSigTimeoutTime" BU_SG_REL_ IHU SG_ 1436 BMSH_InsulationResis 4000;
BA_REL_ "GenSigTimeoutTime" BU_SG_REL_ IHU SG_ 1103 BMS_8_CC2Sts 2000;
BA_REL_ "GenSigTimeoutTime" BU_SG_REL_ IHU SG_ 1103 BMSH_SOH 2000;
BA_REL_ "GenSigTimeoutTime" BU_SG_REL_ IHU SG_ 1103 BMS_8_PackDCChargingSt 2000;
BA_REL_ "GenSigTimeoutTime" BU_SG_REL_ IHU SG_ 1103 BMSH_LeftChargeTime 2000;
BA_REL_ "GenSigTimeoutTime" BU_SG_REL_ IHU SG_ 1083 BMSH_PackPowerRealTime 2000;
BA_REL_ "GenSigTimeoutTime" BU_SG_REL_ IHU SG_ 1083 BMSH_PackRemainEnergy 2000;
BA_REL_ "GenSigTimeoutTime" BU_SG_REL_ IHU SG_ 1083 BMSH_SOCDisp 2000;
BA_REL_ "GenSigTimeoutTime" BU_SG_REL_ IHU SG_ 856 TBOX_TimeToStopChargeMinuteFed 1000;
BA_REL_ "GenSigTimeoutTime" BU_SG_REL_ IHU SG_ 856 TBOX_TimeToStopChargeHourFed 1000;
BA_REL_ "GenSigTimeoutTime" BU_SG_REL_ IHU SG_ 856 TBOX_TimeToStartChargeMinuteFed 1000;
BA_REL_ "GenSigTimeoutTime" BU_SG_REL_ IHU SG_ 856 TBOX_TimeToStartChargeHourFed 1000;
BA_REL_ "GenSigTimeoutTime" BU_SG_REL_ IHU SG_ 856 TBOX_ChargeModeSts 1000;
BA_REL_ "GenSigTimeoutTime" BU_SG_REL_ IHU SG_ 1025 Welcome_OutsoundSts 4000;
BA_REL_ "GenSigTimeoutTime" BU_SG_REL_ IHU SG_ 1025 Person_RemindSts 4000;
BA_REL_ "GenSigTimeoutTime" BU_SG_REL_ IHU SG_ 1025 Welcome_Outsound_SwitchSts 4000;
BA_REL_ "GenSigTimeoutTime" BU_SG_REL_ IHU SG_ 803 MFS3_AVM 200;
BA_REL_ "GenSigTimeoutTime" BU_SG_REL_ IHU SG_ 803 MFS3_ICM_Right 200;
BA_REL_ "GenSigTimeoutTime" BU_SG_REL_ IHU SG_ 803 MFS3_ICM_Left 200;
BA_REL_ "GenSigTimeoutTime" BU_SG_REL_ IHU SG_ 803 MFS3_ICM_Down_Zoom_Out 200;
BA_REL_ "GenSigTimeoutTime" BU_SG_REL_ IHU SG_ 803 MFS3_ICM_UP_Zoom_In 200;
BA_REL_ "GenSigTimeoutTime" BU_SG_REL_ IHU SG_ 803 MFS3_Instrument_SetReturn 200;
BA_REL_ "GenSigTimeoutTime" BU_SG_REL_ IHU SG_ 1120 Enter_super_fast_charge 4000;
BA_REL_ "GenSigTimeoutTime" BU_SG_REL_ IHU SG_ 1120 WCM_Electricity_decimal 4000;
BA_REL_ "GenSigTimeoutTime" BU_SG_REL_ IHU SG_ 1120 WCM_Electricity_integer 4000;
BA_REL_ "GenSigTimeoutTime" BU_SG_REL_ IHU SG_ 1120 WCM_PhoneDetectionStatus 4000;
BA_REL_ "GenSigTimeoutTime" BU_SG_REL_ IHU SG_ 1120 WCM_WirelessChargingStatus 4000;
BA_REL_ "GenSigTimeoutTime" BU_SG_REL_ IHU SG_ 1120 WCM_WirelessChargingSetStatus 4000;
BA_REL_ "GenSigTimeoutTime" BU_SG_REL_ IHU SG_ 1338 PM2_5_ErrSts 4000;
BA_REL_ "GenSigTimeoutTime" BU_SG_REL_ IHU SG_ 1338 PM2_5_Sts 4000;
BA_REL_ "GenSigTimeoutTime" BU_SG_REL_ IHU SG_ 1338 PM2_5_AirIOutQLevel 4000;
BA_REL_ "GenSigTimeoutTime" BU_SG_REL_ IHU SG_ 1338 PM2_5_AirInQLevel 4000;
BA_REL_ "GenSigTimeoutTime" BU_SG_REL_ IHU SG_ 1338 PM2_5_Outdensity 4000;
BA_REL_ "GenSigTimeoutTime" BU_SG_REL_ IHU SG_ 1338 PM2_5_Indensity 4000;
BA_REL_ "GenSigTimeoutTime" BU_SG_REL_ IHU SG_ 787 ABS_ESP_3_AVHSts 400;
BA_REL_ "GenSigTimeoutTime" BU_SG_REL_ IHU SG_ 1136 YAS_2_LongitudinalAcceleration 400;
BA_REL_ "GenSigTimeoutTime" BU_SG_REL_ IHU SG_ 1141 RAD2_Radar_FunctionModel_Status 2000;
BA_REL_ "GenSigTimeoutTime" BU_SG_REL_ IHU SG_ 1141 RAD2_LHSFRadarSensorDistance 2000;
BA_REL_ "GenSigTimeoutTime" BU_SG_REL_ IHU SG_ 1141 RAD2_RHSFRadarSensorDistance 2000;
BA_REL_ "GenSigTimeoutTime" BU_SG_REL_ IHU SG_ 1141 RAD2_LHSRRadarSensorDistance 2000;
BA_REL_ "GenSigTimeoutTime" BU_SG_REL_ IHU SG_ 1141 RAD2_RHSRRadarSensorDistance 2000;
BA_REL_ "GenSigTimeoutTime" BU_SG_REL_ IHU SG_ 1050 AVM_APA_SystemSts 2000;
BA_REL_ "GenSigTimeoutTime" BU_SG_REL_ IHU SG_ 1050 APA_Parking_Space_Search_Sts 2000;
BA_REL_ "GenSigTimeoutTime" BU_SG_REL_ IHU SG_ 1050 AVM_FactoryMode 2000;
BA_REL_ "GenSigTimeoutTime" BU_SG_REL_ IHU SG_ 1050 APA_3AVMFeedbackSts_RemoteMode 2000;
BA_REL_ "GenSigTimeoutTime" BU_SG_REL_ IHU SG_ 1050 AVMDisplaySts 2000;
BA_REL_ "GenSigTimeoutTime" BU_SG_REL_ IHU SG_ 1288 APA_2_AVMStatusFault 4000;
BA_REL_ "GenSigTimeoutTime" BU_SG_REL_ IHU SG_ 1288 APA_2_AVMFaultStatusCameraRight 4000;
BA_REL_ "GenSigTimeoutTime" BU_SG_REL_ IHU SG_ 1288 APA_2_AVMFaultStatusCameraRear 4000;
BA_REL_ "GenSigTimeoutTime" BU_SG_REL_ IHU SG_ 1288 APA_2_AVMFaultStatusCameraLeft 4000;
BA_REL_ "GenSigTimeoutTime" BU_SG_REL_ IHU SG_ 1288 APA_2_AVMFaultStatusCameraFront 4000;
BA_REL_ "GenSigTimeoutTime" BU_SG_REL_ IHU SG_ 773 FRM_3_CRC 1000;
BA_REL_ "GenSigTimeoutTime" BU_SG_REL_ IHU SG_ 773 FRM_3_MessageCounter 1000;
BA_REL_ "GenSigTimeoutTime" BU_SG_REL_ IHU SG_ 773 FRM_3_DistanceWarning_On_Off_Sts 1000;
BA_REL_ "GenSigTimeoutTime" BU_SG_REL_ IHU SG_ 773 FRM_3_AEB_ON_OFF_Sts 1000;
BA_REL_ "GenSigTimeoutTime" BU_SG_REL_ IHU SG_ 773 FRM_3_FCW_OPTION_Sts 1000;
BA_REL_ "GenSigTimeoutTime" BU_SG_REL_ IHU SG_ 773 FRM_3_FCW_ON_OFF_Sts 1000;
BA_REL_ "GenSigTimeoutTime" BU_SG_REL_ IHU SG_ 773 FRM_3_TimeGapLastSet_DVD 1000;
BA_REL_ "GenSigTimeoutTime" BU_SG_REL_ IHU SG_ 773 FRM_3_FCW_PreWarning 1000;
BA_REL_ "GenSigTimeoutTime" BU_SG_REL_ IHU SG_ 773 FRM_3_DistanceWarning 1000;
BA_REL_ "GenSigTimeoutTime" BU_SG_REL_ IHU SG_ 773 FRM_3_AEBMode 1000;
BA_REL_ "GenSigTimeoutTime" BU_SG_REL_ IHU SG_ 773 FRM_3_FCWMode 1000;
BA_REL_ "GenSigTimeoutTime" BU_SG_REL_ IHU SG_ 773 FRM_3_Obiect_Dx 1000;
BA_REL_ "GenSigTimeoutTime" BU_SG_REL_ IHU SG_ 773 FRM_3_ACCMode 1000;
BA_REL_ "GenSigTimeoutTime" BU_SG_REL_ IHU SG_ 773 FRM_3_TimeGapSet_ICM 1000;
BA_REL_ "GenSigTimeoutTime" BU_SG_REL_ IHU SG_ 773 FRM_3_TimeGapSet_DVD 1000;
BA_REL_ "GenSigTimeoutTime" BU_SG_REL_ IHU SG_ 773 FRM_3_TakeOverReq 1000;
BA_REL_ "GenSigTimeoutTime" BU_SG_REL_ IHU SG_ 773 FRM_3_Textinfo 1000;
BA_REL_ "GenSigTimeoutTime" BU_SG_REL_ IHU SG_ 773 FRM_3_FrontObject_Type 1000;
BA_REL_ "GenSigTimeoutTime" BU_SG_REL_ IHU SG_ 773 FRM_3_ObjValid 1000;
BA_REL_ "GenSigTimeoutTime" BU_SG_REL_ IHU SG_ 773 FRM_3_DxTarObj 1000;
BA_REL_ "GenSigTimeoutTime" BU_SG_REL_ IHU SG_ 773 FRM_3_VSetDis 1000;
BA_REL_ "GenSigTimeoutTime" BU_SG_REL_ IHU SG_ 1241 FuelTankLidSystemFailureSts 2000;
BA_REL_ "GenSigTimeoutTime" BU_SG_REL_ IHU SG_ 1241 FuelTankPressureConditionReached 2000;
BA_REL_ "GenSigTimeoutTime" BU_SG_REL_ IHU SG_ 632 EMS_4_IntakeAirPressure 1000;
BA_REL_ "GenSigTimeoutTime" BU_SG_REL_ IHU SG_ 632 EMS_4_EngineSts 1000;
BA_REL_ "GenSigTimeoutTime" BU_SG_REL_ IHU SG_ 1202 GSM_STAT_ShifterLeverFault 400;
BA_REL_ "GenSigTimeoutTime" BU_SG_REL_ IHU SG_ 1202 GSM_ALIVE_GSM_1 400;
BA_REL_ "GenSigTimeoutTime" BU_SG_REL_ IHU SG_ 1202 GSM_STAT_ParkButton 400;
BA_REL_ "GenSigTimeoutTime" BU_SG_REL_ IHU SG_ 1202 GSM_GearShiftPosInverse 400;
BA_REL_ "GenSigTimeoutTime" BU_SG_REL_ IHU SG_ 1202 GSM_CHKSM_GSM_1 400;
BA_REL_ "GenSigTimeoutTime" BU_SG_REL_ IHU SG_ 1202 ACC_Cruise_Control 400;
BA_REL_ "GenSigTimeoutTime" BU_SG_REL_ IHU SG_ 1202 GSM_GearShiftPos 400;
BA_REL_ "GenSigTimeoutTime" BU_SG_REL_ IHU SG_ 1507 DHM_1_Doorkonb_time_freeback 4000;
BA_REL_ "GenSigTimeoutTime" BU_SG_REL_ IHU SG_ 1517 CEM_SRF_lockingreason 4000;
BA_REL_ "GenSigTimeoutTime" BU_SG_REL_ IHU SG_ 1517 CEM_RR_window_up_Reason_feedback 4000;
BA_REL_ "GenSigTimeoutTime" BU_SG_REL_ IHU SG_ 1517 CEM_LR_window_up_Reason_feedback 4000;
BA_REL_ "GenSigTimeoutTime" BU_SG_REL_ IHU SG_ 1517 CEM_Passenger_window_up_Reason_f 4000;
BA_REL_ "GenSigTimeoutTime" BU_SG_REL_ IHU SG_ 1517 CEM_Driver_window_up_Reason_feed 4000;
BA_REL_ "GenSigTimeoutTime" BU_SG_REL_ IHU SG_ 1504 CEM_SRFclosingConditions 4000;
BA_REL_ "GenSigTimeoutTime" BU_SG_REL_ IHU SG_ 1504 CEM_Abat_VentCMDSts 4000;
BA_REL_ "GenSigTimeoutTime" BU_SG_REL_ IHU SG_ 1504 CEM_PSRFCMDSts 4000;
BA_REL_ "GenSigTimeoutTime" BU_SG_REL_ IHU SG_ 1168 CEM_ALM_1_SceneMode_ControlSwitc 2000;
BA_REL_ "GenSigTimeoutTime" BU_SG_REL_ IHU SG_ 1168 CEM_ALM_1_DeletePeronalSet_FB 2000;
BA_REL_ "GenSigTimeoutTime" BU_SG_REL_ IHU SG_ 1168 CEM_ALM_1_PersonalBeamEn 2000;
BA_REL_ "GenSigTimeoutTime" BU_SG_REL_ IHU SG_ 1168 CEM_ALM_1_PersonalSeatEn 2000;
BA_REL_ "GenSigTimeoutTime" BU_SG_REL_ IHU SG_ 1168 CEM_ALM_1_Seat_Set_Status 2000;
BA_REL_ "GenSigTimeoutTime" BU_SG_REL_ IHU SG_ 1168 CEM_ALM_1_Seat_Set_Pop_Up 2000;
BA_REL_ "GenSigTimeoutTime" BU_SG_REL_ IHU SG_ 1168 CEM_ALM_1_Wash_Car_Status 2000;
BA_REL_ "GenSigTimeoutTime" BU_SG_REL_ IHU SG_ 1168 CEM_ALM_1_PersonalSetSts 2000;
BA_REL_ "GenSigTimeoutTime" BU_SG_REL_ IHU SG_ 1168 CEM_ALM_1_STAT_WelcomeWaterLamp 2000;
BA_REL_ "GenSigTimeoutTime" BU_SG_REL_ IHU SG_ 1168 CEM_ALM_1_STAT_AssociatedWithDri 2000;
BA_REL_ "GenSigTimeoutTime" BU_SG_REL_ IHU SG_ 1168 CEM_ALM_1_STAT_Music 2000;
BA_REL_ "GenSigTimeoutTime" BU_SG_REL_ IHU SG_ 1168 CEM_ALM_1_STAT_Apiluminance 2000;
BA_REL_ "GenSigTimeoutTime" BU_SG_REL_ IHU SG_ 1168 CEM_ALM_1_STAT_Static_Colour 2000;
BA_REL_ "GenSigTimeoutTime" BU_SG_REL_ IHU SG_ 1168 CEM_ALM_1_STAT_StaticEffect 2000;
BA_REL_ "GenSigTimeoutTime" BU_SG_REL_ IHU SG_ 1168 CEM_ALM_1_STAT_ControlSwitch 2000;
BA_REL_ "GenSigTimeoutTime" BU_SG_REL_ IHU SG_ 1168 CEM_ALM_1_STAT_DMSMonitoring 2000;
BA_REL_ "GenSigTimeoutTime" BU_SG_REL_ IHU SG_ 1168 CEM_ALM_1_STAT_PM2_5Monitoring 2000;
BA_REL_ "GenSigTimeoutTime" BU_SG_REL_ IHU SG_ 1168 CEM_ALM_1_STAT_DriveApiluminance 2000;
BA_REL_ "GenSigTimeoutTime" BU_SG_REL_ IHU SG_ 1168 CEM_ALM_1_STAT_64Colour 2000;
BA_REL_ "GenSigTimeoutTime" BU_SG_REL_ IHU SG_ 1492 CEM_DriverLumbart_UD_Locaton 2000;
BA_REL_ "GenSigTimeoutTime" BU_SG_REL_ IHU SG_ 1492 CEM_PassengerSeat_LegUD_Locaton 2000;
BA_REL_ "GenSigTimeoutTime" BU_SG_REL_ IHU SG_ 1492 CEM_PassengerSeat_FR_Locaton 2000;
BA_REL_ "GenSigTimeoutTime" BU_SG_REL_ IHU SG_ 1492 CEM_PassengerSeat_BackFR_Locaton 2000;
BA_REL_ "GenSigTimeoutTime" BU_SG_REL_ IHU SG_ 1492 CEM_DriverSeat_RearendUD_Locaton 2000;
BA_REL_ "GenSigTimeoutTime" BU_SG_REL_ IHU SG_ 1492 CEM_DriverSeat_FrontendUD_Locato 2000;
BA_REL_ "GenSigTimeoutTime" BU_SG_REL_ IHU SG_ 1492 CEM_DriverSeat_FR_Locaton 2000;
BA_REL_ "GenSigTimeoutTime" BU_SG_REL_ IHU SG_ 1492 CEM_DriverSeat_BackFR_Locaton 2000;
BA_REL_ "GenSigTimeoutTime" BU_SG_REL_ IHU SG_ 1492 CEM_Rmirror_UD_Locaton 2000;
BA_REL_ "GenSigTimeoutTime" BU_SG_REL_ IHU SG_ 1492 CEM_Rmirror_LR_Locaton 2000;
BA_REL_ "GenSigTimeoutTime" BU_SG_REL_ IHU SG_ 1492 CEM_Lmirror_UD_Locaton 2000;
BA_REL_ "GenSigTimeoutTime" BU_SG_REL_ IHU SG_ 1492 CEM_Lmirror_LR_Locaton 2000;
BA_REL_ "GenSigTimeoutTime" BU_SG_REL_ IHU SG_ 1476 CEM_massagemodeSts 4000;
BA_REL_ "GenSigTimeoutTime" BU_SG_REL_ IHU SG_ 1476 CEM_passageVibrationSts 4000;
BA_REL_ "GenSigTimeoutTime" BU_SG_REL_ IHU SG_ 1476 CEM_Passenger_massageSts 4000;
BA_REL_ "GenSigTimeoutTime" BU_SG_REL_ IHU SG_ 1476 CEM_DriverLumbart_FR_Locaton 4000;
BA_REL_ "GenSigTimeoutTime" BU_SG_REL_ IHU SG_ 1476 CEM_Mirror_Driverseat_Location 4000;
BA_REL_ "GenSigTimeoutTime" BU_SG_REL_ IHU SG_ 1476 CEM_UnderVoltageSts 4000;
BA_REL_ "GenSigTimeoutTime" BU_SG_REL_ IHU SG_ 1476 CEM_RearWiper_SwitchSts 4000;
BA_REL_ "GenSigTimeoutTime" BU_SG_REL_ IHU SG_ 1476 BCM_Wiper_MaintenanceSts 4000;
BA_REL_ "GenSigTimeoutTime" BU_SG_REL_ IHU SG_ 1476 CEM_Mirror_Fold_SwitchSts 4000;
BA_REL_ "GenSigTimeoutTime" BU_SG_REL_ IHU SG_ 1476 CEM_IPM__FRSeatHeatVentSwSts 4000;
BA_REL_ "GenSigTimeoutTime" BU_SG_REL_ IHU SG_ 1476 CEM_IPM_FLSeatHeatVentSwSts 4000;
BA_REL_ "GenSigTimeoutTime" BU_SG_REL_ IHU SG_ 1476 CEM_DriverLumbart_UDSts 4000;
BA_REL_ "GenSigTimeoutTime" BU_SG_REL_ IHU SG_ 1476 CEM_DriverLumbart_FRSts 4000;
BA_REL_ "GenSigTimeoutTime" BU_SG_REL_ IHU SG_ 1476 CEM_DriverSeat_RearendUDSts 4000;
BA_REL_ "GenSigTimeoutTime" BU_SG_REL_ IHU SG_ 1476 CEM_DriverSeat_FrontendUDSts 4000;
BA_REL_ "GenSigTimeoutTime" BU_SG_REL_ IHU SG_ 1476 CEM_DriverSeat_FRSts 4000;
BA_REL_ "GenSigTimeoutTime" BU_SG_REL_ IHU SG_ 1476 CEM_DriverSeat_BackFRSts 4000;
BA_REL_ "GenSigTimeoutTime" BU_SG_REL_ IHU SG_ 1476 CEM_MirrorFlip_CFGSts 4000;
BA_REL_ "GenSigTimeoutTime" BU_SG_REL_ IHU SG_ 1476 CEM_RightMirrorCtrlSts 4000;
BA_REL_ "GenSigTimeoutTime" BU_SG_REL_ IHU SG_ 1476 CEM_LeftMirrorCtrlSts 4000;
BA_REL_ "GenSigTimeoutTime" BU_SG_REL_ IHU SG_ 1476 CEM_RHRdoor_buttonsts 4000;
BA_REL_ "GenSigTimeoutTime" BU_SG_REL_ IHU SG_ 1476 CEM_LHRdoor_buttonsts 4000;
BA_REL_ "GenSigTimeoutTime" BU_SG_REL_ IHU SG_ 1476 CEM_PsngrDoor_buttonsts 4000;
BA_REL_ "GenSigTimeoutTime" BU_SG_REL_ IHU SG_ 1476 CEM_Smart_HighBeamSts 4000;
BA_REL_ "GenSigTimeoutTime" BU_SG_REL_ IHU SG_ 1476 CEM_HighBeam_AdjustSts 4000;
BA_REL_ "GenSigTimeoutTime" BU_SG_REL_ IHU SG_ 1535 CEM_DHM_Doorkonbmode_feedback 4000;
BA_REL_ "GenSigTimeoutTime" BU_SG_REL_ IHU SG_ 1535 CEM_DHM_Driver_unlockmode_feedba 4000;
BA_REL_ "GenSigTimeoutTime" BU_SG_REL_ IHU SG_ 1535 CEM_UVC_LuminanceBf 4000;
BA_REL_ "GenSigTimeoutTime" BU_SG_REL_ IHU SG_ 1535 CEM_UVC_WorkingBf 4000;
BA_REL_ "GenSigTimeoutTime" BU_SG_REL_ IHU SG_ 1535 CEM_3_Welcome_Seat_Sts 4000;
BA_REL_ "GenSigTimeoutTime" BU_SG_REL_ IHU SG_ 1535 CEM_IPM_3_ACMAXReq_Sts 4000;
BA_REL_ "GenSigTimeoutTime" BU_SG_REL_ IHU SG_ 1535 CEM_3_PM25DisplayToggle_Sts 4000;
BA_REL_ "GenSigTimeoutTime" BU_SG_REL_ IHU SG_ 1535 CEM_3_DWM_Sts_Msg 4000;
BA_REL_ "GenSigTimeoutTime" BU_SG_REL_ IHU SG_ 1535 CEM_3_EngineControlSts 4000;
BA_REL_ "GenSigTimeoutTime" BU_SG_REL_ IHU SG_ 914 BCM_4_AlarmMode 400;
BA_REL_ "GenSigTimeoutTime" BU_SG_REL_ IHU SG_ 914 CEM_2_RemoteTrunkOnlySts 400;
BA_REL_ "GenSigTimeoutTime" BU_SG_REL_ IHU SG_ 914 BCM_4_AutoLockSts 400;
BA_REL_ "GenSigTimeoutTime" BU_SG_REL_ IHU SG_ 914 CEM_2RearDefrosts 400;
BA_REL_ "GenSigTimeoutTime" BU_SG_REL_ IHU SG_ 914 CEM_2_HazardLampForUrgencyBrakeS 400;
BA_REL_ "GenSigTimeoutTime" BU_SG_REL_ IHU SG_ 914 CEM_2_Mirror_FlipSts 400;
BA_REL_ "GenSigTimeoutTime" BU_SG_REL_ IHU SG_ 914 BCM_4_RemoteLockFeedbackSts 400;
BA_REL_ "GenSigTimeoutTime" BU_SG_REL_ IHU SG_ 914 BCM_4_AutoUnlockSts 400;
BA_REL_ "GenSigTimeoutTime" BU_SG_REL_ IHU SG_ 914 CEM_2_WiperSts 400;
BA_REL_ "GenSigTimeoutTime" BU_SG_REL_ IHU SG_ 914 CEM_2_RainDetected 400;
BA_REL_ "GenSigTimeoutTime" BU_SG_REL_ IHU SG_ 914 CEM_2_WiperSensitivitySWSts 400;
BA_REL_ "GenSigTimeoutTime" BU_SG_REL_ IHU SG_ 914 CEM_2_RainSensorFailSts 400;
BA_REL_ "GenSigTimeoutTime" BU_SG_REL_ IHU SG_ 914 BCM_4_RARDfstCmd 400;
BA_REL_ "GenSigTimeoutTime" BU_SG_REL_ IHU SG_ 914 CEM_2_WiperSelectionSts 400;
BA_REL_ "GenSigTimeoutTime" BU_SG_REL_ IHU SG_ 914 BCM_4_FrontFogLightSts 400;
BA_REL_ "GenSigTimeoutTime" BU_SG_REL_ IHU SG_ 914 CEM_2_Laser_High_Beam_Assist_Sta 400;
BA_REL_ "GenSigTimeoutTime" BU_SG_REL_ IHU SG_ 914 CEM_2_ReverseGearSwitch 400;
BA_REL_ "GenSigTimeoutTime" BU_SG_REL_ IHU SG_ 914 BCM_4_RearFogLightSts 400;
BA_REL_ "GenSigTimeoutTime" BU_SG_REL_ IHU SG_ 914 CEM_2_External_WelcomelightSts 400;
BA_REL_ "GenSigTimeoutTime" BU_SG_REL_ IHU SG_ 914 BCM_4_Mirror_Fold_Sts 400;
BA_REL_ "GenSigTimeoutTime" BU_SG_REL_ IHU SG_ 914 BCM_4_TrunkSts 400;
BA_REL_ "GenSigTimeoutTime" BU_SG_REL_ IHU SG_ 914 BCM_4_LHRdoorSts 400;
BA_REL_ "GenSigTimeoutTime" BU_SG_REL_ IHU SG_ 914 BCM_4_RHRDoorSts 400;
BA_REL_ "GenSigTimeoutTime" BU_SG_REL_ IHU SG_ 914 CEM_2_SunRoofSts 400;
BA_REL_ "GenSigTimeoutTime" BU_SG_REL_ IHU SG_ 914 BCM_4_BonnetSts 400;
BA_REL_ "GenSigTimeoutTime" BU_SG_REL_ IHU SG_ 914 BCM_4_PsngrDoorSts 400;
BA_REL_ "GenSigTimeoutTime" BU_SG_REL_ IHU SG_ 914 BCM_4_DriverDoorSts 400;
BA_REL_ "GenSigTimeoutTime" BU_SG_REL_ IHU SG_ 914 BCM_4_FollowMeTimeSts 400;
BA_REL_ "GenSigTimeoutTime" BU_SG_REL_ IHU SG_ 914 BCM_4_BlankingnumberSts 400;
BA_REL_ "GenSigTimeoutTime" BU_SG_REL_ IHU SG_ 914 CEM_2_DirectionIndLeft 400;
BA_REL_ "GenSigTimeoutTime" BU_SG_REL_ IHU SG_ 914 CEM_2_DirectionIndRight 400;
BA_REL_ "GenSigTimeoutTime" BU_SG_REL_ IHU SG_ 914 BCM_4_DRLSts 400;
BA_REL_ "GenSigTimeoutTime" BU_SG_REL_ IHU SG_ 914 BCM_4_LowBeamSts 400;
BA_REL_ "GenSigTimeoutTime" BU_SG_REL_ IHU SG_ 914 CEM_2_Laser_LightSts 400;
BA_REL_ "GenSigTimeoutTime" BU_SG_REL_ IHU SG_ 914 BCM_4_HighBeamSts 400;
BA_REL_ "GenSigTimeoutTime" BU_SG_REL_ IHU SG_ 914 BCM_4_ParkTailLightSts 400;
BA_REL_ "GenSigTimeoutTime" BU_SG_REL_ IHU SG_ 914 BCM_4_BrakePedalSts 400;
BA_REL_ "GenSigTimeoutTime" BU_SG_REL_ IHU SG_ 914 BCM_4_LHTurnlightSts 400;
BA_REL_ "GenSigTimeoutTime" BU_SG_REL_ IHU SG_ 914 BCM_4_RHTurnlightSts 400;
BA_REL_ "GenSigTimeoutTime" BU_SG_REL_ IHU SG_ 914 CEM_2_BlankchanginglaneSts 400;
BA_REL_ "GenSigTimeoutTime" BU_SG_REL_ IHU SG_ 914 BCM_4_KeySts 400;
BA_REL_ "GenSigTimeoutTime" BU_SG_REL_ IHU SG_ 914 CEM_2_FollowMeHomeSts 400;
BA_REL_ "GenSigTimeoutTime" BU_SG_REL_ IHU SG_ 914 CEM_2_KeyRemindWarning 400;
BA_REL_ "GenSigTimeoutTime" BU_SG_REL_ IHU SG_ 914 BCM_4_ParkLightOnWarning 400;
BA_REL_ "GenSigTimeoutTime" BU_SG_REL_ IHU SG_ 914 BCM_4_FollowMeHomeTimeSts 400;
BA_REL_ "GenSigTimeoutTime" BU_SG_REL_ IHU SG_ 1340 RBCM_FGHeat_Request_CommandFB 2000;
BA_REL_ "GenSigTimeoutTime" BU_SG_REL_ IHU SG_ 1340 RBCM_2_RRSeatHeatVentSwSts 2000;
BA_REL_ "GenSigTimeoutTime" BU_SG_REL_ IHU SG_ 1340 RBCM_2_LRSeatHeatVentSwSts 2000;
BA_REL_ "GenSigTimeoutTime" BU_SG_REL_ IHU SG_ 1340 RBCM_MFS_ShakeSts 2000;
BA_REL_ "GenSigTimeoutTime" BU_SG_REL_ IHU SG_ 1306 CEM_IPM_AC_DisplaySts 2000;
BA_REL_ "GenSigTimeoutTime" BU_SG_REL_ IHU SG_ 1306 CLM_2_Custom_Air_Conditioning 2000;
BA_REL_ "GenSigTimeoutTime" BU_SG_REL_ IHU SG_ 1306 CLM_2_Automatic_Ventilation 2000;
BA_REL_ "GenSigTimeoutTime" BU_SG_REL_ IHU SG_ 1306 CLM_2_First_BlowingSts 2000;
BA_REL_ "GenSigTimeoutTime" BU_SG_REL_ IHU SG_ 1306 CEM_IPM_FRSeatHeatVentSwSts 2000;
BA_REL_ "GenSigTimeoutTime" BU_SG_REL_ IHU SG_ 1306 CEM_IPM_FLSeatHeatVentSwSts 2000;
BA_REL_ "GenSigTimeoutTime" BU_SG_REL_ IHU SG_ 1306 CEM_IPM_TempknobRollingCounter 2000;
BA_REL_ "GenSigTimeoutTime" BU_SG_REL_ IHU SG_ 1306 CLM_2_AnionPurify 2000;
BA_REL_ "GenSigTimeoutTime" BU_SG_REL_ IHU SG_ 1306 CEM_IPM_PM25_Detect 2000;
BA_REL_ "GenSigTimeoutTime" BU_SG_REL_ IHU SG_ 1306 CLM_2_SyncSts 2000;
BA_REL_ "GenSigTimeoutTime" BU_SG_REL_ IHU SG_ 1306 CLM_2_FrontAutoACSts 2000;
BA_REL_ "GenSigTimeoutTime" BU_SG_REL_ IHU SG_ 1306 CEM_IPM_RearBlowModeSts 2000;
BA_REL_ "GenSigTimeoutTime" BU_SG_REL_ IHU SG_ 1306 CEM_IPM_RearAutoACSts 2000;
BA_REL_ "GenSigTimeoutTime" BU_SG_REL_ IHU SG_ 1306 CEM_IPM_RearBlowSpdCtrlSts 2000;
BA_REL_ "GenSigTimeoutTime" BU_SG_REL_ IHU SG_ 1306 CEM_IPM_RearTempsts 2000;
BA_REL_ "GenSigTimeoutTime" BU_SG_REL_ IHU SG_ 1306 CLM_2_RearOFFsts 2000;
BA_REL_ "GenSigTimeoutTime" BU_SG_REL_ IHU SG_ 1306 CEM_IPM_RearDefrosts 2000;
BA_REL_ "GenSigTimeoutTime" BU_SG_REL_ IHU SG_ 1306 CLM_2_FrontOFFSts 2000;
BA_REL_ "GenSigTimeoutTime" BU_SG_REL_ IHU SG_ 1306 CLM_2_ACStatus 2000;
BA_REL_ "GenSigTimeoutTime" BU_SG_REL_ IHU SG_ 1306 CLM_2_RecyMode 2000;
BA_REL_ "GenSigTimeoutTime" BU_SG_REL_ IHU SG_ 1306 CLM_2_FrontBlowModeSts 2000;
BA_REL_ "GenSigTimeoutTime" BU_SG_REL_ IHU SG_ 1306 CLM_2_FrontBlowSpdCtrlsts 2000;
BA_REL_ "GenSigTimeoutTime" BU_SG_REL_ IHU SG_ 1306 CLM_2_FRTempsts 2000;
BA_REL_ "GenSigTimeoutTime" BU_SG_REL_ IHU SG_ 1306 CLM_2_FLTempsts 2000;
BA_REL_ "GenSigTimeoutTime" BU_SG_REL_ IHU SG_ 952 AQS_SnsrAirQlyRespAQSLifeCntr 2000;
BA_REL_ "GenSigTimeoutTime" BU_SG_REL_ IHU SG_ 952 AQS_SnsrAirQlyRespAQSErrSts 2000;
BA_REL_ "GenSigTimeoutTime" BU_SG_REL_ IHU SG_ 952 AQS_SnsrAirQlyRespAQSNO2Sts 2000;
BA_REL_ "GenSigTimeoutTime" BU_SG_REL_ IHU SG_ 952 AQS_SnsrAirQlyRespAQSCOSts 2000;
BA_REL_ "GenSigTimeoutTime" BU_SG_REL_ IHU SG_ 952 AQS__SnsrAirQlyRespAirQlySts 2000;
BA_REL_ "GenSigTimeoutTime" BU_SG_REL_ IHU SG_ 1381 S_RAIN 4000;
BA_REL_ "GenSigTimeoutTime" BU_SG_REL_ IHU SG_ 1381 S_AUTOPANEL 4000;
VAL_ 3221225472 RBCM_MFS_HeatSts 1 "Active(1)" 0 "Not Active(0)" ;
VAL_ 804 R_MUTE_SW 3 "invalid(3)" 2 "Stuck(2)" 1 "Pressed(1)" 0 "Notaction(0)" ;
VAL_ 804 R_RIGHT_SW 3 "invalid(3)" 2 "Stuck(2)" 1 "Pressed(1)" 0 "Notaction(0)" ;
VAL_ 804 R_LEFT_SW 3 "invalid(3)" 2 "Stuck(2)" 1 "Pressed(1)" 0 "Notaction(0)" ;
VAL_ 804 R_DW_SW 3 "error(3)" 2 "Fake button(2)" 1 "Scroll Once(1)" 0 "Button not pressed(0)" ;
VAL_ 804 R_UP_SW 3 "error(3)" 2 "Fake button(2)" 1 "Scroll Once(1)" 0 "Button not pressed(0)" ;
VAL_ 1262 LightShowSts 31 "Reserved" 30 "Reserved" 29 "Reserved" 28 "Reserved" 27 "Reserved" 26 "Reserved" 25 "Reserved" 24 "Reserved" 23 "Reserved" 22 "Reserved" 21 "Reserved" 20 "Reserved" 19 "Reserved" 18 "Reserved" 17 "Reserved" 16 "Reserved" 15 "Reserved" 14 "Reserved" 13 "Reserved" 12 "Reserved" 11 "Reserved" 10 "Reserved" 9 "Reserved" 8 "Reserved" 7 "Reserved" 6 "Reserved" 5 "Reserved" 4 "Reserved" 3 "Reserved" 2 "Light show Animation Close" 1 "Light show Animation Open" 0 "No_Request" ;
VAL_ 1322 SET_FrontWindscreenHeatiReq 3 "Reserved" 2 "Active" 1 "NotActive" 0 "Invalid" ;
VAL_ 1322 SET_RRSeatHeatVentSwReq 7 "Reserved" 6 "Reserved" 5 "Reserved" 4 "Level_3_Heat_Request" 3 "Level_2_Heat_Request" 2 "Level_1_Heat_Request" 1 "OFF" 0 "NoActive" ;
VAL_ 1322 SET_LRSeatHeatVentSwReq 7 "Reserved" 6 "Reserved" 5 "Reserved" 4 "Level_3_Heat_Request" 3 "Level_2_Heat_Request" 2 "Level_1_Heat_Request" 1 "OFF" 0 "NoActive" ;
VAL_ 1111 AVAS_FunctionSts 1 " OFF(1)" 0 " ON(0)" ;
VAL_ 1057 LimitSpeedSts 5 "Kickdown(5)" 4 "Cancel(4)" 3 "Limit(3)" 2 "Overspeed(2)" 1 "Standby(1)" 0 "Off(0)" ;
VAL_ 1142 FuelTankLidSts 1 "Open(1)" 0 "Close(0)" ;
VAL_ 1044 HCU_2_G_ChrgnFctMemSt 3 " Reserved(3)" 2 " No Remember(2)" 1 " Remember (1)" 0 " Not Active(0)" ;
VAL_ 1044 HCU_RegenerateLevel 3 " Reserved(3)" 2 " low level(2)" 1 " middle level (1)" 0 " high level(0)" ;
VAL_ 1044 HCU_SetSOCFed 7 "Reserved(7)" 6 "Reserved(6)" 5 "72%(5)" 4 "64%(4)" 3 "56%(3)" 2 "48%(2)" 1 "40%(1)" 0 "30%(0)" ;
VAL_ 1044 HCU_SocManageFed 7 " Reserved(7)" 6 " Reserved(6)" 5 " Reserved(5)" 4 " Reserved(4)" 3 "Charge(3)" 2 " Auto(2)" 1 " SAVE (1)" 0 " Default(0)" ;
VAL_ 1044 HCU_EnergyFlow 31 "Reserved(31)" 30 "Reserved(30)" 29 "Reserved(29)" 28 "Reserved(28)" 27 "Reserved(27)" 26 "Reserved(26)" 25 "Reserved(25)" 24 "Reserved(24)" 23 "Reserved(23)" 22 "Reserved(22)" 21 "Reserved(21)" 20 "Reserved(20)" 19 "Reserved(19)" 18 "Reserved(18)" 17 "Reserved(17)" 16 "Reserved(16)" 15 "Charge(15)" 14 "4WD_ReGenerateBrake(14)" 13 "2WD_ReGenerateBrake(13)" 12 "Parking_Generate(12)" 11 "Running_Generate(11)" 10 "Engine(10)" 9 "4WD_Parallel(9)" 8 "2WD_Parallel(8)" 7 "4WD_ExtendRangeCharge(7)" 6 "4WD_ExtendRangeDisCharge(6)" 5 "2WD_ExtendRangeCharge(5)" 4 "2WD_ExtendRangeDisCharge(4)" 3 "4WD_EV(3)" 2 "2WD_EV(2)" 1 "Ready(1)" 0 "OFF(0)" ;
VAL_ 1034 HCU_PTReady 1 "LmpON" 0 "LmpOFF" ;
VAL_ 1034 HCU_PowertrainFault 1 " Fault(1)" 0 " No Fault(0)" ;
VAL_ 1034 HCU_PowerModeFed 3 " Reserved(3)" 2 " HEV                                     (2)" 1 " EV (1)" 0 " Not Active                                   (0)" ;
VAL_ 1183 BMSH_PackChargingThermalSt 0 "None" 7 " cooling(Reserved)(7)" 6 " Balance temperature(Reserved)(6)" 5 "ThermalError(5)" 4 "ChargeFinish(4)" 3 "Charging(3)" 2 "CoolingAndCharging(2)" 1 "Heating(1)" ;
VAL_ 1103 BMS_8_CC2Sts 1 "Connecyed" 0 "No Connect" ;
VAL_ 1103 BMS_8_PackDCChargingSt 15 "Reserved(15)" 14 "Reserved(14)" 13 "Reserved(13)" 12 "Reserved(12)" 11 "Reserved(11)" 10 "Reserved(10)" 9 "Fault(9)" 8 "CoolingAndCharging(8)" 7 " Cooling(7)" 6 " Balance temperature(6)" 5 " ThermalError (5)" 4 " ChargeFinish(4)" 3 " Charging(3)" 2 " HeatingAndCharging(2)" 1 " Heating(1)" 0 " None(0)" ;
VAL_ 2047 Start_Aging 1 "ON(1)" 0 "OFF(0)" ;
VAL_ 856 TBOX_TimeToStopChargeHourFed 31 "Invalid" 30 "Inactive" 29 "Reserved(29)" 28 "Reserved(28)" 27 "Reserved(27)" 26 "Reserved(26)" 25 "Reserved(25)" 24 "Reserved" 23 "23" 22 "22" 21 "21" 20 "20" 19 "19" 18 "18" 17 "17" 16 "16" 15 "15" 14 "14" 13 "13" 12 "12" 11 "11" 10 "10" 9 "9" 8 "8" 7 "7" 6 "6" 5 "5" 4 "4" 3 "3" 2 "2" 1 "1" 0 "0" ;
VAL_ 856 TBOX_TimeToStartChargeMinuteFed 63 "Invalid" 62 "Inactive" 61 " Reserved(61)" 60 "Reserved" 59 "59" 58 "58" 57 "57" 56 "56" 55 "55" 54 "54" 53 "53" 52 "52" 51 "51" 50 "50" 49 "49" 48 "48" 47 "47" 46 "46" 45 "45" 44 "44" 43 "43" 42 "42" 41 "41" 40 "40" 39 "39" 38 "38" 37 "37" 36 "36" 35 "35" 34 "34" 33 "33" 32 "32" 31 "31" 30 "30" 29 "29" 28 "28" 27 "27" 26 "26" 25 "25" 24 "24" 23 "23" 22 "22" 21 "21" 20 "20" 19 "19" 18 "18" 17 "17" 16 "16" 15 "15" 14 "14" 13 "13" 12 "12" 11 "11" 10 "10" 9 "9" 8 "8" 7 "7" 6 "6" 5 "5" 4 "4" 3 "3" 2 "2" 1 "1" 0 "0" ;
VAL_ 856 TBOX_TimeToStartChargeHourFed 31 "Invalid" 30 "Inactive" 29 " Reserved(29)" 28 " Reserved(28)" 27 " Reserved(27)" 26 " Reserved(26)" 25 " Reserved(25)" 24 "Reserved" 23 "23" 22 "22" 21 "21" 20 "20" 19 "19" 18 "18" 17 "17" 16 "16" 15 "15" 14 "14" 13 "13" 12 "12" 11 "11" 10 "10" 9 "9" 8 "8" 7 "7" 6 "6" 5 "5" 4 "4" 3 "3" 2 "2" 1 "1" 0 "0" ;
VAL_ 856 TBOX_ChargeModeSts 3 "Cycel Reservation Charge(3)" 2 "Singel Reservation Charge(2)" 1 "Immediate_Charge(1)" 0 "No_Charge(0)" ;
VAL_ 1025 Welcome_OutsoundSts 3 "Music_4(3)" 2 "Music_3(2)" 1 "Music_2 (1)" 0 "Music_1(0)" ;
VAL_ 1025 Person_RemindSts 1 "Active(1)" 0 "Not_Active(0)" ;
VAL_ 1025 Welcome_Outsound_SwitchSts 1 "Active(1)" 0 "Not_Active(0)" ;
VAL_ 803 MFS3_ICM_Left 3 "invalid(3)" 2 "Stuck(2)" 1 "Pressed(1)" 0 "Notaction(0)" ;
VAL_ 803 MFS3_ICM_Down_Zoom_Out 3 "invalid(3)" 2 "Stuck(2)" 1 "Pressed(1)" 0 "Notaction(0)" ;
VAL_ 803 MFS3_ICM_UP_Zoom_In 3 "error(3)" 2 "Fake button(2)" 1 "Scroll Once(1)" 0 "Button not pressed(0)" ;
VAL_ 803 MFS3_Instrument_SetReturn 3 "error(3)" 2 "Fake button(2)" 1 "Scroll Once(1)" 0 "Button not pressed(0)" ;
VAL_ 1120 Enter_super_fast_charge 255 "Reserved(255)" 254 "Reserved(254)" 253 "Reserved(253)" 252 "Reserved(252)" 251 "Reserved(251)" 250 "Reserved(250)" 249 "Reserved(249)" 248 "Reserved(248)" 247 "Reserved(247)" 246 "Reserved(246)" 245 "Reserved(245)" 244 "Reserved(244)" 243 "Reserved(243)" 242 "Reserved(242)" 241 "Reserved(241)" 240 "Reserved(240)" 239 "Reserved(239)" 238 "Reserved(238)" 237 "Reserved(237)" 236 "Reserved(236)" 235 "Reserved(235)" 234 "Reserved(234)" 233 "Reserved(233)" 232 "Reserved(232)" 231 "Reserved(231)" 230 "Reserved(230)" 229 "Reserved(229)" 228 "Reserved(228)" 227 "Reserved(227)" 226 "Reserved(226)" 225 "Reserved(225)" 224 "Reserved(224)" 223 "Reserved(223)" 222 "Reserved(222)" 221 "Reserved(221)" 220 "Reserved(220)" 219 "Reserved(219)" 218 "Reserved(218)" 217 "Reserved(217)" 216 "Reserved(216)" 215 "Reserved(215)" 214 "Reserved(214)" 213 "Reserved(213)" 212 "Reserved(212)" 211 "Reserved(211)" 210 "Reserved(210)" 209 "Reserved(209)" 208 "Reserved(208)" 207 "Reserved(207)" 206 "Reserved(206)" 205 "Reserved(205)" 204 "Reserved(204)" 203 "Reserved(203)" 202 "Reserved(202)" 201 "Reserved(201)" 200 "Reserved(200)" 199 "Reserved(199)" 198 "Reserved(198)" 197 "Reserved(197)" 196 "Reserved(196)" 195 "Reserved(195)" 194 "Reserved(194)" 193 "Reserved(193)" 192 "Reserved(192)" 191 "Reserved(191)" 190 "Reserved(190)" 189 "Reserved(189)" 188 "Reserved(188)" 187 "Reserved(187)" 186 "Reserved(186)" 185 "Reserved(185)" 184 "Reserved(184)" 183 "Reserved(183)" 182 "Reserved(182)" 181 "Reserved(181)" 180 "Reserved(180)" 179 "Reserved(179)" 178 "Reserved(178)" 177 "Reserved(177)" 176 "Reserved(176)" 175 "Reserved(175)" 174 "Reserved(174)" 173 "Reserved(173)" 172 "Reserved(172)" 171 "Reserved(171)" 170 "Reserved(170)" 169 "Reserved(169)" 168 "Reserved(168)" 167 "Reserved(167)" 166 "Reserved(166)" 165 "Reserved(165)" 164 "Reserved(164)" 163 "Reserved(163)" 162 "Reserved(162)" 161 "Reserved(161)" 160 "Reserved(160)" 159 "Reserved(159)" 158 "Reserved(158)" 157 "Reserved(157)" 156 "Reserved(156)" 155 "Reserved(155)" 154 "Reserved(154)" 153 "Reserved(153)" 152 "Reserved(152)" 151 "Reserved(151)" 150 "Reserved(150)" 149 "Reserved(149)" 148 "Reserved(148)" 147 "Reserved(147)" 146 "Reserved(146)" 145 "Reserved(145)" 144 "Reserved(144)" 143 "Reserved(143)" 142 "Reserved(142)" 141 "Reserved(141)" 140 "Reserved(140)" 139 "Reserved(139)" 138 "Reserved(138)" 137 "Reserved(137)" 136 "Reserved(136)" 135 "Reserved(135)" 134 "Reserved(134)" 133 "Reserved(133)" 132 "Reserved(132)" 131 "Reserved(131)" 130 "Reserved(130)" 129 "Reserved(129)" 128 "Reserved(128)" 127 "Reserved(127)" 126 "Reserved(126)" 125 "Reserved(125)" 124 "Reserved(124)" 123 "Reserved(123)" 122 "Reserved(122)" 121 "Reserved(121)" 120 "Reserved(120)" 119 "Reserved(119)" 118 "Reserved(118)" 117 "Reserved(117)" 116 "Reserved(116)" 115 "Reserved(115)" 114 "Reserved(114)" 113 "Reserved(113)" 112 "Reserved(112)" 111 "Reserved(111)" 110 "Reserved(110)" 109 "Reserved(109)" 108 "Reserved(108)" 107 "Reserved(107)" 106 "Reserved(106)" 105 "Reserved(105)" 104 "Reserved(104)" 103 "Reserved(103)" 102 "Reserved(102)" 101 "Reserved(101)" 100 "Reserved(100)" 99 "Reserved(99)" 98 "Reserved(98)" 97 "Reserved(97)" 96 "Reserved(96)" 95 "Reserved(95)" 94 "Reserved(94)" 93 "Reserved(93)" 92 "Reserved(92)" 91 "Reserved(91)" 90 "Reserved(90)" 89 "Reserved(89)" 88 "Reserved(88)" 87 "Reserved(87)" 86 "Reserved(86)" 85 "Reserved(85)" 84 "Reserved(84)" 83 "Reserved(83)" 82 "Reserved(82)" 81 "Reserved(81)" 80 "Reserved(80)" 79 "Reserved(79)" 78 "Reserved(78)" 77 "Reserved(77)" 76 "Reserved(76)" 75 "Reserved(75)" 74 "Reserved(74)" 73 "Reserved(73)" 72 "Reserved(72)" 71 "Reserved(71)" 70 "Reserved(70)" 69 "Reserved(69)" 68 "Reserved(68)" 67 "Reserved(67)" 66 "Reserved(66)" 65 "Reserved(65)" 64 "Reserved(64)" 63 "Reserved(63)" 62 "Reserved(62)" 61 "Reserved(61)" 60 "Reserved(60)" 59 "Reserved(59)" 58 "Reserved(58)" 57 "Reserved(57)" 56 "Reserved(56)" 55 "Reserved(55)" 54 "Reserved(54)" 53 "Reserved(53)" 52 "Reserved(52)" 51 "Reserved(51)" 50 "Reserved(50)" 49 "Reserved(49)" 48 "Reserved(48)" 47 "Reserved(47)" 46 "Reserved(46)" 45 "Reserved(45)" 44 "Reserved(44)" 43 "Reserved(43)" 42 "Reserved(42)" 41 "Reserved(41)" 40 "Reserved(40)" 39 "Reserved(39)" 38 "Reserved(38)" 37 "Reserved(37)" 36 "Reserved(36)" 35 "Reserved(35)" 34 "Reserved(34)" 33 "Reserved(33)" 32 "Reserved(32)" 31 "Reserved(31)" 30 "Reserved(30)" 29 "Reserved(29)" 28 "Reserved(28)" 27 "Reserved(27)" 26 "Reserved(26)" 25 "Reserved(25)" 24 "Reserved(24)" 23 "Reserved(23)" 22 "Reserved(22)" 21 "Reserved(21)" 20 "Reserved(20)" 19 "Reserved(19)" 18 "Reserved(18)" 17 "Reserved(17)" 16 "Reserved(16)" 15 "Reserved(15)" 14 "Reserved(14)" 13 "Reserved(13)" 12 "Reserved(12)" 11 "Reserved(11)" 10 "Reserved(10)" 9 "Reserved(9)" 8 "Reserved(8)" 7 "Reserved(7)" 6 "Reserved(6)" 5 "Reserved(5)" 4 "Reserved(4)" 3 "Enter OPPO super fast charge(3)" 2 "Enter MI super fast charge(2)" 1 "Enter HUAWEI super fast charge(1)" 0 "Not entering super fast charge(0)" ;
VAL_ 1120 WCM_Electricity_decimal 99 " .99%(99)" 1 " .01%(1)" 0 " .00%(0)" ;
VAL_ 1120 WCM_Electricity_integer 100 "100%(100)" 99 "99%(99)" 1 "1%(1)" 0 "0%(0)" ;
VAL_ 1120 WCM_PhoneDetectionStatus 1 "Phone forget reminder(1)" 0 "Default Value(0)" ;
VAL_ 1120 WCM_WirelessChargingStatus 15 "Reserved(15)" 14 "Reserved(14)" 13 "Reserved(13)" 12 "Reserved(12)" 11 "Reserved(11)" 10 "Reserved(10)" 9 "PEPS Stop Charging(9)" 8 "Other Faults(8)" 7 "Finished Charging(7)" 6 "Over temperature protection(6)" 5 "FOD(5)" 4 "Input Undervoltage protection(4)" 3 "Input Overvoltage protection(3)" 2 "Charging(2)" 1 "Standby(1)" ;
VAL_ 1120 WCM_WirelessChargingSetStatus 1 "Open(1)" 0 "Closed(0)" ;
VAL_ 1338 PM2_5_ErrSts 3 "Reserved(3)" 2 "Reserved(2)" 1 "Error(1)" 0 "No_Error(0)" ;
VAL_ 1338 PM2_5_Sts 1 "Active(1)" 0 "Standby(0)" ;
VAL_ 1338 PM2_5_AirIOutQLevel 5 "Level_6_PM25<999_And_PM25≥250(5)" 3 "Level_4_PM25<150_And_PM25≥115(3)" 2 "Level_3_PM25<115_And_PM25≥75(2)" 1 "Level_2_PM25<75_And_PM25≥35(1)" 0 "Level_1_PM25<35(0)" ;
VAL_ 1338 PM2_5_AirInQLevel 5 "Level_6_PM25<999_And_PM25≥250(5)" 3 "Level_4_PM25<150_And_PM25≥115(3)" 2 "Level_3_PM25<115_And_PM25≥75(2)" 1 "Level_2_PM25<75_And_PM25≥35(1)" 0 "Level_1_PM25<35(0)" ;
VAL_ 787 ABS_ESP_3_AVHSts 3 "Not_Used(3)" 2 "Active(2)" 1 "Standby(1)" 0 "Off(0)" ;
VAL_ 1141 RAD2_Radar_FunctionModel_Status 7 "Reserved(7)" 6 "Reserved(6)" 5 "Reserved(5)" 4 "Reserved(4)" 3 "Radar Block(3)" 2 "Radar Failure(2)" 1 "Radar Normal (1)" 0 "Default(0)" ;
VAL_ 1050 AVM_APA_SystemSts 7 "Invalid(7)" 6 "Terminated(6)" 5 "Failure(5)" 4 "Completed(4)" 3 "Guidance_active(3)" 2 "Searching(2)" 1 "Standby(1)" 0 "off(0)" ;
VAL_ 1050 APA_Parking_Space_Search_Sts 1 "Parking_Space_Detected(1)" 0 "No_Parking_Space(0)" ;
VAL_ 1050 AVM_FactoryMode 1 "Factory_Mode(1)" 0 "Normal_Mode(0)" ;
VAL_ 1050 APA_3AVMFeedbackSts_RemoteMode 1 "On(1)" 0 "Off(0)" ;
VAL_ 1050 AVMDisplaySts 1 "On(1)" 0 "Off(0)" ;
VAL_ 1288 APA_2_AVMStatusFault 1 "Failure(1)" 0 "Not_Failure(0)" ;
VAL_ 1288 APA_2_AVMFaultStatusCameraRight 1 "Failure(1)" 0 "Not_Failure(0)" ;
VAL_ 1288 APA_2_AVMFaultStatusCameraRear 1 "Active(1)" 0 "Not_Active(0)" ;
VAL_ 1288 APA_2_AVMFaultStatusCameraLeft 1 "Failure(1)" 0 "Normal(0)" ;
VAL_ 1288 APA_2_AVMFaultStatusCameraFront 1 "Failure(1)" 0 "Normal(0)" ;
VAL_ 773 FRM_3_DistanceWarning_On_Off_Sts 1 "On(1)" 0 "Off(0)" ;
VAL_ 773 FRM_3_AEB_ON_OFF_Sts 1 "On(1)" 0 "Off(0)" ;
VAL_ 773 FRM_3_FCW_OPTION_Sts 3 "Earlier(3)" 2 "Laster(2)" 1 "Midder(1)" 0 "Reserved(0)" ;
VAL_ 773 FRM_3_FCW_ON_OFF_Sts 1 "On(1)" 0 "Off(0)" ;
VAL_ 773 FRM_3_TimeGapLastSet_DVD 1 "On(1)" 0 "Off(0)" ;
VAL_ 773 FRM_3_FCW_PreWarning 1 "Warning(1)" 0 "No_Warning(0)" ;
VAL_ 773 FRM_3_DistanceWarning 1 "Warning(1)" 0 "No_Warning(0)" ;
VAL_ 773 FRM_3_AEBMode 3 "Failure_Mode(3)" 2 "Active_Mode(2)" 1 "On_Mode(1)" 0 "OFF_Mode(0)" ;
VAL_ 773 FRM_3_FCWMode 3 "Failure_Mode(3)" 2 "Active_Mode(2)" 1 "On_Mode(1)" 0 "OFF_Mode(0)" ;
VAL_ 773 FRM_3_ACCMode 9 "Failure_Mode(9)" 8 "reserved(8)" 7 "Override(7)" 6 "Stand_Wait(6)" 5 "Stand_Active(5)" 4 "Brake_Only_Mode(4)" 3 "Active_Control_Mode(3)" 2 "Stand_By_Mode(2)" 1 "Passive_Mode(1)" 0 "OFF_Mode(0)" ;
VAL_ 773 FRM_3_TimeGapSet_ICM 3 "No_Display(3)" 2 "TauGap_2(2)" 1 "TauGap_1(1)" 0 "TauGap_0(0)" ;
VAL_ 773 FRM_3_TimeGapSet_DVD 3 "No_Display(3)" 2 "TauGap_2(2)" 1 "TauGap_1(1)" 0 "TauGap_0(0)" ;
VAL_ 773 FRM_3_TakeOverReq 1 "Requst(1)" 0 "No_Requst(0)" ;
VAL_ 773 FRM_3_Textinfo 31 "Reserved" 30 "Reserved" 29 "unabletoactiveACCduetospeedlimit" 28 "activeACCduetonotinDgear" 27 "activeACCduetobrakepedalpressed" 26 "activeACCduetoseatbeltunbuckled" 25 "unabletoactiveACCduetotrunkopen" 24 "unabletoactiveACCduetohoodopen" 23 "unabletoactiveACCduetodoorsopen" 22 "ACC_Is_Stand_Wait(22)" 21 "ACC_Is_Stand_Active(21)" 20 "Radar_Is_In_Error_Mode(20)" 19 "FCW_Is_In_Error_Mode(19)" 18 "FCW_Is_Active(18)" 17 "distanceWarning_Is_Active(17)" 16 "unable_To_Active_FCW(16)" 15 "FCW_Is_Switched_On(15)" 14 "FCW_Is_Switched_Off(14)" 13 "Radar_Is_Covered(13)" 12 "AEB_Is_In_Error_Mode(12)" 11 "AEB_Is_Active(11)" 10 "unable_To_Active_AEB(10)" 9 "AEB_Is_Switched_On(9)" 8 "AEB_Is_Switched_Off(8)" 7 "Driver_Take_Over(7)" 6 "ACC_Is_In_Error_Mode(6)" 5 "ACC_Is_Active(5)" 4 "unable_To_Active_ACC(4)" 3 "ACC_Is_Switched_On(3)" 2 "ACC_Is_Switched_Off(2)" 1 "ACC_Is_Cancelled(1)" 0 "No_Display(0)" ;
VAL_ 773 FRM_3_FrontObject_Type 7 "Reserved(7)" 6 "Reserved(6)" 5 "Others(5)" 4 "Bike(4)" 3 "Pedestrian(3)" 2 "Truck(2)" 1 "Car(1)" 0 "No_Display(0)" ;
VAL_ 773 FRM_3_ObjValid 1 "Target object detected(1)" 0 "No object(0)" ;
VAL_ 773 FRM_3_DxTarObj 7 "Reserved(7)" 6 "Reserved(6)" 5 "Reserved(5)" 4 "Reserved(4)" 3 "Distance_3(3)" 2 "Distance_2(2)" 1 "Distance_1(1)" 0 "No_Display(0)" ;
VAL_ 1241 FuelTankLidSystemFailureSts 1 "Failure(1)" 0 "No_Failure(0)" ;
VAL_ 1241 FuelTankPressureConditionReached 3 "Reserved(3)" 2 "Ready_To_Refuel(2)" 1 "Wait_To_Refuel(1)" 0 "Not_Active(0)" ;
VAL_ 632 EMS_4_EngineSts 0 "Not_Run(0)" 1 "Run(1)" ;
VAL_ 1202 GSM_STAT_ShifterLeverFault 0 "Shift_Sensors_Both_Ok(0)" 1 "Shift_Sensor_1_Fault(1)" 2 "Shift_Sensor_2_Fault(2)" 3 "Shift_Sensors_Both_Fault(3)" 4 "Reserve(4)" 5 "Reserve(5)" 6 "Reserve(6)" 7 "Invalid(7)" ;
VAL_ 1202 GSM_STAT_ParkButton 0 "no_Request(0)" 1 "driver_Request_Park_Button(1)" 2 "Park_Button_Fault(2)" 3 "reserved(3)" ;
VAL_ 1202 GSM_GearShiftPosInverse 0 "Reserved(0)" 1 "Reserved(1)" 2 "Reserved(2)" 3 "Reserved(3)" 4 "Reserved(4)" 5 "Reserved(5)" 6 "Reserved(6)" 7 "Shifter_Not_Initialized_INIT(7)" 8 "Tip-_Manual_Shift_Down_(8)" 9 "Tip+_Manual_Shift_Up_(9)" 10 "POS_FIVE_Backwards_Twice_Y2_(10)" 11 "POS_FOUR_Backwards_Once_Y1_(11)" 12 "POS_THREE_Forward_Once_X1_(12)" 13 "POS_TWO_Forward_Twice_X2_(13)" 14 "POS_ONE_Z_Manual_Position_(14)" 15 "POS_ZERO_Z_(15)" ;
VAL_ 1202 ACC_Cruise_Control 3 "OFF_Pressed(3)" 2 "Stuck(2)" 1 "ON_Pressed(1)" 0 "Notaction(0)" ;
VAL_ 1202 GSM_GearShiftPos 0 "POS_ZERO_Z(0)" 1 "POS_ONE_Z_Manual_Position(1)" 2 "POS_TWO_Forward_Twice_X2(2)" 3 "POS_THREE_Forward_Once_X1(3)" 4 "POS_FOUR_Backwards_Once_Y1(4)" 5 "POS_FIVE_Backwards_Twice_Y2(5)" 6 "Tip+_Manual_Shift_Up(6)" 7 "Tip-_Manual_Shift_Down(7)" 8 "Shifter_Not_Initialized_INIT(8)" 9 "Reserved(9)" 10 "Reserved(10)" 11 "Reserved(11)" 12 "Reserved(12)" 13 "Reserved(13)" 14 "Reserved(14)" 15 "Reserved(15)" ;
VAL_ 1507 DHM_1_Doorkonb_time_freeback 3 "180S(3)" 2 "90S(2)" 1 "30S(1)" 0 "Invalid_Default(0)" ;
VAL_ 1518 CEM_DHM_handlelockswitchfeedback 0 "close(0)" 1 "Open(1)" ;
VAL_ 1518 CEM_DHM_handleunlockswitchfeedba 0 "close(0)" 1 "Open(1)" ;
VAL_ 1517 CEM_SRF_lockingreason 7 "预留(7)" 6 "预留(6)" 5 "预留(5)" 4 "预留(4)" 3 "高速关天窗(3)" 2 "雨天关天窗(2)" 1 ":设防成功关闭(1)" 0 "默认值无效(0)" ;
VAL_ 1517 CEM_RR_window_up_Reason_feedback 7 "雨天关窗(7)" 6 "洗车模式(6)" 5 "TBOX(5)" 4 "设防成功(4)" 3 "IHU(3)" 2 "本地开关(2)" 1 "主驾LIN开关(1)" 0 "默认值(0)" ;
VAL_ 1517 CEM_LR_window_up_Reason_feedback 7 "雨天关窗(7)" 6 "洗车模式(6)" 5 "TBOX(5)" 4 "设防成功(4)" 3 "IHU(3)" 2 "本地开关(2)" 1 "主驾LIN开关(1)" 0 "默认值(0)" ;
VAL_ 1517 CEM_Passenger_window_up_Reason_f 7 "雨天关窗(7)" 6 "洗车模式(6)" 5 "TBOX(5)" 4 "设防成功(4)" 3 "IHU(3)" 2 "本地开关(2)" 1 "主驾LIN开关(1)" 0 "默认值(0)" ;
VAL_ 1517 CEM_Driver_window_up_Reason_feed 7 "雨天关窗(7)" 6 "预留(6)" 5 "洗车模式(5)" 4 "TBOX(4)" 3 "设防成功(3)" 2 "IHU(2)" 1 "主驾LIN开关(1)" 0 "默认值(0)" ;
VAL_ 1504 CEM_SRFclosingConditions 15 "Not used(15)" 14 "Not used(14)" 13 "Not used(13)" 12 "Not used(12)" 11 "Not used(11)" 10 "Not used(10)" 9 "Not used(9)" 8 "Not used(8)" 7 "Not used(7)" 6 "Not used(6)" 5 "Not used(5)" 4 "Not used(4)" 3 "vehicle speed(3)" 2 "rainy(2)" 1 "Remote control locking car(1)" 0 "NoAcitive(0)" ;
VAL_ 1504 CEM_Abat_VentCMDSts 15 "Not used(15)" 14 "Not used(14)" 13 "Not used(13)" 12 "tilt(12)" 11 "100%(11)" 10 "90%(10)" 9 "80%(9)" 8 "70%(8)" 7 "60%(7)" 6 "50%(6)" 5 "40%(5)" 4 "30%(4)" 3 "20%(3)" 2 "10%(2)" 1 "0%(1)" 0 "NoAcitive(0)" ;
VAL_ 1504 CEM_PSRFCMDSts 15 "Not used(15)" 14 "Not used(14)" 13 "Not used(13)" 12 "tilt(12)" 11 "100%(11)" 10 "90%(10)" 9 "80%(9)" 8 "70%(8)" 7 "60%(7)" 6 "50%(6)" 5 "40%(5)" 4 "30%(4)" 3 "20%(3)" 2 "10%(2)" 1 "0%(1)" 0 "NoAcitive(0)" ;
VAL_ 1168 CEM_ALM_1_SceneMode_ControlSwitc 3 "Reserved(3)" 2 "Reserved(2)" 1 "ON(1)" 0 "OFF(0)" ;
VAL_ 1168 CEM_ALM_1_DeletePeronalSet_FB 15 "Invaild(15)" 14 "Reserved(14)" 13 "Reserved(13)" 12 "Reserved(12)" 11 "Reserved(11)" 10 "Reserved(10)" 9 "Reserved(9)" 8 "Reserved(8)" 7 "Reserved(7)" 6 "Reserved(6)" 5 "Reset_User_ID_X(5)" 4 "Reset_User_ID_X(4)" 3 "Reset_User_ID_X(3)" 2 "Reset_User_ID_X(2)" 1 "Reset_User_ID_X(1)" 0 "Sartup_Default(0)" ;
VAL_ 1168 CEM_ALM_1_PersonalBeamEn 3 "Reserved(3)" 2 "Disable(2)" 1 "Enable(1)" 0 "Default(0)" ;
VAL_ 1168 CEM_ALM_1_PersonalSeatEn 3 "Reserved(3)" 2 "Disable(2)" 1 "Enable(1)" 0 "Default(0)" ;
VAL_ 1168 CEM_ALM_1_Seat_Set_Status 15 "Reserved(15)" 14 "Reserved(14)" 13 "Reserved(13)" 12 "Reserved(12)" 11 "Reserved(11)" 10 "Reserved(10)" 9 "Reserved(9)" 8 "return to position 3(8)" 7 "return to position 2(7)" 6 "return to position 1(6)" 5 "Adjustment Failed(5)" 4 "Setup Failed(4)" 3 "Setting position 3 succeeded(3)" 2 "Setting position 2 succeeded(2)" 1 "Setting position 1 succeeded(1)" 0 "Invalid(0)" ;
VAL_ 1168 CEM_ALM_1_Seat_Set_Pop_Up 2 "No_Active(2)" 1 "Active(1)" 0 "No_Request(0)" ;
VAL_ 1168 CEM_ALM_1_Wash_Car_Status 2 "No_Active(2)" 1 "Active(1)" 0 "No_Request(0)" ;
VAL_ 1168 CEM_ALM_1_PersonalSetSts 0 "NotActive(0)" 1 "Active(1)" ;
VAL_ 1168 CEM_ALM_1_STAT_WelcomeWaterLamp 3 "Reserved(3)" 2 "Reserved(2)" 1 "ON(1)" 0 "OFF(0)" ;
VAL_ 1168 CEM_ALM_1_STAT_AssociatedWithDri 3 "Reserved(3)" 2 "Reserved(2)" 1 "ON(1)" 0 "OFF(0)" ;
VAL_ 1168 CEM_ALM_1_STAT_Music 3 "Reserved(3)" 2 "Reserved(2)" 1 "ON(1)" 0 "OFF(0)" ;
VAL_ 1168 CEM_ALM_1_STAT_Apiluminance 15 "Invalid(15)" 14 "Reserved(14)" 13 "Reserved(13)" 12 "Reserved(12)" 11 "Reserved(11)" 10 "Reserved(10)" 9 "Reserved(9)" 8 "Reserved(8)" 7 "Level8(7)" 6 "Level7(6)" 5 "Level6(5)" 4 "Level5(4)" 3 "Level4(3)" 2 "Level3(2)" 1 "Level2(1)" 0 "Level1(0)" ;
VAL_ 1168 CEM_ALM_1_STAT_Static_Colour 15 "Invalid(15)" 14 "Reserved(14)" 13 "Reserved(13)" 12 "Reserved(12)" 11 "Reserved(11)" 10 "Reserved(10)" 9 "Reserved(9)" 8 "Reserved(8)" 7 "Purple(7)" 6 "Pink(6)" 5 "Red(5)" 4 "Orange(4)" 3 "Yellow(3)" 2 "Green(2)" 1 "Cyan(1)" 0 "Blue(0)" ;
VAL_ 1168 CEM_ALM_1_STAT_StaticEffect 7 "Startup(7)" 3 "All_Discolour_Breath(3)" 2 "Discolour_Breath(2)" 1 "Monochrome_Breath(1)" 0 "Monochrome_Static(0)" ;
VAL_ 1168 CEM_ALM_1_STAT_ControlSwitch 2 "Force(2)" 1 "OFF(1)" 0 "Control(0)" ;
VAL_ 1168 CEM_ALM_1_STAT_DMSMonitoring 3 "Reserved(3)" 2 "Reserved(2)" 1 "ON(1)" 0 "OFF(0)" ;
VAL_ 1168 CEM_ALM_1_STAT_PM2_5Monitoring 3 "Reserved(3)" 2 "Reserved(2)" 1 "ON(1)" 0 "OFF(0)" ;
VAL_ 1168 CEM_ALM_1_STAT_DriveApiluminance 2 "Close(2)" 1 "Dark(1)" 0 "Normal(0)" ;
VAL_ 1476 CEM_massagemodeSts 4 "5 Mode(4)" 3 "4 Mode(3)" 2 "3 Mode(2)" 1 "2 Mode(1)" 0 "1 Mode(0)" ;
VAL_ 1476 CEM_passageVibrationSts 2 "High(2)" 1 "Middle(1)" 0 "Low(0)" ;
VAL_ 1476 CEM_Passenger_massageSts 1 "Active(1)" 0 "No_Active(0)" ;
VAL_ 1476 CEM_Mirror_Driverseat_Location 21 "M+10(21)" 20 "M+9(20)" 19 "M+8(19)" 18 "M+7(18)" 17 "M+6(17)" 16 "M+5(16)" 15 "M+4(15)" 14 "M+3(14)" 13 "M+2(13)" 12 "M+1(12)" 10 "location 10(10)" 9 "location 9(9)" 8 "location 8(8)" 7 "location 7(7)" 6 "location 6(6)" 5 "location 5(5)" 4 "location 4(4)" 3 "location 3(3)" 2 "location 2(2)" 1 "location 1(1)" 0 "Startup/Default(0)" ;
VAL_ 1476 CEM_UnderVoltageSts 1 "Active(1)" 0 "Not Active(0)" ;
VAL_ 1476 CEM_RearWiper_SwitchSts 1 "Active(1)" 0 "Not Active(0)" ;
VAL_ 1476 BCM_Wiper_MaintenanceSts 1 "Active(1)" 0 "Not Active(0)" ;
VAL_ 1476 CEM_Mirror_Fold_SwitchSts 1 "Active(1)" 0 "Not Active(0)" ;
VAL_ 1476 CEM_IPM__FRSeatHeatVentSwSts 7 "Level_3_Ventilation_Request(7)" 6 "Level_2_Ventilation_Request(6)" 5 "Level_1_Ventilation_Request(5)" 4 "Level_3_Heat_Request(4)" 3 "Level_2_Heat_Request(3)" 2 "Level_1_Heat_Request(2)" 1 "OFF(1)" 0 "NO_Request(0)" ;
VAL_ 1476 CEM_IPM_FLSeatHeatVentSwSts 7 "Level_3_Ventilation_Request(7)" 6 "Level_2_Ventilation_Request(6)" 5 "Level_1_Ventilation_Request(5)" 4 "Level_3_Heat_Request(4)" 3 "Level_2_Heat_Request(3)" 2 "Level_1_Heat_Request(2)" 1 "OFF(1)" 0 "NO_Request(0)" ;
VAL_ 1476 CEM_DriverLumbart_UDSts 2 "Move Down(2)" 1 "Move Up(1)" 0 "Null(0)" ;
VAL_ 1476 CEM_DriverLumbart_FRSts 2 "Move Rear(2)" 1 "Move Front(1)" 0 "Null(0)" ;
VAL_ 1476 CEM_DriverSeat_RearendUDSts 2 "Move Down(2)" 1 "Move Up(1)" 0 "Null(0)" ;
VAL_ 1476 CEM_DriverSeat_FrontendUDSts 2 "Move Down(2)" 1 "Move Up(1)" 0 "Null(0)" ;
VAL_ 1476 CEM_DriverSeat_FRSts 2 "Move Rear(2)" 1 "Move Front(1)" 0 "Null(0)" ;
VAL_ 1476 CEM_DriverSeat_BackFRSts 2 "Move Rear(2)" 1 "Move Front(1)" 0 "Null(0)" ;
VAL_ 1476 CEM_MirrorFlip_CFGSts 3 "Left side and right side(3)" 2 "Right side(2)" 1 "Left side(1)" 0 "off(0)" ;
VAL_ 1476 CEM_RightMirrorCtrlSts 7 "Invalid Value(7)" 6 "Error Value(6)" 5 "Reserved(5)" 4 "Move Right(4)" 3 "Move Left(3)" 2 "Move Down(2)" 1 "Move Up(1)" 0 "Null(0)" ;
VAL_ 1476 CEM_LeftMirrorCtrlSts 7 "Invalid Value(7)" 6 "Error Value(6)" 5 "Reserved(5)" 4 "Move Right(4)" 3 "Move Left(3)" 2 "Move Down(2)" 1 "Move Up(1)" 0 "Null(0)" ;
VAL_ 1476 CEM_RHRdoor_buttonsts 1 "Pressed(1)" 0 "Notaction (0)" ;
VAL_ 1476 CEM_LHRdoor_buttonsts 1 "Pressed(1)" 0 "Notaction (0)" ;
VAL_ 1476 CEM_PsngrDoor_buttonsts 1 "Pressed(1)" 0 "Notaction (0)" ;
VAL_ 1476 CEM_Smart_HighBeamSts 1 "Active(1)" 0 "No Active(0)" ;
VAL_ 1476 CEM_HighBeam_AdjustSts 3 "The third gear(3)" 2 "The second gear(2)" 1 "The first gear(1)" 0 "The Zeroth gear(0)" ;
VAL_ 1535 CEM_3_passenger_Welcome_Seat_Sts 2 "No_Active" 1 "Active" 0 "lnvalid_Default" ;
VAL_ 1535 CEM_DHM_Doorkonbmode_feedback 2 "No_Popup(2)" 1 "Popup(1)" 0 "Invalid_Default(0)" ;
VAL_ 1535 CEM_DHM_Driver_unlockmode_feedba 2 "Fourdoor_unlock(2)" 1 "Drivedoor_unlock(1)" 0 "Invalid_Default(0)" ;
VAL_ 1535 CEM_UVC_LuminanceBf 7 "Reserved(7)" 6 "Reserved(6)" 5 "Reserved(5)" 4 "Reserved(4)" 3 "high(3)" 2 "Reserved(2)" 1 "Low(1)" 0 " No request_Initial value(0)" ;
VAL_ 1535 CEM_UVC_WorkingBf 3 "Auto request(3)" 2 "Open request(2)" 1 "Close request(1)" 0 " No request_ Initial value(0)" ;
VAL_ 1535 CEM_3_Welcome_Seat_Sts 2 "No_Active(2)" 1 "Active(1)" 0 "Invalid_Default(0)" ;
VAL_ 1535 CEM_IPM_3_ACMAXReq_Sts 2 " Active(2)" 1 "NOT Active(1)" 0 "Invalid(0)" ;
VAL_ 1535 CEM_3_PM25DisplayToggle_Sts 2 "Out(2)" 1 "In(1)" 0 "No Request(0)" ;
VAL_ 1535 CEM_3_DWM_Sts_Msg 0 "Error(0)" 3 "Rise(3)" 2 "Close(2)" 1 "Open(1)" ;
VAL_ 1535 CEM_3_EngineControlSts 0 "Receive_Fail(0)" 1 "Receive_Succeed(1)" ;
VAL_ 914 BCM_4_AlarmMode 15 "Invalid(15)" 14 "Invalid(14)" 13 "Invalid(13)" 12 "Invalid(12)" 11 "Invalid(11)" 10 "Invalid(10)" 9 "Invalid(9)" 8 "Invalid(8)" 7 "Invalid(7)" 6 "Invalid(6)" 5 "TrunkReleaseMode(5)" 4 "ArmingFaultMode(4)" 3 "DisableIntrusionMode(3)" 2 "IntrusionMode(2)" 1 "ArmingMode(1)" 0 "DisarmingMode(0)" ;
VAL_ 914 CEM_2_RemoteTrunkOnlySts 1 "Remote_Trunk_Only_Mode(1)" 0 "Not_Remote_Trunk_Only_Mode(0)" ;
VAL_ 914 BCM_4_AutoLockSts 1 "AutoLock Active(1)" 0 "AutoLock  NOT Active(0)" ;
VAL_ 914 CEM_2RearDefrosts 1 "Active(1)" 0 "Not_Active(0)" ;
VAL_ 914 CEM_2_HazardLampForUrgencyBrakeS 1 "HazardLampForUrgBrkMode(1)" 0 "HazardLampNotForUrgBrkMode(0)" ;
VAL_ 914 CEM_2_Mirror_FlipSts 1 "Off(1)" 0 "Active(0)" ;
VAL_ 914 BCM_4_RemoteLockFeedbackSts 3 "Not_Feedback(3)" 2 "Only_Speaker(2)" 1 "Only_Lamp(1)" 0 "Lamp_And_Speaker(0)" ;
VAL_ 914 BCM_4_AutoUnlockSts 1 "Auto_Unlock_Mode(1)" 0 "Not_Auto_Unlock_Mode(0)" ;
VAL_ 914 CEM_2_WiperSts 3 "ContinuousFast(3)" 2 "ContinuousSlow(2)" 1 "Auto_Or_Intermittent(1)" 0 "OFF(0)" ;
VAL_ 914 CEM_2_RainDetected 0 "Not_Detected(0)" 1 "Detected(1)" ;
VAL_ 914 CEM_2_WiperSensitivitySWSts 7 "Not_Used(7)" 6 "Not_Used(6)" 5 "High_Sens(5)" 4 "Med_High_Sens(4)" 3 "Med_Sens(3)" 2 "Med_Low_Sens(2)" 1 "Low_Sens(1)" 0 "Not_Active(0)" ;
VAL_ 914 BCM_4_RARDfstCmd 0 "Off(0)" 1 "On(1)" ;
VAL_ 914 BCM_4_FrontFogLightSts 0 "Off(0)" 1 "Active(1)" ;
VAL_ 914 CEM_2_Laser_High_Beam_Assist_Sta 0 "Close(0)" 1 "Open(1)" ;
VAL_ 914 CEM_2_ReverseGearSwitch 0 "Notactive(0)" 1 "Active(1)" ;
VAL_ 914 BCM_4_RearFogLightSts 0 "Off(0)" 1 "Active(1)" ;
VAL_ 914 CEM_2_External_WelcomelightSts 3 "OFF(3)" 2 "Mode3(2)" 1 "Mode2(1)" 0 "Mode1(0)" ;
VAL_ 914 BCM_4_Mirror_Fold_Sts 1 "Off(1)" 0 "Active(0)" ;
VAL_ 914 BCM_4_TrunkSts 0 "Close(0)" 1 "Open(1)" ;
VAL_ 914 BCM_4_LHRdoorSts 0 "Close(0)" 1 "Open(1)" ;
VAL_ 914 BCM_4_RHRDoorSts 0 "Close(0)" 1 "Open(1)" ;
VAL_ 914 CEM_2_SunRoofSts 0 "Close(0)" 1 "Open(1)" ;
VAL_ 914 BCM_4_BonnetSts 0 "Close(0)" 1 "Open(1)" ;
VAL_ 914 BCM_4_PsngrDoorSts 0 "Close(0)" 1 "Open(1)" ;
VAL_ 914 BCM_4_DriverDoorSts 0 "Close(0)" 1 "Open(1)" ;
VAL_ 914 BCM_4_FollowMeTimeSts 8 "Eight_Times(8)" 7 "Seven_Times(7)" 6 "Six_Times(6)" 5 "Five_Times(5)" 4 "Four_Times(4)" 3 "Three_Times(3)" 2 "Two_Times(2)" 1 "One_Time(1)" 0 "Not_Active(0)" ;
VAL_ 914 CEM_2_DirectionIndLeft 0 "Not_Active(0)" 1 "Active(1)" ;
VAL_ 914 CEM_2_DirectionIndRight 0 "Not_Active(0)" 1 "Active(1)" ;
VAL_ 914 BCM_4_DRLSts 0 "Off(0)" 1 "Active(1)" ;
VAL_ 914 BCM_4_LowBeamSts 0 "Off(0)" 1 "Active(1)" ;
VAL_ 914 CEM_2_Laser_LightSts 0 "Off(0)" 1 "Active(1)" ;
VAL_ 914 BCM_4_HighBeamSts 0 "Off(0)" 1 "Active(1)" ;
VAL_ 914 BCM_4_ParkTailLightSts 0 "Off(0)" 1 "Active(1)" ;
VAL_ 914 BCM_4_BrakePedalSts 1 "Applied(1)" 0 "Not applied(0)" ;
VAL_ 914 BCM_4_LHTurnlightSts 0 "Off(0)" 1 "Active(1)" ;
VAL_ 914 BCM_4_RHTurnlightSts 0 "Off(0)" 1 "Active(1)" ;
VAL_ 914 CEM_2_BlankchanginglaneSts 1 "Blanking_Not_Active(1)" 0 "Blanking_Active(0)" ;
VAL_ 914 BCM_4_KeySts 3 "Crank_ON(3)" 2 "On(2)" 1 "ACC(1)" 0 "Off(0)" ;
VAL_ 914 CEM_2_FollowMeHomeSts 1 "Close(1)" 0 "Open(0)" ;
VAL_ 914 CEM_2_KeyRemindWarning 0 "Off(0)" 1 "Active(1)" ;
VAL_ 914 BCM_4_ParkLightOnWarning 0 "Off(0)" 1 "Active(1)" ;
VAL_ 914 BCM_4_FollowMeHomeTimeSts 3 "Close(3)" 2 "60s(2)" 1 "30s(1)" ;
VAL_ 1340 RBCM_FGHeat_Request_CommandFB 1 "Active(1)" 0 "Not Active(0)" ;
VAL_ 1340 RBCM_2_RRSeatHeatVentSwSts 7 "Reserved" 6 "Reserved" 5 "Reserved" 4 "Level_3_Heat_Request" 3 "Level_2_Heat_Request" 2 "Level_1_Heat_Request" 1 "OFF" 0 "NoActive" ;
VAL_ 1340 RBCM_2_LRSeatHeatVentSwSts 7 "Reserved" 6 "Reserved" 5 "Reserved" 4 "Level_3_Heat_Request" 3 "Level_2_Heat_Request" 2 "Level_1_Heat_Request" 1 "OFF" 0 "NoActive" ;
VAL_ 1340 RBCM_MFS_ShakeSts 1 "Active(1)" 0 "Not Active(0)" ;
VAL_ 1306 CLM_2_Blower_DelaySts 1 "Active(1)" 0 "Off(0)" ;
VAL_ 1306 CEM_IPM_AC_DisplaySts 0 "Not_Active(0)" 1 "Active(1)" ;
VAL_ 1306 CLM_2_Custom_Air_Conditioning 2 "powerful(2)" 1 "comfort(1)" 0 "energy_Conservation(0)" ;
VAL_ 1306 CLM_2_Automatic_Ventilation 1 "Not_Active(1)" 0 "Active(0)" ;
VAL_ 1306 CLM_2_First_BlowingSts 1 "Active(1)" 0 "Off(0)" ;
VAL_ 1306 CEM_IPM_FRSeatHeatVentSwSts 7 "Level_3_Ventilation_Request(7)" 6 "Level_2_Ventilation_Request(6)" 5 "Level_1_Ventilation_Request(5)" 4 "Level_3_Heat_Request(4)" 3 "Level_2_Heat_Request(3)" 2 "Level_1_Heat_Request(2)" 1 "OFF(1)" 0 "NO_Request(0)" ;
VAL_ 1306 CEM_IPM_FLSeatHeatVentSwSts 7 "Level_3_Ventilation_Request(7)" 6 "Level_2_Ventilation_Request(6)" 5 "Level_1_Ventilation_Request(5)" 4 "Level_3_Heat_Request(4)" 3 "Level_2_Heat_Request(3)" 2 "Level_1_Heat_Request(2)" 1 "OFF(1)" 0 "NO_Request(0)" ;
VAL_ 1306 CEM_IPM_TempknobRollingCounter 15 "15(15)" 14 "14(14)" 13 "13(13)" 12 "12(12)" 11 "11(11)" 10 "10(10)" 0 "Not_Active(0)" ;
VAL_ 1306 CLM_2_AnionPurify 1 "Active(1)" 0 "NotActive(0)" ;
VAL_ 1306 CEM_IPM_PM25_Detect 1 "Active(1)" 0 "NotActive(0)" ;
VAL_ 1306 CLM_2_SyncSts 1 "Active(1)" 0 "NotActive(0)" ;
VAL_ 1306 CLM_2_FrontAutoACSts 1 "Active(1)" 0 "NotActive(0)" ;
VAL_ 1306 CEM_IPM_RearBlowModeSts 3 "No_Pressed(3)" 2 "Foot(2)" 1 "Face_&Foot(1)" 0 "Face(0)" ;
VAL_ 1306 CEM_IPM_RearAutoACSts 1 "Active(1)" 0 "Not_Active(0)" ;
VAL_ 1306 CEM_IPM_RearBlowSpdCtrlSts 15 "Invalid(15)" 5 "Speed_5_Request(5)" 4 "Speed_4_Request(4)" 3 "Speed_3_Request(3)" 2 "Speed_2_Request(2)" 1 "Speed_1_Request(1)" 0 "No_Request(0)" ;
VAL_ 1306 CLM_2_RearOFFsts 1 "Active(1)" 0 "Not_Active(0)" ;
VAL_ 1306 CEM_IPM_RearDefrosts 1 "Active(1)" 0 "Not_Active(0)" ;
VAL_ 1306 CLM_2_FrontOFFSts 1 "Active(1)" 0 "NotActive(0)" ;
VAL_ 1306 CLM_2_ACStatus 1 "Active(1)" 0 "NotActive(0)" ;
VAL_ 1306 CLM_2_RecyMode 3 "auto_Recycle_Request(3)" 2 "external_Recycle_Request(2)" 1 "internal_Recycle_Request(1)" 0 "no_Request(0)" ;
VAL_ 1306 CLM_2_FrontBlowModeSts 7 "No_Pressed(7)" 6 "Reserved(6)" 5 "Reserved(5)" 4 "Defrost(4)" 3 "Foot_Defrost(3)" 2 "Foot(2)" 1 "Face_Foot(1)" 0 "Face(0)" ;
VAL_ 1306 CLM_2_FrontBlowSpdCtrlsts 15 "Invalid(15)" 7 "Speed_7_Request(7)" 6 "Speed_6_Request(6)" 5 "Speed_5_Request(5)" 4 "Speed_4_Request(4)" 3 "Speed_3_Request(3)" 2 "Speed_2_Request(2)" 1 "Speed_1_Request(1)" 0 "No_Request(0)" ;
VAL_ 1381 S_RAIN 1 "TRUE(1)" 0 "FALSE_Startup(0)" ;
VAL_ 1381 S_AUTOPANEL 1 "PanelDimActivate(1)" 0 "PanelDimDeactivate_Startup(0)" ;
SIG_GROUP_ 1400 IHU_14_578 1 : SET_Lightcontrol SET_Rearfoglight SET_Tunnel_Lamp SET_Wiper_Sensitivity IHU_welcome_sound_device_switchi IHU_sound_options_signal IHU_RSeatBeltBuckleSwitch NextTrafficSts SET_Passenger_Welcome_Seat IHU_14_Set_FrontFogLights NavDistance TrafficSts IHU_14_MFS_ModeSts IHU_14_SET_DRlight;
SIG_GROUP_ 1297 IHU_16_511 1 : SET_MLSeatReq SET_MLSeat_BackReq SET_MRSeatReq SET_MRSeat_BackReq SET_MRSeat_SideslipReq SET_MRSeat_LegUDReq SET_MLSeat_HeatVent_BlowSwReq SET_MLSeat_MassageStsReq SET_MLSeat_MassageVibrationReq SET_MLSeat_MassageModeReq SET_MRSeat_HeatVent_BlowSwReq SET_MRSeat_MassageStsReq SET_MRSeat_MassageVibrationReq SET_MRSeat_MassageModeReq SET_MRSeat_ZerogravityModeReq;
SIG_GROUP_ 1298 IHU_CGW_512 1 : SET_DriverSeat_MassageStsReq SET_DriverSeat_MassageVibrationR SET_DriverSeat_MassageModeReq SET_PassengerSeat_MassageModeReq SET_DriverSeat_HeatVent_BlowSwRe SET_PassengerSeat_HeatVent_BlowS SET_RestArea;
SIG_GROUP_ 1416 IHU_24_0x588_Group 1 : RCTB_OnOffSt RCW_OnOffSt DCLC_Switch ELK_Switch IHU_11_TSISwtSet IESSwtSet Ready2GoSwitch;
SIG_GROUP_ 1414 IHU_AMP_0x586_group 1 : REQ_AMPA2BPhoneSound Set_AMPSpeedVolume Set_AMPMute REQ_AMPA2BNaviSound REQ_AMPA2BVRSound REQ_AMPA2BTTSSound REQ_AMPA2BKeyTone IHU_19_REQ_AMPA2BESESound IHU_19_REQ_AMPA2BMediSound IHU_19_Set_AMPBTMediVol IHU_19_Set_AMPWelVol IHU_19_Set_AMPESEVol IHU_19_SetIHUAlarm REQ_AMPA2BMediaSound IHU_19_Set_HdrestSpkrMod;
SIG_GROUP_ 1413 IHU_AMP_0x585_group 1 : Set_AMPNaviVolume Set_AMPVRVolume Set_AMPMediaVolume Set_AMPPhoneVolume Set_AMPSoundFocus Set_AMPDefaultVolume Set_AMPRestoreDefaults Set_AMPSoundEffect Set_AMPSoundEffectBass Set_AMPSoundEffectMidrange Set_AMPSoundEffectTreble Set_AMPSoundFieldBalance Set_AMPSoundFieldFader Set_AMPLiveAcoustics Set_AMPLoudness Set_AMPAlarmVolume Set_AMPKeyTone;
SIG_GROUP_ 1114 IHU_APA_0x45A_group 1 : IHU_APAKeySts CalibrationReq TouchEvt NaviBtnPressInputValueY NaviBtnPressInputValueX IHUDisplayAVMOff AVMSwt;
SIG_GROUP_ 1276 IHU_11_0x4FC_group 1 : IHU_11_TLISwtSet IHU_11_WarnModSwtSet IHU_11_ELKSwtSet IHU_11_LDWLDPSnvtySet IHU_11_LDPSwtSet IHU_11_LDWSwtSet IHU_11_TSISwtSet IHU_11_IESSwtSet IHU_11_DAISwtSet IHU_11_SCFSwtSet IHU_11_SLASwtSet IHU_11_TJAICAExitTextInfoSwtSet IHU_11_FCWSwtSet IHU_11_FCWSnvtySet IHU_11_AEBSwtSet IHU_11_HMASwtSet;
